VERSION ""

NS_ :

BS_:

BU_: CH DIPF DIPR ETH FC HVI HVS PARTY SDCV VEH VIRT

BO_ 1815 RCM_imuOffsets: 7 CH
 SG_ RCM_rollRateOffset m0 : 40|16@1- (0.0001,0.0) [-0.126|0.126] "rad/s"  gtw
 SG_ RCM_verticalAccelOffset m1 : 40|16@1- (0.00125,0.0) [-2.52|2.52] "m/s^2"  gtw
 SG_ RCM_lateralAccelOffset m1 : 24|16@1- (0.00125,0.0) [-2.52|2.52] "m/s^2"  gtw
 SG_ RCM_pitchRateOffset m0 : 24|16@1- (0.0001,0.0) [-0.126|0.126] "rad/s"  gtw
 SG_ RCM_yawRateOffset m0 : 8|16@1- (0.0001,0.0) [-0.126|0.126] "rad/s"  gtw
 SG_ RCM_longitudinalAccelOffset m1 : 8|16@1- (0.00125,0.0) [-2.52|2.52] "m/s^2"  gtw
 SG_ RCM_imuOffsetsIndex M : 0|1@1+ (1,0) [0|1] ""  X

BO_ 981 ESP_alertMatrix: 8 CH
 SG_ ESP_a120_rmiActive m1 : 63|1@1+ (1,0) [0|1] ""  gtw
 SG_ ESP_a180_IBSTparty2Checksum m2 : 63|1@1+ (1,0) [0|1] ""  gtw
 SG_ ESP_a060_ReLWSSWrongSensorType m0 : 63|1@1+ (1,0) [0|1] ""  gtw
 SG_ ESP_a240_LVPowerStateTimeout m3 : 63|1@1+ (1,0) [0|1] ""  gtw
 SG_ ESP_a179_IBSTparty2Timeout m2 : 62|1@1+ (1,0) [0|1] ""  gtw
 SG_ ESP_a119_hbbActive m1 : 62|1@1+ (1,0) [0|1] ""  gtw
 SG_ ESP_a059_ReLWSSNoPulsesDetected m0 : 62|1@1+ (1,0) [0|1] ""  gtw
 SG_ ESP_a239_UIodoDLC m3 : 62|1@1+ (1,0) [0|1] ""  gtw
 SG_ ESP_a118_hfcActive m1 : 61|1@1+ (1,0) [0|1] ""  gtw
 SG_ ESP_a058_ReLWSSLostSignal m0 : 61|1@1+ (1,0) [0|1] ""  gtw
 SG_ ESP_a238_UIodoTimeout m3 : 61|1@1+ (1,0) [0|1] ""  gtw
 SG_ ESP_a178_IBSTOutputRodActInvalid m2 : 61|1@1+ (1,0) [0|1] ""  gtw
 SG_ ESP_a237_vdcCommandStateInvalid m3 : 60|1@1+ (1,0) [0|1] ""  gtw
 SG_ ESP_a117_hbaActive m1 : 60|1@1+ (1,0) [0|1] ""  gtw
 SG_ ESP_a177_IBSTOutputRodDrvInvalid m2 : 60|1@1+ (1,0) [0|1] ""  gtw
 SG_ ESP_a057_ReLWSSTooManyPulses m0 : 60|1@1+ (1,0) [0|1] ""  gtw
 SG_ ESP_a056_ReLWSSMaxSpeedExceeded m0 : 59|1@1+ (1,0) [0|1] ""  gtw
 SG_ ESP_a176_IBSTEBRNotAvailable m2 : 59|1@1+ (1,0) [0|1] ""  gtw
 SG_ ESP_a236_ebrCommandStateInvalid m3 : 59|1@1+ (1,0) [0|1] ""  gtw
 SG_ ESP_a116_tsmActive m1 : 59|1@1+ (1,0) [0|1] ""  gtw
 SG_ ESP_a175_IBSTparty1Counter m2 : 58|1@1+ (1,0) [0|1] ""  gtw
 SG_ ESP_a115_ebdActive m1 : 58|1@1+ (1,0) [0|1] ""  gtw
 SG_ ESP_a055_ReLWSSLineInterruption m0 : 58|1@1+ (1,0) [0|1] ""  gtw
 SG_ ESP_a235_PMstate2Counter m3 : 58|1@1+ (1,0) [0|1] ""  gtw
 SG_ ESP_a234_PMstate2DLC m3 : 57|1@1+ (1,0) [0|1] ""  gtw
 SG_ ESP_a054_ReLWSSShortTo12V m0 : 57|1@1+ (1,0) [0|1] ""  gtw
 SG_ ESP_a174_IBSTparty1Checksum m2 : 57|1@1+ (1,0) [0|1] ""  gtw
 SG_ ESP_a114_tvdcActive m1 : 57|1@1+ (1,0) [0|1] ""  gtw
 SG_ ESP_a113_btcActive m1 : 56|1@1+ (1,0) [0|1] ""  gtw
 SG_ ESP_a233_PMstate2Checksum m3 : 56|1@1+ (1,0) [0|1] ""  gtw
 SG_ ESP_a053_ReLWSSOpenOrShortToGnd m0 : 56|1@1+ (1,0) [0|1] ""  gtw
 SG_ ESP_a173_IBSTparty1DLC m2 : 56|1@1+ (1,0) [0|1] ""  gtw
 SG_ ESP_a172_IBSTparty1Timeout m2 : 55|1@1+ (1,0) [0|1] ""  gtw
 SG_ ESP_a052_FrRWSSGeneralFault m0 : 55|1@1+ (1,0) [0|1] ""  gtw
 SG_ ESP_a112_espActive m1 : 55|1@1+ (1,0) [0|1] ""  gtw
 SG_ ESP_a232_PMstate2Timeout m3 : 55|1@1+ (1,0) [0|1] ""  gtw
 SG_ ESP_a051_FrRWSSSupplyShortToGnd m0 : 54|1@1+ (1,0) [0|1] ""  gtw
 SG_ ESP_a111_absActive m1 : 54|1@1+ (1,0) [0|1] ""  gtw
 SG_ ESP_a231_storedVINMismatch m3 : 54|1@1+ (1,0) [0|1] ""  gtw
 SG_ ESP_a171_axImplausible m2 : 54|1@1+ (1,0) [0|1] ""  gtw
 SG_ ESP_a110_rollerBenchActive m1 : 53|1@1+ (1,0) [0|1] ""  gtw
 SG_ ESP_a050_FrRWSSLargeAirGap m0 : 53|1@1+ (1,0) [0|1] ""  gtw
 SG_ ESP_a230_vinNotLearned m3 : 53|1@1+ (1,0) [0|1] ""  gtw
 SG_ ESP_a170_axSignalFrozen m2 : 53|1@1+ (1,0) [0|1] ""  gtw
 SG_ ESP_a229_GTWvinDLC m3 : 52|1@1+ (1,0) [0|1] ""  gtw
 SG_ ESP_a169_axOffsetExceeded m2 : 52|1@1+ (1,0) [0|1] ""  gtw
 SG_ ESP_a109_reserved109 m1 : 52|1@1+ (1,0) [0|1] ""  gtw
 SG_ ESP_a049_FrRWSSDirectionFault m0 : 52|1@1+ (1,0) [0|1] ""  gtw
 SG_ ESP_a048_FrRWSSVDiffFault m0 : 51|1@1+ (1,0) [0|1] ""  gtw
 SG_ ESP_a228_GTWvinTimeout m3 : 51|1@1+ (1,0) [0|1] ""  gtw
 SG_ ESP_a108_reserved108 m1 : 51|1@1+ (1,0) [0|1] ""  gtw
 SG_ ESP_a168_axRangeExceeded m2 : 51|1@1+ (1,0) [0|1] ""  gtw
 SG_ ESP_a047_FrRWSSSignalNoise m0 : 50|1@1+ (1,0) [0|1] ""  gtw
 SG_ ESP_a167_axSignalFault m2 : 50|1@1+ (1,0) [0|1] ""  gtw
 SG_ ESP_a107_reserved107 m1 : 50|1@1+ (1,0) [0|1] ""  gtw
 SG_ ESP_a227_bdwRequestActiveInvalid m3 : 50|1@1+ (1,0) [0|1] ""  gtw
 SG_ ESP_a106_vdcActuatorFault m1 : 49|1@1+ (1,0) [0|1] ""  gtw
 SG_ ESP_a226_bdwRequestInvalid m3 : 49|1@1+ (1,0) [0|1] ""  gtw
 SG_ ESP_a166_axSensorNotAvailable m2 : 49|1@1+ (1,0) [0|1] ""  gtw
 SG_ ESP_a046_FrRWSSWrongSensorType m0 : 49|1@1+ (1,0) [0|1] ""  gtw
 SG_ ESP_a165_axInvalidValue m2 : 48|1@1+ (1,0) [0|1] ""  gtw
 SG_ ESP_a045_FrRWSSNoPulsesDetected m0 : 48|1@1+ (1,0) [0|1] ""  gtw
 SG_ ESP_a225_configMismatch m3 : 48|1@1+ (1,0) [0|1] ""  gtw
 SG_ ESP_a105_ebrFault m1 : 48|1@1+ (1,0) [0|1] ""  gtw
 SG_ ESP_a104_hbcEnabled m1 : 47|1@1+ (1,0) [0|1] ""  gtw
 SG_ ESP_a224_DIvdcRightCounter m3 : 47|1@1+ (1,0) [0|1] ""  gtw
 SG_ ESP_a044_FrRWSSLostSignal m0 : 47|1@1+ (1,0) [0|1] ""  gtw
 SG_ ESP_a164_axInitFault m2 : 47|1@1+ (1,0) [0|1] ""  gtw
 SG_ ESP_a103_stabilityControlFault m1 : 46|1@1+ (1,0) [0|1] ""  gtw
 SG_ ESP_a043_FrRWSSTooManyPulses m0 : 46|1@1+ (1,0) [0|1] ""  gtw
 SG_ ESP_a163_axMaxLatency m2 : 46|1@1+ (1,0) [0|1] ""  gtw
 SG_ ESP_a223_DIvdcRightChecksum m3 : 46|1@1+ (1,0) [0|1] ""  gtw
 SG_ ESP_a162_ayImplausible m2 : 45|1@1+ (1,0) [0|1] ""  gtw
 SG_ ESP_a102_absFault m1 : 45|1@1+ (1,0) [0|1] ""  gtw
 SG_ ESP_a042_FrRWSSMaxSpeedExceeded m0 : 45|1@1+ (1,0) [0|1] ""  gtw
 SG_ ESP_a222_DIvdcRightDLC m3 : 45|1@1+ (1,0) [0|1] ""  gtw
 SG_ ESP_a221_DIvdcRightTimeout m3 : 44|1@1+ (1,0) [0|1] ""  gtw
 SG_ ESP_a101_ebdFault m1 : 44|1@1+ (1,0) [0|1] ""  gtw
 SG_ ESP_a041_FrRWSSLineInterruption m0 : 44|1@1+ (1,0) [0|1] ""  gtw
 SG_ ESP_a161_ayOffsetExceeded m2 : 44|1@1+ (1,0) [0|1] ""  gtw
 SG_ ESP_a220_DIvdcLeftCounter m3 : 43|1@1+ (1,0) [0|1] ""  gtw
 SG_ ESP_a040_FrRWSSShortTo12V m0 : 43|1@1+ (1,0) [0|1] ""  gtw
 SG_ ESP_a100_brakeTempModelDisabled m1 : 43|1@1+ (1,0) [0|1] ""  gtw
 SG_ ESP_a160_ayRangeExceeded m2 : 43|1@1+ (1,0) [0|1] ""  gtw
 SG_ ESP_a099_brakeTempModelOverheat m1 : 42|1@1+ (1,0) [0|1] ""  gtw
 SG_ ESP_a219_DIvdcLeftChecksum m3 : 42|1@1+ (1,0) [0|1] ""  gtw
 SG_ ESP_a039_FrRWSSOpenOrShortToGnd m0 : 42|1@1+ (1,0) [0|1] ""  gtw
 SG_ ESP_a159_aySignalFault m2 : 42|1@1+ (1,0) [0|1] ""  gtw
 SG_ ESP_a158_aySensorNotAvailable m2 : 41|1@1+ (1,0) [0|1] ""  gtw
 SG_ ESP_a098_vdcRefSpeedNotInit m1 : 41|1@1+ (1,0) [0|1] ""  gtw
 SG_ ESP_a218_DIvdcLeftDLC m3 : 41|1@1+ (1,0) [0|1] ""  gtw
 SG_ ESP_a038_FrLWSSGeneralFault m0 : 41|1@1+ (1,0) [0|1] ""  gtw
 SG_ ESP_a157_ayInvalidValue m2 : 40|1@1+ (1,0) [0|1] ""  gtw
 SG_ ESP_a217_DIvdcLeftTimeout m3 : 40|1@1+ (1,0) [0|1] ""  gtw
 SG_ ESP_a097_tcsRefSpeedNotInit m1 : 40|1@1+ (1,0) [0|1] ""  gtw
 SG_ ESP_a037_FrLWSSSupplyShortToGnd m0 : 40|1@1+ (1,0) [0|1] ""  gtw
 SG_ ESP_a096_chassisBusPassive m1 : 39|1@1+ (1,0) [0|1] ""  gtw
 SG_ ESP_a216_DISTorqueActualInvalid m3 : 39|1@1+ (1,0) [0|1] ""  gtw
 SG_ ESP_a156_ayInitFault m2 : 39|1@1+ (1,0) [0|1] ""  gtw
 SG_ ESP_a036_FrLWSSLargeAirGap m0 : 39|1@1+ (1,0) [0|1] ""  gtw
 SG_ ESP_a035_FrLWSSDirectionFault m0 : 38|1@1+ (1,0) [0|1] ""  gtw
 SG_ ESP_a095_chassisBusOff m1 : 38|1@1+ (1,0) [0|1] ""  gtw
 SG_ ESP_a215_DISRPMInvalid m3 : 38|1@1+ (1,0) [0|1] ""  gtw
 SG_ ESP_a155_ayMaxLatency m2 : 38|1@1+ (1,0) [0|1] ""  gtw
 SG_ ESP_a034_FrLWSSVDiffFault m0 : 37|1@1+ (1,0) [0|1] ""  gtw
 SG_ ESP_a214_DISTorqueCommandInvalid m3 : 37|1@1+ (1,0) [0|1] ""  gtw
 SG_ ESP_a094_partyBusPassive m1 : 37|1@1+ (1,0) [0|1] ""  gtw
 SG_ ESP_a154_RCMInertial2Counter m2 : 37|1@1+ (1,0) [0|1] ""  gtw
 SG_ ESP_a153_RCMInertial2Checksum m2 : 36|1@1+ (1,0) [0|1] ""  gtw
 SG_ ESP_a093_partyBusOff m1 : 36|1@1+ (1,0) [0|1] ""  gtw
 SG_ ESP_a033_FrLWSSSignalNoise m0 : 36|1@1+ (1,0) [0|1] ""  gtw
 SG_ ESP_a213_DIStorqueCounter m3 : 36|1@1+ (1,0) [0|1] ""  gtw
 SG_ ESP_a032_FrLWSSWrongSensorType m0 : 35|1@1+ (1,0) [0|1] ""  gtw
 SG_ ESP_a092_CANOvervoltage m1 : 35|1@1+ (1,0) [0|1] ""  gtw
 SG_ ESP_a152_RCMInertial2DLC m2 : 35|1@1+ (1,0) [0|1] ""  gtw
 SG_ ESP_a212_DIStorqueChecksum m3 : 35|1@1+ (1,0) [0|1] ""  gtw
 SG_ ESP_a031_FrLWSSNoPulsesDetected m0 : 34|1@1+ (1,0) [0|1] ""  gtw
 SG_ ESP_a091_CANUndervoltage m1 : 34|1@1+ (1,0) [0|1] ""  gtw
 SG_ ESP_a151_RCMInertial2Timeout m2 : 34|1@1+ (1,0) [0|1] ""  gtw
 SG_ ESP_a211_DIStorqueDLC m3 : 34|1@1+ (1,0) [0|1] ""  gtw
 SG_ ESP_a030_FrLWSSLostSignal m0 : 33|1@1+ (1,0) [0|1] ""  gtw
 SG_ ESP_a090_vdcContinuousControl m1 : 33|1@1+ (1,0) [0|1] ""  gtw
 SG_ ESP_a210_DIStorqueTimeout m3 : 33|1@1+ (1,0) [0|1] ""  gtw
 SG_ ESP_a150_yawImplausible m2 : 33|1@1+ (1,0) [0|1] ""  gtw
 SG_ ESP_a149_yawInvalidSign m2 : 32|1@1+ (1,0) [0|1] ""  gtw
 SG_ ESP_a089_absNoPressureIncrease m1 : 32|1@1+ (1,0) [0|1] ""  gtw
 SG_ ESP_a209_DITorqueActualInvalid m3 : 32|1@1+ (1,0) [0|1] ""  gtw
 SG_ ESP_a029_FrLWSSTooManyPulses m0 : 32|1@1+ (1,0) [0|1] ""  gtw
 SG_ ESP_a148_yawSignalFault m2 : 31|1@1+ (1,0) [0|1] ""  gtw
 SG_ ESP_a208_DIRPMInvalid m3 : 31|1@1+ (1,0) [0|1] ""  gtw
 SG_ ESP_a088_absContinuousControl m1 : 31|1@1+ (1,0) [0|1] ""  gtw
 SG_ ESP_a028_FrLWSSMaxSpeedExceeded m0 : 31|1@1+ (1,0) [0|1] ""  gtw
 SG_ ESP_a207_DITorqueCommandInvalid m3 : 30|1@1+ (1,0) [0|1] ""  gtw
 SG_ ESP_a087_BrakeSwitchImplausible3 m1 : 30|1@1+ (1,0) [0|1] ""  gtw
 SG_ ESP_a027_FrLWSSLineInterruption m0 : 30|1@1+ (1,0) [0|1] ""  gtw
 SG_ ESP_a147_yawSensorNotAvailable m2 : 30|1@1+ (1,0) [0|1] ""  gtw
 SG_ ESP_a146_yawInvalidValue m2 : 29|1@1+ (1,0) [0|1] ""  gtw
 SG_ ESP_a026_FrLWSSShortTo12V m0 : 29|1@1+ (1,0) [0|1] ""  gtw
 SG_ ESP_a086_BrakeSwitchImplausible1 m1 : 29|1@1+ (1,0) [0|1] ""  gtw
 SG_ ESP_a206_DItorqueCounter m3 : 29|1@1+ (1,0) [0|1] ""  gtw
 SG_ ESP_a085_BrakeSwitchStuckHigh m1 : 28|1@1+ (1,0) [0|1] ""  gtw
 SG_ ESP_a205_DItorqueChecksum m3 : 28|1@1+ (1,0) [0|1] ""  gtw
 SG_ ESP_a025_FrLWSSOpenOrShortToGnd m0 : 28|1@1+ (1,0) [0|1] ""  gtw
 SG_ ESP_a145_yawInitFault m2 : 28|1@1+ (1,0) [0|1] ""  gtw
 SG_ ESP_a084_BrakeFluidReservoirLow m1 : 27|1@1+ (1,0) [0|1] ""  gtw
 SG_ ESP_a144_yawMaxLatency m2 : 27|1@1+ (1,0) [0|1] ""  gtw
 SG_ ESP_a024_WSSReverseCurrent m0 : 27|1@1+ (1,0) [0|1] ""  gtw
 SG_ ESP_a204_DItorqueDLC m3 : 27|1@1+ (1,0) [0|1] ""  gtw
 SG_ ESP_a083_PMCSensorFault m1 : 26|1@1+ (1,0) [0|1] ""  gtw
 SG_ ESP_a143_RCMInertial1Counter m2 : 26|1@1+ (1,0) [0|1] ""  gtw
 SG_ ESP_a203_DItorqueTimeout m3 : 26|1@1+ (1,0) [0|1] ""  gtw
 SG_ ESP_a263_epblStatusCounter m4 : 26|1@1+ (1,0) [0|1] ""  gtw
 SG_ ESP_a023_WSSSeveralSuspected m0 : 26|1@1+ (1,0) [0|1] ""  gtw
 SG_ ESP_a142_RCMInertial1Checksum m2 : 25|1@1+ (1,0) [0|1] ""  gtw
 SG_ ESP_a262_epblStatusDLC m4 : 25|1@1+ (1,0) [0|1] ""  gtw
 SG_ ESP_a082_PMCSensorOffsetHigh m1 : 25|1@1+ (1,0) [0|1] ""  gtw
 SG_ ESP_a202_accelPedalInvalid m3 : 25|1@1+ (1,0) [0|1] ""  gtw
 SG_ ESP_a022_WSSDirectionFault m0 : 25|1@1+ (1,0) [0|1] ""  gtw
 SG_ ESP_a261_epblStatusChecksum m4 : 24|1@1+ (1,0) [0|1] ""  gtw
 SG_ ESP_a141_RCMInertial1DLC m2 : 24|1@1+ (1,0) [0|1] ""  gtw
 SG_ ESP_a081_PressureSensorShort m1 : 24|1@1+ (1,0) [0|1] ""  gtw
 SG_ ESP_a021_WSSGeneralVDiffFault m0 : 24|1@1+ (1,0) [0|1] ""  gtw
 SG_ ESP_a201_reverseGearStuckLow m3 : 24|1@1+ (1,0) [0|1] ""  gtw
 SG_ ESP_a080_ReRWSSGeneralFault m1 : 23|1@1+ (1,0) [0|1] ""  gtw
 SG_ ESP_a020_WSSGenericTempFault m0 : 23|1@1+ (1,0) [0|1] ""  gtw
 SG_ ESP_a260_epblStatusTimeout m4 : 23|1@1+ (1,0) [0|1] ""  gtw
 SG_ ESP_a200_reverseGearStuckHigh m3 : 23|1@1+ (1,0) [0|1] ""  gtw
 SG_ ESP_a140_RCMInertial1Timeout m2 : 23|1@1+ (1,0) [0|1] ""  gtw
 SG_ ESP_a259_epbmStatusCounter m4 : 22|1@1+ (1,0) [0|1] ""  gtw
 SG_ ESP_a199_DIsystemStatusCounter m3 : 22|1@1+ (1,0) [0|1] ""  gtw
 SG_ ESP_a139_steeringAngleWrongSign m2 : 22|1@1+ (1,0) [0|1] ""  gtw
 SG_ ESP_a019_WSSSignRearAxle m0 : 22|1@1+ (1,0) [0|1] ""  gtw
 SG_ ESP_a079_ReRWSSSupplyShortToGnd m1 : 22|1@1+ (1,0) [0|1] ""  gtw
 SG_ ESP_a138_steeringAngleImplaus m2 : 21|1@1+ (1,0) [0|1] ""  gtw
 SG_ ESP_a078_ReRWSSLargeAirGap m1 : 21|1@1+ (1,0) [0|1] ""  gtw
 SG_ ESP_a198_DIsystemStatusChecksum m3 : 21|1@1+ (1,0) [0|1] ""  gtw
 SG_ ESP_a018_WSSSignFrontAxle m0 : 21|1@1+ (1,0) [0|1] ""  gtw
 SG_ ESP_a258_epbmStatusDLC m4 : 21|1@1+ (1,0) [0|1] ""  gtw
 SG_ ESP_a077_ReRWSSDirectionFault m1 : 20|1@1+ (1,0) [0|1] ""  gtw
 SG_ ESP_a197_DIsystemStatusDLC m3 : 20|1@1+ (1,0) [0|1] ""  gtw
 SG_ ESP_a137_steeringOffsetTooLarge m2 : 20|1@1+ (1,0) [0|1] ""  gtw
 SG_ ESP_a017_netOvervoltage m0 : 20|1@1+ (1,0) [0|1] ""  gtw
 SG_ ESP_a257_epbmStatusChecksum m4 : 20|1@1+ (1,0) [0|1] ""  gtw
 SG_ ESP_a196_DIsystemStatusTimeout m3 : 19|1@1+ (1,0) [0|1] ""  gtw
 SG_ ESP_a136_steeringAngleFrozen m2 : 19|1@1+ (1,0) [0|1] ""  gtw
 SG_ ESP_a016_12VSystemOvervoltage m0 : 19|1@1+ (1,0) [0|1] ""  gtw
 SG_ ESP_a256_epbmStatusTimeout m4 : 19|1@1+ (1,0) [0|1] ""  gtw
 SG_ ESP_a076_ReRWSSVDiffFault m1 : 19|1@1+ (1,0) [0|1] ""  gtw
 SG_ ESP_a015_12VSupplyOvervoltage m0 : 18|1@1+ (1,0) [0|1] ""  gtw
 SG_ ESP_a135_steeringAngleNoCenter m2 : 18|1@1+ (1,0) [0|1] ""  gtw
 SG_ ESP_a195_ptcStateInvalid m3 : 18|1@1+ (1,0) [0|1] ""  gtw
 SG_ ESP_a255_vdcWhlSlipLimReRInvalid m4 : 18|1@1+ (1,0) [0|1] ""  gtw
 SG_ ESP_a075_ReRWSSSignalNoise m1 : 18|1@1+ (1,0) [0|1] ""  gtw
 SG_ ESP_a074_ReRWSSWrongSensorType m1 : 17|1@1+ (1,0) [0|1] ""  gtw
 SG_ ESP_a254_vdcWhlSlipLimReLInvalid m4 : 17|1@1+ (1,0) [0|1] ""  gtw
 SG_ ESP_a134_steeringAngleInvalid m2 : 17|1@1+ (1,0) [0|1] ""  gtw
 SG_ ESP_a014_WSSSupplyUndervoltage m0 : 17|1@1+ (1,0) [0|1] ""  gtw
 SG_ ESP_a194_DIchassiControlCounter m3 : 17|1@1+ (1,0) [0|1] ""  gtw
 SG_ ESP_a253_vdcWhlSlipLimFrRInvalid m4 : 16|1@1+ (1,0) [0|1] ""  gtw
 SG_ ESP_a073_ReRWSSNoPulsesDetected m1 : 16|1@1+ (1,0) [0|1] ""  gtw
 SG_ ESP_a133_EPAS3PsysStatusCounter m2 : 16|1@1+ (1,0) [0|1] ""  gtw
 SG_ ESP_a193_DIchassiControlChecksum m3 : 16|1@1+ (1,0) [0|1] ""  gtw
 SG_ ESP_a013_valveRelayUndervoltage m0 : 16|1@1+ (1,0) [0|1] ""  gtw
 SG_ ESP_a072_ReRWSSLostSignal m1 : 15|1@1+ (1,0) [0|1] ""  gtw
 SG_ ESP_a012_netUndervoltage m0 : 15|1@1+ (1,0) [0|1] ""  gtw
 SG_ ESP_a132_EPAS3PsysStatusChecksum m2 : 15|1@1+ (1,0) [0|1] ""  gtw
 SG_ ESP_a252_vdcWhlSlipLimFrLInvalid m4 : 15|1@1+ (1,0) [0|1] ""  gtw
 SG_ ESP_a192_DIchassiControlDLC m3 : 15|1@1+ (1,0) [0|1] ""  gtw
 SG_ ESP_a131_EPAS3PsysStatusDLC m2 : 14|1@1+ (1,0) [0|1] ""  gtw
 SG_ ESP_a251_vdcBrkeTrqTarReRInvalid m4 : 14|1@1+ (1,0) [0|1] ""  gtw
 SG_ ESP_a191_DIchassiControlTimeout m3 : 14|1@1+ (1,0) [0|1] ""  gtw
 SG_ ESP_a071_ReRWSSTooManyPulses m1 : 14|1@1+ (1,0) [0|1] ""  gtw
 SG_ ESP_a011_12VSystemUndervoltage m0 : 14|1@1+ (1,0) [0|1] ""  gtw
 SG_ ESP_a070_ReRWSSMaxSpeedExceeded m1 : 13|1@1+ (1,0) [0|1] ""  gtw
 SG_ ESP_a010_12VUndervoltage m0 : 13|1@1+ (1,0) [0|1] ""  gtw
 SG_ ESP_a250_vdcBrkeTrqTarReLInvalid m4 : 13|1@1+ (1,0) [0|1] ""  gtw
 SG_ ESP_a190_DIbtcRequestCounter m3 : 13|1@1+ (1,0) [0|1] ""  gtw
 SG_ ESP_a130_EPAS3PsysStatusTimeout m2 : 13|1@1+ (1,0) [0|1] ""  gtw
 SG_ ESP_a189_DIbtcRequestChecksum m3 : 12|1@1+ (1,0) [0|1] ""  gtw
 SG_ ESP_a069_ReRWSSLineInterruption m1 : 12|1@1+ (1,0) [0|1] ""  gtw
 SG_ ESP_a009_12VHardUndervoltage m0 : 12|1@1+ (1,0) [0|1] ""  gtw
 SG_ ESP_a129_reserved129 m2 : 12|1@1+ (1,0) [0|1] ""  gtw
 SG_ ESP_a249_vdcBrkeTrqTarFrRInvalid m4 : 12|1@1+ (1,0) [0|1] ""  gtw
 SG_ ESP_a248_vdcBrkeTrqTarFrLInvalid m4 : 11|1@1+ (1,0) [0|1] ""  gtw
 SG_ ESP_a188_DIbtcRequestDLC m3 : 11|1@1+ (1,0) [0|1] ""  gtw
 SG_ ESP_a008_pumpMotor12VsupplyLow m0 : 11|1@1+ (1,0) [0|1] ""  gtw
 SG_ ESP_a128_reserved128 m2 : 11|1@1+ (1,0) [0|1] ""  gtw
 SG_ ESP_a068_ReRWSSShortTo12V m1 : 11|1@1+ (1,0) [0|1] ""  gtw
 SG_ ESP_a067_ReRWSSOpenOrShortToGnd m1 : 10|1@1+ (1,0) [0|1] ""  gtw
 SG_ ESP_a007_pumpMotorFault m0 : 10|1@1+ (1,0) [0|1] ""  gtw
 SG_ ESP_a187_DIbtcRequestTimeout m3 : 10|1@1+ (1,0) [0|1] ""  gtw
 SG_ ESP_a247_VCFRONTsensorDLC m4 : 10|1@1+ (1,0) [0|1] ""  gtw
 SG_ ESP_a127_reserved127 m2 : 10|1@1+ (1,0) [0|1] ""  gtw
 SG_ ESP_a186_IBSTBrakeAppliedInvalid m3 : 9|1@1+ (1,0) [0|1] ""  gtw
 SG_ ESP_a066_ReLWSSGeneralFault m1 : 9|1@1+ (1,0) [0|1] ""  gtw
 SG_ ESP_a246_VCFRONTsensorTimeout m4 : 9|1@1+ (1,0) [0|1] ""  gtw
 SG_ ESP_a126_reserved126 m2 : 9|1@1+ (1,0) [0|1] ""  gtw
 SG_ ESP_a006_USVValvesFault m0 : 9|1@1+ (1,0) [0|1] ""  gtw
 SG_ ESP_a245_LVGoingDownStateInvalid m4 : 8|1@1+ (1,0) [0|1] ""  gtw
 SG_ ESP_a065_ReLWSSSupplyShortToGnd m1 : 8|1@1+ (1,0) [0|1] ""  gtw
 SG_ ESP_a005_HSVValvesFault m0 : 8|1@1+ (1,0) [0|1] ""  gtw
 SG_ ESP_a125_reserved125 m2 : 8|1@1+ (1,0) [0|1] ""  gtw
 SG_ ESP_a185_IBSTFeedforwardBackup m3 : 8|1@1+ (1,0) [0|1] ""  gtw
 SG_ ESP_a244_LVOffStateInvalid m4 : 7|1@1+ (1,0) [0|1] ""  gtw
 SG_ ESP_a004_inletValvesFault m0 : 7|1@1+ (1,0) [0|1] ""  gtw
 SG_ ESP_a064_ReLWSSLargeAirGap m1 : 7|1@1+ (1,0) [0|1] ""  gtw
 SG_ ESP_a184_IBSTpRunoutInvalid m3 : 7|1@1+ (1,0) [0|1] ""  gtw
 SG_ ESP_a124_ebrSkidActive m2 : 7|1@1+ (1,0) [0|1] ""  gtw
 SG_ ESP_a063_ReLWSSDirectionFault m1 : 6|1@1+ (1,0) [0|1] ""  gtw
 SG_ ESP_a243_LVPowerStateCounter m4 : 6|1@1+ (1,0) [0|1] ""  gtw
 SG_ ESP_a003_outletValvesFault m0 : 6|1@1+ (1,0) [0|1] ""  gtw
 SG_ ESP_a123_ebrActive m2 : 6|1@1+ (1,0) [0|1] ""  gtw
 SG_ ESP_a183_IBSTStatusOff m3 : 6|1@1+ (1,0) [0|1] ""  gtw
 SG_ ESP_a062_ReLWSSVDiffFault m1 : 5|1@1+ (1,0) [0|1] ""  gtw
 SG_ ESP_a182_IBSTparty2Counter m3 : 5|1@1+ (1,0) [0|1] ""  gtw
 SG_ ESP_a002_valvesGenericFault m0 : 5|1@1+ (1,0) [0|1] ""  gtw
 SG_ ESP_a122_bdwActive m2 : 5|1@1+ (1,0) [0|1] ""  gtw
 SG_ ESP_a242_LVPowerStateDLC m4 : 5|1@1+ (1,0) [0|1] ""  gtw
 SG_ ESP_a001_ecuGenericFault m0 : 4|1@1+ (1,0) [0|1] ""  gtw
 SG_ ESP_a121_regenTcActive m2 : 4|1@1+ (1,0) [0|1] ""  gtw
 SG_ ESP_a241_LVPowerStateChecksum m4 : 4|1@1+ (1,0) [0|1] ""  gtw
 SG_ ESP_a061_ReLWSSSignalNoise m1 : 4|1@1+ (1,0) [0|1] ""  gtw
 SG_ ESP_a181_IBSTparty2DLC m3 : 4|1@1+ (1,0) [0|1] ""  gtw
 SG_ ESP_matrixIndex M : 0|4@1+ (1,0) [0|15] ""  gtw

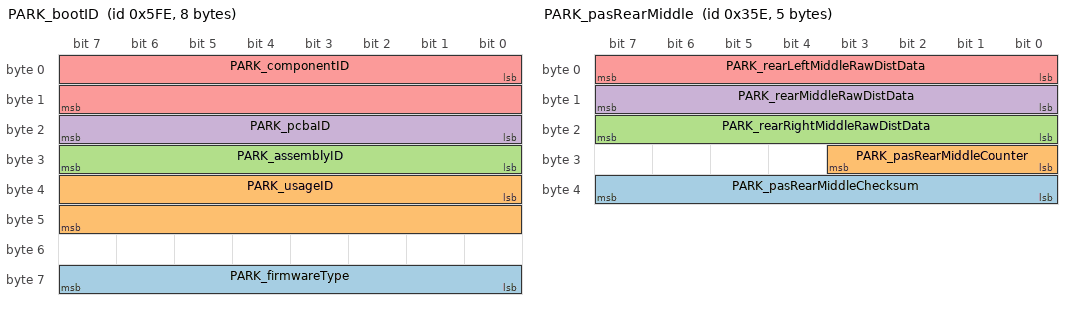
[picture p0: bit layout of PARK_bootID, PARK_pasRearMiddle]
BO_ 1534 PARK_bootID: 8 CH
 SG_ PARK_firmwareType : 56|8@1+ (1,0) [0|255] ""  X
 SG_ PARK_usageID : 32|16@1+ (1,0) [0|65535] ""  X
 SG_ PARK_assemblyID : 24|8@1+ (1,0) [0|255] ""  X
 SG_ PARK_pcbaID : 16|8@1+ (1,0) [0|255] ""  X
 SG_ PARK_componentID : 0|16@1+ (1,0) [0|65535] ""  X

BO_ 659 UI_chassisControl: 8 CH
 SG_ UI_chassisControlChecksum : 56|8@1+ (1,0) [0|255] ""  epas3s
 SG_ UI_chassisControlCounter : 52|4@1+ (1,0) [0|15] ""  epas3s
 SG_ UI_selfParkTune : 48|4@1+ (1,0) [0|15] ""  das
 SG_ UI_redLightStopSignEnable : 46|2@1+ (1,0) [0|3] ""  das
 SG_ UI_pedalSafetyEnable : 44|2@1+ (1,0) [0|3] ""  das
 SG_ UI_ldwEnable : 42|2@1+ (1,0) [0|3] ""  das
 SG_ UI_latControlEnable : 40|2@1+ (1,0) [0|3] ""  das
 SG_ UI_fcwSensitivity : 38|2@1+ (1,0) [0|3] ""  das
 SG_ UI_fcwEnable : 36|2@1+ (1,0) [0|3] ""  das
 SG_ UI_bsdEnable : 34|2@1+ (1,0) [0|3] ""  das
 SG_ UI_autoLaneChangeEnable : 32|2@1+ (1,0) [0|3] ""  das
 SG_ UI_autoParkRequest : 28|4@1+ (1,0) [0|15] ""  das
 SG_ UI_rebootAutopilot : 27|1@1+ (1,0) [0|1] ""  aps
 SG_ UI_ahlbEnable : 24|2@1+ (1,0) [0|3] ""  das
 SG_ UI_aesEnable : 22|2@1+ (1,0) [0|3] ""  das
 SG_ UI_aebEnable : 20|2@1+ (1,0) [0|3] ""  das
 SG_ UI_accOvertakeEnable : 18|2@1+ (1,0) [0|3] ""  das
 SG_ UI_dasDebugEnable : 17|1@1+ (1,0) [0|1] ""  das
 SG_ UI_distanceUnits : 16|1@1+ (1,0) [0|1] ""  X
 SG_ UI_suspensionLevelRequest : 13|3@1+ (1,0) [0|7] ""  tas
 SG_ UI_trailerMode : 12|1@1+ (1,0) [0|1] ""  das
 SG_ UI_zeroSpeedConfirmed : 10|2@1+ (1,0) [0|3] ""  X
 SG_ UI_winchModeRequest : 8|2@1+ (1,0) [0|2] ""  X
 SG_ UI_narrowGarages : 7|1@1+ (1,0) [0|1] ""  das
 SG_ UI_parkBrakeRequest : 5|2@1+ (1,0) [0|3] ""  X
 SG_ UI_tractionControlMode : 2|3@1+ (1,0) [0|5] ""  X
 SG_ UI_steeringTuneRequest : 0|2@1+ (1,0) [0|2] ""  epas3s

BO_ 862 PARK_pasRearMiddle: 5 CH
 SG_ PARK_pasRearMiddleChecksum : 32|8@1+ (1,0) [0|255] ""  X
 SG_ PARK_pasRearMiddleCounter : 24|4@1+ (1,0) [0|15] ""  das
 SG_ PARK_rearRightMiddleRawDistData : 16|8@1+ (1,0) [0|255] "cm"  das
 SG_ PARK_rearMiddleRawDistData : 8|8@1+ (1,0) [0|255] "cm"  das
 SG_ PARK_rearLeftMiddleRawDistData : 0|8@1+ (1,0) [0|255] "cm"  das

BO_ 1631 TPMS_udsResponse: 8 CH
 SG_ TPMS_udsResponseData : 7|64@0+ (1,0) [0|18446744073709551615] ""  gtw

BO_ 1801 DBG_IsotermAP: 8 CH
 SG_ DBG_IsotermAP : 7|64@0+ (1,0) [0|18446744073709551615] ""  das

BO_ 917 OCS1P_alertMatrix: 8 CH
 SG_ OCS1P_w142_tempHumidityInvalid m2 : 25|1@1+ (1,0) [0|1] ""  gtw
 SG_ OCS1P_w141_humidityInvalidCalib m2 : 24|1@1+ (1,0) [0|1] ""  gtw
 SG_ OCS1P_w140_tempInvalidCalib m2 : 23|1@1+ (1,0) [0|1] ""  gtw
 SG_ OCS1P_w139_seatbackSelfDutyHigh m2 : 22|1@1+ (1,0) [0|1] ""  gtw
 SG_ OCS1P_w138_seatbackSelfDutyLow m2 : 21|1@1+ (1,0) [0|1] ""  gtw
 SG_ OCS1P_w137_cushionSelfDutyHigh m2 : 20|1@1+ (1,0) [0|1] ""  gtw
 SG_ OCS1P_w136_cushionSelfDutyLow m2 : 19|1@1+ (1,0) [0|1] ""  gtw
 SG_ OCS1P_w135_tempNoCalib m2 : 18|1@1+ (1,0) [0|1] ""  gtw
 SG_ OCS1P_w134_uninitializedCalib m2 : 17|1@1+ (1,0) [0|1] ""  gtw
 SG_ OCS1P_w133_sandwichBadCalib m2 : 16|1@1+ (1,0) [0|1] ""  gtw
 SG_ OCS1P_w132_seatbackSelfNoCalib m2 : 15|1@1+ (1,0) [0|1] ""  gtw
 SG_ OCS1P_w131_cushionSelfNoCalib m2 : 14|1@1+ (1,0) [0|1] ""  gtw
 SG_ OCS1P_w130_sandwichNoCalib m2 : 13|1@1+ (1,0) [0|1] ""  gtw
 SG_ OCS1P_w129_seatbackSelfShort m2 : 12|1@1+ (1,0) [0|1] ""  gtw
 SG_ OCS1P_w128_seatbackSelfLow m2 : 11|1@1+ (1,0) [0|1] ""  gtw
 SG_ OCS1P_w127_seatbackSelfOpen m2 : 10|1@1+ (1,0) [0|1] ""  gtw
 SG_ OCS1P_w126_cushionSelfShort m2 : 9|1@1+ (1,0) [0|1] ""  gtw
 SG_ OCS1P_w125_cushionSelfLow m2 : 8|1@1+ (1,0) [0|1] ""  gtw
 SG_ OCS1P_w124_cushionSelfOpen m2 : 7|1@1+ (1,0) [0|1] ""  gtw
 SG_ OCS1P_w123_sandwichShort m2 : 6|1@1+ (1,0) [0|1] ""  gtw
 SG_ OCS1P_w122_sandwichLow m2 : 5|1@1+ (1,0) [0|1] ""  gtw
 SG_ OCS1P_w121_sandwichOpen m2 : 4|1@1+ (1,0) [0|1] ""  gtw
 SG_ OCS1P_matrixIndex M : 0|4@1+ (1,0) [0|15] ""  gtw

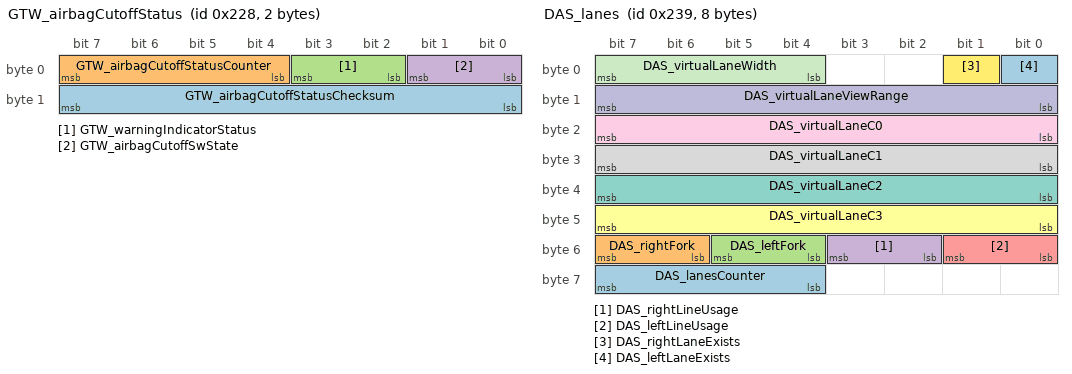
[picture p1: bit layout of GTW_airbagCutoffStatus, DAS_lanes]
BO_ 552 GTW_airbagCutoffStatus: 2 CH
 SG_ GTW_airbagCutoffStatusChecksum : 8|8@1+ (1,0) [0|255] ""  rcm
 SG_ GTW_airbagCutoffStatusCounter : 4|4@1+ (1,0) [0|15] ""  rcm
 SG_ GTW_warningIndicatorStatus : 2|2@1+ (1,0) [0|3] ""  rcm
 SG_ GTW_airbagCutoffSwState : 0|2@1+ (1,0) [0|2] ""  rcm

BO_ 811 APS_warningMatrix0: 8 CH
 SG_ APS_w064_epasMia : 63|1@1+ (1,0) [0|1] ""  gtw
 SG_ APS_w063_parkVersionMismatch : 62|1@1+ (1,0) [0|1] ""  gtw
 SG_ APS_w062_radcAlignment : 61|1@1+ (1,0) [0|1] ""  gtw
 SG_ APS_w061_tasMia : 60|1@1+ (1,0) [0|1] ""  gtw
 SG_ APS_w060_fcw_event : 59|1@1+ (1,0) [0|1] ""  gtw
 SG_ APS_w059_parkMia : 58|1@1+ (1,0) [0|1] ""  gtw
 SG_ APS_w058_epbMia : 57|1@1+ (1,0) [0|1] ""  gtw
 SG_ APS_w057_mcuMia : 56|1@1+ (1,0) [0|1] ""  gtw
 SG_ APS_w056_diMia : 55|1@1+ (1,0) [0|1] ""  gtw
 SG_ APS_w055_radcVersionMismatch : 54|1@1+ (1,0) [0|1] ""  gtw
 SG_ APS_w054_camAutofix : 53|1@1+ (1,0) [0|1] ""  gtw
 SG_ APS_w053_radcCommIssue : 52|1@1+ (1,0) [0|1] ""  gtw
 SG_ APS_w052_radcSensorIssue : 51|1@1+ (1,0) [0|1] ""  gtw
 SG_ APS_w051_radcEcuIssue : 50|1@1+ (1,0) [0|1] ""  gtw
 SG_ APS_w050_aeb_event : 49|1@1+ (1,0) [0|1] ""  gtw
 SG_ APS_w049_eyeqVersionMismatch : 48|1@1+ (1,0) [0|1] ""  gtw
 SG_ APS_w048_DAS_Features_Disabled : 47|1@1+ (1,0) [0|1] ""  gtw
 SG_ APS_w047_edrEvent : 46|1@1+ (1,0) [0|1] ""  gtw
 SG_ APS_w046_eepromRecordAbsent : 45|1@1+ (1,0) [0|1] ""  gtw
 SG_ APS_w045_radMia : 44|1@1+ (1,0) [0|1] ""  gtw
 SG_ APS_w044_appMobileyeFailure : 43|1@1+ (1,0) [0|1] ""  gtw
 SG_ APS_w043_camLongRunTime : 42|1@1+ (1,0) [0|1] ""  gtw
 SG_ APS_w042_autopilotAborting : 41|1@1+ (1,0) [0|1] ""  gtw
 SG_ APS_w041_autopilotRateSaturated : 40|1@1+ (1,0) [0|1] ""  gtw
 SG_ APS_w040_autopilotAngleSaturated : 39|1@1+ (1,0) [0|1] ""  gtw
 SG_ APS_w039_sdm_rcm_Mia : 38|1@1+ (1,0) [0|1] ""  gtw
 SG_ APS_w038_camFailure : 37|1@1+ (1,0) [0|1] ""  gtw
 SG_ APS_w037_camTacIssue : 36|1@1+ (1,0) [0|1] ""  gtw
 SG_ APS_w036_bdyMia : 35|1@1+ (1,0) [0|1] ""  gtw
 SG_ APS_w035_espMia : 34|1@1+ (1,0) [0|1] ""  gtw
 SG_ APS_w034_sccmMia : 33|1@1+ (1,0) [0|1] ""  gtw
 SG_ APS_w033_gtwMia : 32|1@1+ (1,0) [0|1] ""  gtw
 SG_ APS_w032_canTxError : 31|1@1+ (1,0) [0|1] ""  gtw
 SG_ APS_w031_canRxError : 30|1@1+ (1,0) [0|1] ""  gtw
 SG_ APS_w030_Heater_Issue : 29|1@1+ (1,0) [0|1] ""  gtw
 SG_ APS_w029_spi_tx_error : 28|1@1+ (1,0) [0|1] ""  gtw
 SG_ APS_w028_spi_rx_error : 27|1@1+ (1,0) [0|1] ""  gtw
 SG_ APS_w027_ECU_Reset_Fault : 26|1@1+ (1,0) [0|1] ""  gtw
 SG_ APS_w026_ECU_timingIssue : 25|1@1+ (1,0) [0|1] ""  gtw
 SG_ APS_w025_LC_Steering_Override : 24|1@1+ (1,0) [0|1] ""  gtw
 SG_ APS_w024_ECU_Watchdog_Reset : 23|1@1+ (1,0) [0|1] ""  gtw
 SG_ APS_w023_ECU_Cam_Statemismatc : 22|1@1+ (1,0) [0|1] ""  gtw
 SG_ APS_w022_ECU_EEPROM_Failure : 21|1@1+ (1,0) [0|1] ""  gtw
 SG_ APS_w021_ECU_Temperature_Issue : 20|1@1+ (1,0) [0|1] ""  gtw
 SG_ APS_w020_ECU_checkstopError : 19|1@1+ (1,0) [0|1] ""  gtw
 SG_ APS_w019_ECU_Stack_Overflow : 18|1@1+ (1,0) [0|1] ""  gtw
 SG_ APS_w018_ECU_Power_Issue : 17|1@1+ (1,0) [0|1] ""  gtw
 SG_ APS_w017_Cam_Msg_MIA : 16|1@1+ (1,0) [0|1] ""  gtw
 SG_ APS_w016_aeb_e_event : 15|1@1+ (1,0) [0|1] ""  gtw
 SG_ APS_w015_Camera_Failsafes : 14|1@1+ (1,0) [0|1] ""  gtw
 SG_ APS_w014_swAssert : 13|1@1+ (1,0) [0|1] ""  gtw
 SG_ APS_w013_Cam_Watchdog : 12|1@1+ (1,0) [0|1] ""  gtw
 SG_ APS_w012_Cam_BootFailure : 11|1@1+ (1,0) [0|1] ""  gtw
 SG_ APS_w011_scaEvent : 10|1@1+ (1,0) [0|1] ""  gtw
 SG_ APS_w010_radcCalibIssue : 9|1@1+ (1,0) [0|1] ""  gtw
 SG_ APS_w009_aebFault : 8|1@1+ (1,0) [0|1] ""  gtw
 SG_ APS_w008_parkDisabled : 7|1@1+ (1,0) [0|1] ""  gtw
 SG_ APS_w007_ahlbDisabled : 6|1@1+ (1,0) [0|1] ""  gtw
 SG_ APS_w006_aebCancelled : 5|1@1+ (1,0) [0|1] ""  gtw
 SG_ APS_w005_fcwCancelled : 4|1@1+ (1,0) [0|1] ""  gtw
 SG_ APS_w004_accDisabled : 3|1@1+ (1,0) [0|1] ""  gtw
 SG_ APS_w003_isaDisabled : 2|1@1+ (1,0) [0|1] ""  gtw
 SG_ APS_w002_ldwDisabled : 1|1@1+ (1,0) [0|1] ""  gtw
 SG_ APS_w001_DEPRECATED : 0|1@1+ (1,0) [0|1] ""  gtw

BO_ 569 DAS_lanes: 8 CH
 SG_ DAS_lanesCounter : 60|4@1+ (1,0) [0|15] ""  aps
 SG_ DAS_rightFork : 54|2@1+ (1,0) [0|3] ""  aps
 SG_ DAS_leftFork : 52|2@1+ (1,0) [0|3] ""  aps
 SG_ DAS_rightLineUsage : 50|2@1+ (1,0) [0|3] ""  aps
 SG_ DAS_leftLineUsage : 48|2@1+ (1,0) [0|3] ""  aps
 SG_ DAS_virtualLaneC3 : 40|8@1+ (2.4e-07,-3e-05) [-3e-05|3e-05] "m-2"  aps
 SG_ DAS_virtualLaneC2 : 32|8@1+ (2e-05,-0.0025) [-0.0025|0.0025] "m-1"  aps
 SG_ DAS_virtualLaneC1 : 24|8@1+ (0.0016,-0.2) [-0.2|0.2] "rad"  aps
 SG_ DAS_virtualLaneC0 : 16|8@1+ (0.035,-3.5) [-3.5|3.5] "m"  aps
 SG_ DAS_virtualLaneViewRange : 8|8@1+ (1,0) [0|160] "m"  aps
 SG_ DAS_virtualLaneWidth : 4|4@1+ (0.3125,2) [2|7] "m"  aps
 SG_ DAS_rightLaneExists : 1|1@1+ (1,0) [0|1] ""  aps
 SG_ DAS_leftLaneExists : 0|1@1+ (1,0) [0|1] ""  aps

BO_ 586 DAS_visualDebug: 8 CH
 SG_ DAS_rearVehDetectedThisCycle : 60|1@1+ (1,0) [0|1] ""  aps
 SG_ DAS_ulcType : 58|2@1+ (1,0) [0|2] ""  aps
 SG_ DAS_behaviorType : 56|2@1+ (1,0) [0|3] ""  aps
 SG_ DAS_ulcInProgress : 52|1@1+ (1,0) [0|1] ""  aps
 SG_ DAS_accSmartSpeedState : 49|3@1+ (1,0) [0|7] ""  aps
 SG_ DAS_accSmartSpeedActive : 48|1@1+ (1,0) [0|1] ""  aps
 SG_ DAS_navDistance : 40|8@1+ (100,0) [0|25500] "km"  aps
 SG_ DAS_navAvailable : 39|1@1+ (1,0) [0|1] ""  aps
 SG_ DAS_devAppInterfaceEnabled : 38|1@1+ (1,0) [0|1] ""  aps
 SG_ DAS_lastAutosteerAbortReason : 32|6@1+ (1,0) [0|32] ""  aps
 SG_ DAS_plannerState : 28|4@1+ (1,0) [0|7] ""  aps
 SG_ DAS_lastLinePreferenceReason : 24|4@1+ (1,0) [0|15] ""  aps
 SG_ DAS_autosteerHealthState : 21|3@1+ (1,0) [0|5] ""  aps
 SG_ DAS_autosteerHealthAnomalyLevel : 18|3@1+ (1,0) [0|7] ""  aps
 SG_ DAS_roadSurfaceType : 16|2@1+ (1,0) [0|2] ""  aps
 SG_ DAS_offsetSide : 14|2@1+ (1,0) [0|3] ""  aps
 SG_ DAS_autosteerBottsDotsUsage : 12|2@1+ (1,0) [0|3] ""  aps
 SG_ DAS_autosteerModelUsage : 10|2@1+ (1,0) [0|3] ""  aps
 SG_ DAS_autosteerNavigationUsage : 8|2@1+ (1,0) [0|3] ""  aps
 SG_ DAS_autosteerHPPUsage : 6|2@1+ (1,0) [0|3] ""  aps
 SG_ DAS_autosteerVehiclesUsage : 4|2@1+ (1,0) [0|3] ""  aps

BO_ 12 UI_status: 7 CH
 SG_ UI_cameraActive : 49|1@1+ (1,0) [0|1] ""  X
 SG_ UI_developmentCar : 48|1@1+ (1,0) [0|1] ""  X
 SG_ UI_falseTouchCounter : 40|8@1+ (1,0) [0|255] "1"  X
 SG_ UI_cellReceiverPower : 32|8@1+ (1,-128) [-128|127] "dB"  app
 SG_ UI_cellSignalBars : 24|3@1+ (1,0) [0|7] ""  app
 SG_ UI_cellNetworkTechnology : 19|4@1+ (1,0) [0|15] ""  app
 SG_ UI_radioActive : 18|1@1+ (1,0) [0|1] ""  X
 SG_ UI_screenshotActive : 17|1@1+ (1,0) [0|1] ""  app
 SG_ UI_gpsActive : 16|1@1+ (1,0) [0|1] ""  X
 SG_ UI_factoryReset : 14|2@1+ (1,0) [0|3] ""  X
 SG_ UI_autopilotTrial : 12|2@1+ (1,0) [0|3] ""  app
 SG_ UI_vpnActive : 11|1@1+ (1,0) [0|1] ""  app
 SG_ UI_cellConnected : 10|1@1+ (1,0) [0|1] ""  app
 SG_ UI_readyForDrive : 9|1@1+ (1,0) [0|1] ""  X
 SG_ UI_systemActive : 8|1@1+ (1,0) [0|1] ""  X
 SG_ UI_wifiConnected : 7|1@1+ (1,0) [0|1] ""  app
 SG_ UI_wifiActive : 6|1@1+ (1,0) [0|1] ""  X
 SG_ UI_displayOn : 5|1@1+ (1,0) [0|1] ""  X
 SG_ UI_displayReady : 4|1@1+ (1,0) [0|1] ""  X
 SG_ UI_cellActive : 3|1@1+ (1,0) [0|1] ""  X
 SG_ UI_bluetoothActive : 2|1@1+ (1,0) [0|1] ""  X
 SG_ UI_audioActive : 1|1@1+ (1,0) [0|1] ""  X
 SG_ UI_touchActive : 0|1@1+ (1,0) [0|1] ""  X

BO_ 1325 TAS_alertCleared: 2 CH
 SG_ TAS_alertClearedID : 0|16@1+ (1,0) [0|65535] ""  X

BO_ 1451 OCS1P_alertCleared: 1 CH
 SG_ OCS1P_alertClearedID : 0|8@1+ (1,0) [0|142] ""  X

BO_ 809 APP_warningMatrix0: 8 CH
 SG_ APP_w064_epasMia : 63|1@1+ (1,0) [0|1] ""  gtw
 SG_ APP_w063_parkVersionMismatch : 62|1@1+ (1,0) [0|1] ""  gtw
 SG_ APP_w062_radcAlignment : 61|1@1+ (1,0) [0|1] ""  gtw
 SG_ APP_w061_airSuspensionMia : 60|1@1+ (1,0) [0|1] ""  gtw
 SG_ APP_w060_fcw_event : 59|1@1+ (1,0) [0|1] ""  gtw
 SG_ APP_w059_parkMia : 58|1@1+ (1,0) [0|1] ""  gtw
 SG_ APP_w058_epbMia : 57|1@1+ (1,0) [0|1] ""  gtw
 SG_ APP_w057_mcuMia : 56|1@1+ (1,0) [0|1] ""  gtw
 SG_ APP_w056_diMia : 55|1@1+ (1,0) [0|1] ""  gtw
 SG_ APP_w055_radcVersionMismatch : 54|1@1+ (1,0) [0|1] ""  gtw
 SG_ APP_w054_camAutofix : 53|1@1+ (1,0) [0|1] ""  gtw
 SG_ APP_w053_radcCommIssue : 52|1@1+ (1,0) [0|1] ""  gtw
 SG_ APP_w052_radcSensorIssue : 51|1@1+ (1,0) [0|1] ""  gtw
 SG_ APP_w051_radcEcuIssue : 50|1@1+ (1,0) [0|1] ""  gtw
 SG_ APP_w050_aeb_event : 49|1@1+ (1,0) [0|1] ""  gtw
 SG_ APP_w049_eyeqVersionMismatch : 48|1@1+ (1,0) [0|1] ""  gtw
 SG_ APP_w048_APP_Features_Disabled : 47|1@1+ (1,0) [0|1] ""  gtw
 SG_ APP_w047_edrEvent : 46|1@1+ (1,0) [0|1] ""  gtw
 SG_ APP_w046_eepromRecordAbsent : 45|1@1+ (1,0) [0|1] ""  gtw
 SG_ APP_w045_radMia : 44|1@1+ (1,0) [0|1] ""  gtw
 SG_ APP_w044_appMobileyeFailure : 43|1@1+ (1,0) [0|1] ""  gtw
 SG_ APP_w043_camLongRunTime : 42|1@1+ (1,0) [0|1] ""  gtw
 SG_ APP_w042_autopilotAborting : 41|1@1+ (1,0) [0|1] ""  gtw
 SG_ APP_w041_autopilotRateSaturated : 40|1@1+ (1,0) [0|1] ""  gtw
 SG_ APP_w040_autopilotAngleSaturated : 39|1@1+ (1,0) [0|1] ""  gtw
 SG_ APP_w039_sdm_rcm_Mia : 38|1@1+ (1,0) [0|1] ""  gtw
 SG_ APP_w038_camFailure : 37|1@1+ (1,0) [0|1] ""  gtw
 SG_ APP_w037_camTacIssue : 36|1@1+ (1,0) [0|1] ""  gtw
 SG_ APP_w036_bdyMia : 35|1@1+ (1,0) [0|1] ""  gtw
 SG_ APP_w035_espMia : 34|1@1+ (1,0) [0|1] ""  gtw
 SG_ APP_w034_sccmMia : 33|1@1+ (1,0) [0|1] ""  gtw
 SG_ APP_w033_gtwMia : 32|1@1+ (1,0) [0|1] ""  gtw
 SG_ APP_w032_canTxError : 31|1@1+ (1,0) [0|1] ""  gtw
 SG_ APP_w031_canRxError : 30|1@1+ (1,0) [0|1] ""  gtw
 SG_ APP_w030_Heater_Issue : 29|1@1+ (1,0) [0|1] ""  gtw
 SG_ APP_w029_spi_tx_error : 28|1@1+ (1,0) [0|1] ""  gtw
 SG_ APP_w028_spi_rx_error : 27|1@1+ (1,0) [0|1] ""  gtw
 SG_ APP_w027_ECU_Reset_Fault : 26|1@1+ (1,0) [0|1] ""  gtw
 SG_ APP_w026_ECU_timingIssue : 25|1@1+ (1,0) [0|1] ""  gtw
 SG_ APP_w025_LC_Steering_Override : 24|1@1+ (1,0) [0|1] ""  gtw
 SG_ APP_w024_ECU_Watchdog_Reset : 23|1@1+ (1,0) [0|1] ""  gtw
 SG_ APP_w023_ECU_Cam_Statemismatc : 22|1@1+ (1,0) [0|1] ""  gtw
 SG_ APP_w022_ECU_EEPROM_Failure : 21|1@1+ (1,0) [0|1] ""  gtw
 SG_ APP_w021_ECU_Temperature_Issue : 20|1@1+ (1,0) [0|1] ""  gtw
 SG_ APP_w020_ECU_checkstopError : 19|1@1+ (1,0) [0|1] ""  gtw
 SG_ APP_w019_ECU_Stack_Overflow : 18|1@1+ (1,0) [0|1] ""  gtw
 SG_ APP_w018_ECU_Power_Issue : 17|1@1+ (1,0) [0|1] ""  gtw
 SG_ APP_w017_Cam_Msg_MIA : 16|1@1+ (1,0) [0|1] ""  gtw
 SG_ APP_w016_aeb_e_event : 15|1@1+ (1,0) [0|1] ""  gtw
 SG_ APP_w015_Camera_Failsafes : 14|1@1+ (1,0) [0|1] ""  gtw
 SG_ APP_w014_swAssert : 13|1@1+ (1,0) [0|1] ""  gtw
 SG_ APP_w013_Cam_Watchdog : 12|1@1+ (1,0) [0|1] ""  gtw
 SG_ APP_w012_Cam_BootFailure : 11|1@1+ (1,0) [0|1] ""  gtw
 SG_ APP_w011_scaEvent : 10|1@1+ (1,0) [0|1] ""  gtw
 SG_ APP_w010_radcCalibIssue : 9|1@1+ (1,0) [0|1] ""  gtw
 SG_ APP_w009_aebFault : 8|1@1+ (1,0) [0|1] ""  gtw
 SG_ APP_w008_parkDisabled : 7|1@1+ (1,0) [0|1] ""  gtw
 SG_ APP_w007_ahlbDisabled : 6|1@1+ (1,0) [0|1] ""  gtw
 SG_ APP_w006_aebCancelled : 5|1@1+ (1,0) [0|1] ""  gtw
 SG_ APP_w005_fcwCancelled : 4|1@1+ (1,0) [0|1] ""  gtw
 SG_ APP_w004_accDisabled : 3|1@1+ (1,0) [0|1] ""  gtw
 SG_ APP_w003_isaDisabled : 2|1@1+ (1,0) [0|1] ""  gtw
 SG_ APP_w002_ldwDisabled : 1|1@1+ (1,0) [0|1] ""  gtw
 SG_ APP_w001_DEPRECATED : 0|1@1+ (1,0) [0|1] ""  gtw

BO_ 789 OCS1P_info: 8 CH
 SG_ OCS1P_infoSubUsageID m11 : 48|16@1+ (1,0) [0|65535] ""  gtw
 SG_ OCS1P_infoComponentID m10 : 48|16@1+ (1,0) [0|65535] ""  gtw
 SG_ OCS1P_infoUsageID m11 : 32|16@1+ (1,0) [0|65535] ""  gtw
 SG_ OCS1P_infoApplicationCRC m13 : 32|32@1+ (1,0) [0|4294967295] ""  gtw
 SG_ OCS1P_infoHardwareID m10 : 32|16@1+ (1,0) [0|65535] ""  gtw
 SG_ OCS1P_infoBootloaderCRC m20 : 32|32@1+ (1,0) [0|4294967295] ""  gtw
 SG_ OCS1P_infoAssemblyID m11 : 24|8@1+ (1,0) [0|255] ""  gtw
 SG_ OCS1P_infoPcbaID m11 : 16|8@1+ (1,0) [0|255] ""  gtw
 SG_ OCS1P_infoBuildConfigID m10 : 16|16@1+ (1,0) [0|65535] ""  gtw
 SG_ OCS1P_infoBuildType m10 : 8|8@1+ (1,0) [0|4] ""  gtw
 SG_ OCS1P_infoBootSvnRev m14 : 8|24@1+ (1,0) [0|16777215] ""  gtw
 SG_ OCS1P_infoPlatformType m19 : 8|8@1+ (1,0) [0|255] ""  gtw
 SG_ OCS1P_infoBootGitHashBytes m18 : 8|56@1+ (1,0) [0|72057594037927935] ""  gtw
 SG_ OCS1P_infoAppGitHashBytes m17 : 8|56@1+ (1,0) [0|72057594037927935] ""  gtw
 SG_ OCS1P_infoBootUdsProtoVersion m20 : 8|8@1+ (1,0) [0|255] ""  gtw
 SG_ OCS1P_infoIndex M : 0|8@1+ (1,0) [10|20] ""  gtw

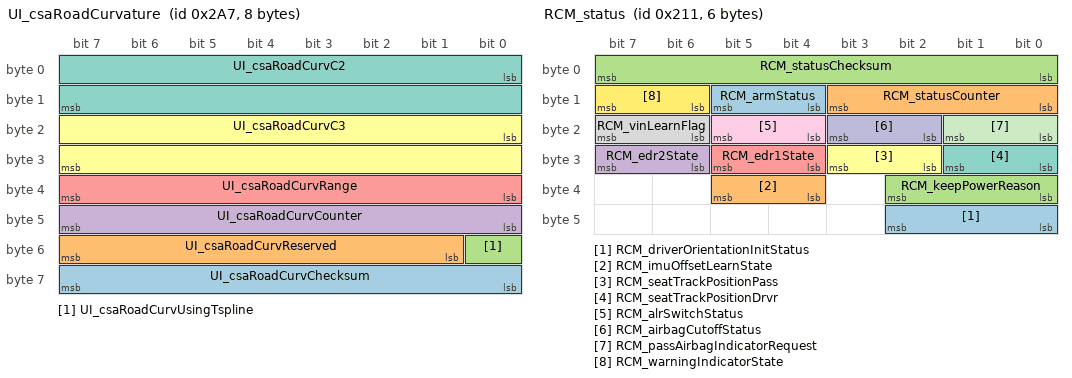
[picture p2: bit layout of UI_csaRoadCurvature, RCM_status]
BO_ 679 UI_csaRoadCurvature: 8 CH
 SG_ UI_csaRoadCurvChecksum : 56|8@1+ (1,0) [0|255] ""  X
 SG_ UI_csaRoadCurvReserved : 49|7@1+ (1,0) [0|127] ""  X
 SG_ UI_csaRoadCurvUsingTspline : 48|1@1+ (1,0) [0|1] ""  das
 SG_ UI_csaRoadCurvCounter : 40|8@1+ (1,0) [0|255] ""  X
 SG_ UI_csaRoadCurvRange : 32|8@1+ (2,0) [0|510] "m"  das
 SG_ UI_csaRoadCurvC3 : 16|16@1- (4e-09,0.0) [-0.000131072|0.000131068] "1/m2"  das
 SG_ UI_csaRoadCurvC2 : 0|16@1- (1e-06,0.0) [-0.032768|0.032767] "1/m"  das

BO_ 1011 UI_odo: 3 CH
 SG_ UI_odometer : 0|24@1+ (0.1,0) [0|1677721.5] "km"  das

BO_ 962 VCLEFT_switchStatus: 8 CH
 SG_ VCLEFT_rearHVACButtonPressed m0 : 61|1@1+ (1,0) [0|1] ""  X
 SG_ VCLEFT_brakePressed m0 : 60|1@1+ (1,0) [0|1] ""  X
 SG_ VCLEFT_rearRightOccupancySwitch m0 : 58|2@1+ (1,0) [0|3] ""  X
 SG_ VCLEFT_rearLeftOccupancySwitch m0 : 56|2@1+ (1,0) [0|3] ""  X
 SG_ VCLEFT_rearCenterOccupancySwitch m0 : 54|2@1+ (1,0) [0|3] ""  X
 SG_ VCLEFT_rearLeftBuckleSwitch m0 : 52|2@1+ (1,0) [0|3] ""  X
 SG_ VCLEFT_frontOccupancySwitch m0 : 50|2@1+ (1,0) [0|3] ""  X
 SG_ VCLEFT_frontBuckleSwitch m0 : 48|2@1+ (1,0) [0|3] ""  ocs1p
 SG_ VCLEFT_btnWindowSwPackAutoDownRR m0 : 47|1@1+ (1,0) [0|1] ""  X
 SG_ VCLEFT_btnWindowSwPackDownRR m0 : 46|1@1+ (1,0) [0|1] ""  X
 SG_ VCLEFT_btnWindowSwPackAutoUpRR m0 : 45|1@1+ (1,0) [0|1] ""  X
 SG_ VCLEFT_btnWindowSwPackUpRR m0 : 44|1@1+ (1,0) [0|1] ""  X
 SG_ VCLEFT_btnWindowSwPackAutoDownRF m0 : 43|1@1+ (1,0) [0|1] ""  X
 SG_ VCLEFT_btnWindowSwPackDownRF m0 : 42|1@1+ (1,0) [0|1] ""  X
 SG_ VCLEFT_btnWindowSwPackAutoUpRF m0 : 41|1@1+ (1,0) [0|1] ""  X
 SG_ VCLEFT_btnWindowSwPackUpRF m0 : 40|1@1+ (1,0) [0|1] ""  X
 SG_ VCLEFT_btnWindowSwPackAutoDownLR m0 : 39|1@1+ (1,0) [0|1] ""  X
 SG_ VCLEFT_btnWindowSwPackDownLR m0 : 38|1@1+ (1,0) [0|1] ""  X
 SG_ VCLEFT_btnWindowSwPackAutoUpLR m0 : 37|1@1+ (1,0) [0|1] ""  X
 SG_ VCLEFT_btnWindowSwPackUpLR m0 : 36|1@1+ (1,0) [0|1] ""  X
 SG_ VCLEFT_btnWindowAutoDownLR m1 : 35|1@1+ (1,0) [0|1] ""  X
 SG_ VCLEFT_btnWindowSwPackAutoDownLF m0 : 35|1@1+ (1,0) [0|1] ""  X
 SG_ VCLEFT_btnWindowDownLR m1 : 34|1@1+ (1,0) [0|1] ""  X
 SG_ VCLEFT_btnWindowSwPackDownLF m0 : 34|1@1+ (1,0) [0|1] ""  X
 SG_ VCLEFT_btnWindowAutoUpLR m1 : 33|1@1+ (1,0) [0|1] ""  X
 SG_ VCLEFT_btnWindowSwPackAutoUpLF m0 : 33|1@1+ (1,0) [0|1] ""  X
 SG_ VCLEFT_btnWindowUpLR m1 : 32|1@1+ (1,0) [0|1] ""  X
 SG_ VCLEFT_btnWindowSwPackUpLF m0 : 32|1@1+ (1,0) [0|1] ""  X
 SG_ VCLEFT_frontSeatLumbarOut m0 : 30|2@1+ (1,0) [0|3] ""  X
 SG_ VCLEFT_frontSeatLumbarIn m0 : 28|2@1+ (1,0) [0|3] ""  X
 SG_ VCLEFT_frontSeatLumbarUp m0 : 26|2@1+ (1,0) [0|3] ""  X
 SG_ VCLEFT_swcRightScrollTicks m1 : 24|6@1- (1,0) [-32|31] ""  X
 SG_ VCLEFT_frontSeatLumbarDown m0 : 24|2@1+ (1,0) [0|3] ""  X
 SG_ VCLEFT_frontSeatBackrestForward m0 : 22|2@1+ (1,0) [0|3] ""  X
 SG_ VCLEFT_frontSeatBackrestBack m0 : 20|2@1+ (1,0) [0|3] ""  X
 SG_ VCLEFT_frontSeatLiftUp m0 : 18|2@1+ (1,0) [0|3] ""  X
 SG_ VCLEFT_frontSeatLiftDown m0 : 16|2@1+ (1,0) [0|3] ""  X
 SG_ VCLEFT_swcLeftScrollTicks m1 : 16|6@1- (1,0) [-32|31] ""  X
 SG_ VCLEFT_frontSeatTiltUp m0 : 14|2@1+ (1,0) [0|3] ""  X
 SG_ VCLEFT_swcLeftTiltLeft m1 : 14|2@1+ (1,0) [0|3] ""  X
 SG_ VCLEFT_swcRightPressed m1 : 12|2@1+ (1,0) [0|3] ""  X
 SG_ VCLEFT_frontSeatTiltDown m0 : 12|2@1+ (1,0) [0|3] ""  X
 SG_ VCLEFT_frontSeatTrackForward m0 : 10|2@1+ (1,0) [0|3] ""  X
 SG_ VCLEFT_swcRightTiltRight m1 : 10|2@1+ (1,0) [0|3] ""  X
 SG_ VCLEFT_swcRightTiltLeft m1 : 8|2@1+ (1,0) [0|3] ""  X
 SG_ VCLEFT_frontSeatTrackBack m0 : 8|2@1+ (1,0) [0|3] ""  X
 SG_ VCLEFT_swcLeftPressed m1 : 5|2@1+ (1,0) [0|3] ""  X
 SG_ VCLEFT_rightMirrorTilt m0 : 5|3@1+ (1,0) [0|4] ""  X
 SG_ VCLEFT_driverPresent m0 : 4|1@1+ (1,0) [0|1] ""  das
 SG_ VCLEFT_hazardButtonPressed m0 : 3|1@1+ (1,0) [0|1] ""  X
 SG_ VCLEFT_swcLeftTiltRight m1 : 3|2@1+ (1,0) [0|3] ""  X
 SG_ VCLEFT_hornSwitchPressed m0 : 2|1@1+ (1,0) [0|1] ""  X
 SG_ VCLEFT_switchStatusIndex M : 0|2@1+ (1,0) [0|2] ""  X

BO_ 1357 TAS_info: 8 CH
 SG_ TAS_infoSubUsageId m11 : 48|16@1+ (1,0) [0|65535] ""  gtw
 SG_ TAS_infoComponentId m10 : 48|16@1+ (1,0) [0|65535] ""  X
 SG_ TAS_infoHardwareRevision m19 : 40|8@1+ (1,0) [0|255] ""  X
 SG_ TAS_infoBootCrc m20 : 32|32@1+ (1,0) [0|4294967295] ""  X
 SG_ TAS_infoUsageId m11 : 32|16@1+ (1,0) [0|65535] ""  gtw
 SG_ TAS_infoHardwareId m10 : 32|1@1+ (1,0) [0|1] ""  X
 SG_ TAS_infoMaturity m19 : 32|8@1+ (1,0) [0|255] ""  X
 SG_ TAS_infoAppCrc m13 : 32|32@1+ (1,0) [0|4294967295] ""  gtw
 SG_ TAS_infoBranchOrigin m19 : 24|8@1+ (1,0) [0|255] ""  X
 SG_ TAS_infoAssemblyId m11 : 24|8@1+ (1,0) [0|255] ""  gtw
 SG_ TAS_infoMajorVersion m19 : 16|8@1+ (1,0) [0|255] ""  X
 SG_ TAS_infoPcbaId m11 : 16|8@1+ (1,0) [0|255] ""  gtw
 SG_ TAS_infoBuildConfigId m10 : 16|16@1+ (1,0) [0|65535] ""  gtw
 SG_ TAS_infoBuildType m10 : 8|3@1+ (1,0) [0|4] ""  gtw
 SG_ TAS_infoBootGitHash m18 : 8|56@1+ (1,0) [0|72057594037927935] ""  X
 SG_ TAS_infoAppGitHash m17 : 8|56@1+ (1,0) [0|72057594037927935] ""  X
 SG_ TAS_infoPlatformType m19 : 8|8@1+ (1,0) [0|255] ""  gtw
 SG_ TAS_infoBootloaderSvnRevision m14 : 8|24@1+ (1,0) [0|16777215] ""  X
 SG_ TAS_infoBootUdsProtoVersion m20 : 8|8@1+ (1,0) [0|255] ""  X
 SG_ TAS_infoIndex M : 0|8@1+ (1,0) [0|255] ""  gtw

BO_ 1337 DAS_info: 8 CH
 SG_ DAS_infoSubUsageID m11 : 48|16@1+ (1,0) [0|65535] ""  gtw
 SG_ DAS_infoComponentID m10 : 48|16@1+ (1,0) [0|65535] ""  gtw
 SG_ DAS_infoHardwareRevision m19 : 40|8@1+ (1,0) [0|252] ""  gtw
 SG_ DAS_infoUsageID m11 : 32|16@1+ (1,0) [0|65535] ""  gtw
 SG_ DAS_infoApplicationCRC m13 : 32|32@1+ (1,0) [0|4294967295] ""  gtw
 SG_ DAS_infoHardwareID m10 : 32|16@1+ (1,0) [0|65535] ""  gtw
 SG_ DAS_infoMaturity m19 : 32|8@1+ (1,0) [0|255] ""  gtw
 SG_ DAS_infoBootloaderCRC m20 : 32|32@1+ (1,0) [0|4294967295] ""  gtw
 SG_ DAS_infoBranchOrigin m19 : 24|8@1+ (1,0) [0|255] ""  gtw
 SG_ DAS_infoAssemblyID m11 : 24|8@1+ (1,0) [0|255] ""  gtw
 SG_ DAS_infoEyeQFfsCRC m24 : 16|32@1+ (1,0) [0|4294967295] ""  X
 SG_ DAS_infoMajorVersion m19 : 16|8@1+ (1,0) [0|255] ""  gtw
 SG_ DAS_infoPcbaID m11 : 16|8@1+ (1,0) [0|255] ""  gtw
 SG_ DAS_infoEyeQAppCRC m23 : 16|32@1+ (1,0) [0|4294967295] ""  X
 SG_ DAS_infoBuildConfigID m10 : 16|16@1+ (1,0) [0|65535] ""  gtw
 SG_ DAS_infoEyeQBootCRC m16 : 16|32@1+ (1,0) [0|4294967295] ""  X
 SG_ DAS_infoBuildType m10 : 8|8@1+ (1,0) [0|4] ""  gtw
 SG_ DAS_infoPlatformType m19 : 8|8@1+ (1,0) [0|255] ""  gtw
 SG_ DAS_infoBootGitHashBytes m18 : 8|56@1+ (1,0) [0|72057594037927935] ""  gtw
 SG_ DAS_infoAppGitHashBytes m17 : 8|56@1+ (1,0) [0|72057594037927935] ""  gtw
 SG_ DAS_infoBootloaderSvnRevision m14 : 8|24@1+ (1,0) [0|16777215] ""  gtw
 SG_ DAS_infoBootUdsProtoVersion m20 : 8|8@1+ (1,0) [0|255] ""  gtw
 SG_ DAS_infoIndex M : 0|8@1+ (1,0) [0|255] ""  gtw

BO_ 1012 APP_camCalibrationStatus: 6 CH
 SG_ APP_mainCalibrated m1 : 40|1@1+ (1,0) [0|1] ""  gtw
 SG_ APP_lPillarCalibrated m4 : 40|1@1+ (1,0) [0|1] ""  gtw
 SG_ APP_backupCalibrated m8 : 40|1@1+ (1,0) [0|1] ""  gtw
 SG_ APP_narrowCalibrated m2 : 40|1@1+ (1,0) [0|1] ""  gtw
 SG_ APP_lRepeatCalibrated m6 : 40|1@1+ (1,0) [0|1] ""  gtw
 SG_ APP_rRepeatCalibrated m7 : 40|1@1+ (1,0) [0|1] ""  gtw
 SG_ APP_fisheyeCalibrated m3 : 40|1@1+ (1,0) [0|1] ""  gtw
 SG_ APP_rPillarCalibrated m5 : 40|1@1+ (1,0) [0|1] ""  gtw
 SG_ APP_narrowCalibProgress m2 : 33|7@1+ (1,0) [0|100] "percent"  gtw
 SG_ APP_lRepeatCalibProgress m6 : 33|7@1+ (1,0) [0|100] "percent"  gtw
 SG_ APP_rPillarCalibProgress m5 : 33|7@1+ (1,0) [0|100] "percent"  gtw
 SG_ APP_fisheyeCalibProgress m3 : 33|7@1+ (1,0) [0|100] "percent"  gtw
 SG_ APP_rRepeatCalibProgress m7 : 33|7@1+ (1,0) [0|100] "percent"  gtw
 SG_ APP_backupCalibProgress m8 : 33|7@1+ (1,0) [0|100] "percent"  gtw
 SG_ APP_lPillarCalibProgress m4 : 33|7@1+ (1,0) [0|100] "percent"  gtw
 SG_ APP_mainCalibProgress m1 : 33|7@1+ (1,0) [0|100] "percent"  gtw
 SG_ APP_narrowCalibTime m2 : 26|7@1+ (1,0) [0|512] "min"  gtw
 SG_ APP_lRepeatCalibTime m6 : 26|7@1+ (1,0) [0|512] "min"  gtw
 SG_ APP_rPillarCalibTime m5 : 26|7@1+ (1,0) [0|512] "min"  gtw
 SG_ APP_fisheyeCalibTime m3 : 26|7@1+ (1,0) [0|512] "min"  gtw
 SG_ APP_rRepeatCalibTime m7 : 26|7@1+ (1,0) [0|512] "min"  gtw
 SG_ APP_backupCalibTime m8 : 26|7@1+ (1,0) [0|512] "min"  gtw
 SG_ APP_lPillarCalibTime m4 : 26|7@1+ (1,0) [0|512] "min"  gtw
 SG_ APP_mainCalibTime m1 : 26|7@1+ (1,0) [0|512] "min"  gtw
 SG_ APP_rPillarCamExtYawCal m5 : 17|9@1+ (0.05,-12.5) [-12.5|12.5] "deg"  gtw
 SG_ APP_narrowCamExtYawCal m2 : 17|9@1+ (0.05,-12.5) [-12.5|12.5] "deg"  gtw
 SG_ APP_mainCamExtYawCal m1 : 17|9@1+ (0.05,-12.5) [-12.5|12.5] "deg"  gtw
 SG_ APP_rRepeatCamExtYawCal m7 : 17|9@1+ (0.05,-12.5) [-12.5|12.5] "deg"  gtw
 SG_ APP_fisheyeCamExtYawCal m3 : 17|9@1+ (0.05,-12.5) [-12.5|12.5] "deg"  gtw
 SG_ APP_lRepeatCamExtYawCal m6 : 17|9@1+ (0.05,-12.5) [-12.5|12.5] "deg"  gtw
 SG_ APP_lPillarCamExtYawCal m4 : 17|9@1+ (0.05,-12.5) [-12.5|12.5] "deg"  gtw
 SG_ APP_backupCamExtYawCal m8 : 17|9@1+ (0.05,-12.5) [-12.5|12.5] "deg"  gtw
 SG_ APP_lRepeatCamExtPitchCal m6 : 8|9@1+ (0.05,-12.5) [-12.5|12.5] "deg"  gtw
 SG_ APP_narrowCamExtPitchCal m2 : 8|9@1+ (0.05,-12.5) [-12.5|12.5] "deg"  gtw
 SG_ APP_backupCamExtPitchCal m8 : 8|9@1+ (0.05,-12.5) [-12.5|12.5] "deg"  gtw
 SG_ APP_lPillarCamExtPitchCal m4 : 8|9@1+ (0.05,-12.5) [-12.5|12.5] "deg"  gtw
 SG_ APP_mainCamExtPitchCal m1 : 8|9@1+ (0.05,-12.5) [-12.5|12.5] "deg"  gtw
 SG_ APP_rPillarCamExtPitchCal m5 : 8|9@1+ (0.05,-12.5) [-12.5|12.5] "deg"  gtw
 SG_ APP_fisheyeCamExtPitchCal m3 : 8|9@1+ (0.05,-12.5) [-12.5|12.5] "deg"  gtw
 SG_ APP_rRepeatCamExtPitchCal m7 : 8|9@1+ (0.05,-12.5) [-12.5|12.5] "deg"  gtw
 SG_ APP_cameraPosition M : 0|4@1+ (1,0) [0|8] ""  X

BO_ 529 RCM_status: 6 CH
 SG_ RCM_driverOrientationInitStatus : 40|3@1+ (1,0) [0|7] ""  gtw
 SG_ RCM_imuOffsetLearnState : 36|2@1+ (1,0) [0|3] ""  gtw
 SG_ RCM_keepPowerReason : 32|3@1+ (1,0) [0|7] ""  gtw
 SG_ RCM_edr2State : 30|2@1+ (1,0) [0|3] ""  gtw
 SG_ RCM_edr1State : 28|2@1+ (1,0) [0|3] ""  gtw
 SG_ RCM_seatTrackPositionPass : 26|2@1+ (1,0) [0|3] ""  gtw
 SG_ RCM_seatTrackPositionDrvr : 24|2@1+ (1,0) [0|3] ""  gtw
 SG_ RCM_vinLearnFlag : 22|2@1+ (1,0) [0|3] ""  gtw
 SG_ RCM_alrSwitchStatus : 20|2@1+ (1,0) [0|3] ""  gtw
 SG_ RCM_airbagCutoffStatus : 18|2@1+ (1,0) [0|3] ""  gtw
 SG_ RCM_passAirbagIndicatorRequest : 16|2@1+ (1,0) [0|3] ""  gtw
 SG_ RCM_warningIndicatorState : 14|2@1+ (1,0) [0|3] ""  gtw
 SG_ RCM_armStatus : 12|2@1+ (1,0) [0|3] ""  gtw
 SG_ RCM_statusCounter : 8|4@1+ (1,0) [0|15] ""  X
 SG_ RCM_statusChecksum : 0|8@1+ (1,0) [0|255] ""  gtw

BO_ 565 OCS1P_debugTHS: 4 CH
 SG_ OCS1P_humidity : 16|16@1+ (0.1,0) [0|100] "%"  gtw
 SG_ OCS1P_temperature : 0|16@1- (0.1,0) [-40|150] "degC"  gtw

BO_ 895 TPMS_debugC: 8 CH
 SG_ TPMS_debugResponse : 0|64@1+ (1,0) [0|18446744073709551615] ""  X

BO_ 905 DAS_status2: 8 CH
 SG_ DAS_status2Checksum : 56|8@1+ (1,0) [0|255] ""  aps
 SG_ DAS_status2Counter : 52|4@1+ (1,0) [0|15] ""  aps
 SG_ DAS_longCollisionWarning : 48|4@1+ (1,0) [0|15] ""  aps
 SG_ DAS_ppOffsetDesiredRamp : 40|8@1+ (0.01,-1.28) [-1.28|1.27] "m"  aps
 SG_ DAS_driverInteractionLevel : 38|2@1+ (1,0) [0|2] ""  aps
 SG_ DAS_robState : 36|2@1+ (1,0) [0|3] ""  aps
 SG_ DAS_radarTelemetry : 34|2@1+ (1,0) [0|2] ""  aps
 SG_ DAS_lssState : 31|3@1+ (1,0) [0|7] ""  aps
 SG_ DAS_ACC_report : 26|5@1+ (1,0) [0|24] ""  aps
 SG_ DAS_pmmCameraFaultReason : 24|2@1+ (1,0) [0|2] ""  aps
 SG_ DAS_pmmSysFaultReason : 21|3@1+ (1,0) [0|7] ""  aps
 SG_ DAS_pmmRadarFaultReason : 19|2@1+ (1,0) [0|2] ""  aps
 SG_ DAS_pmmUltrasonicsFaultReason : 16|3@1+ (1,0) [0|4] ""  aps
 SG_ DAS_activationFailureStatus : 14|2@1+ (1,0) [0|2] ""  aps
 SG_ DAS_pmmLoggingRequest : 13|1@1+ (1,0) [0|1] ""  aps
 SG_ DAS_pmmObstacleSeverity : 10|3@1+ (1,0) [0|7] ""  aps
 SG_ DAS_accSpeedLimit : 0|10@1+ (0.2,0) [0|204.6] "mph"  aps

BO_ 805 ESP_info: 8 CH
 SG_ ESP_infoComponentID m10 : 48|16@1+ (1,0) [0|65535] ""  gtw
 SG_ ESP_infoUsageID m11 : 32|16@1+ (1,0) [0|65535] ""  gtw
 SG_ ESP_infoApplicationCRC m13 : 39|32@0+ (1,0) [0|4294967295] ""  gtw
 SG_ ESP_infoBootloaderCRC m20 : 32|32@1+ (1,0) [0|4294967295] ""  gtw
 SG_ ESP_infoVariantCRC m22 : 39|32@0+ (1,0) [0|4294967295] ""  gtw
 SG_ ESP_infoAssemblyID m11 : 24|8@1+ (1,0) [0|255] ""  gtw
 SG_ ESP_infoVehicleVariant m16 : 16|8@1+ (1,0) [1|9] ""  gtw
 SG_ ESP_infoPcbaID m11 : 16|8@1+ (1,0) [0|255] ""  gtw
 SG_ ESP_infoBuildType m10 : 8|8@1+ (1,0) [0|4] ""  gtw
 SG_ ESP_infoBootUdsProtoVersion m20 : 8|8@1+ (1,0) [0|255] ""  gtw
 SG_ ESP_infoIndex M : 0|8@1+ (1,0) [0|255] ""  gtw

BO_ 1611 UDS_tasRequest: 8 CH
 SG_ UDS_tasRequestData : 7|64@0+ (1,0) [0|18446744073709551615] ""  tas

BO_ 879 TPMS_StatusC: 8 CH
 SG_ TPMS_rcpRear : 56|8@1+ (0.025,0) [0|6.375] "bar"  gtw
 SG_ TPMS_rcpFront : 48|8@1+ (0.025,0) [0|6.375] "bar"  gtw
 SG_ TPMS_eolNotCompleted : 47|1@1+ (1,0) [0|1] ""  gtw
 SG_ TPMS_externalTemperatureFail : 46|1@1+ (1,0) [0|1] ""  gtw
 SG_ TPMS_vehicleSpeedFail : 45|1@1+ (1,0) [0|1] ""  gtw
 SG_ TPMS_wheelPulseMissing : 44|1@1+ (1,0) [0|1] ""  gtw
 SG_ TPMS_rfReceiverFail : 43|1@1+ (1,0) [0|1] ""  gtw
 SG_ TPMS_ecuRamRomNvMFail : 42|1@1+ (1,0) [0|1] ""  gtw
 SG_ TPMS_ecuOverVoltage : 41|1@1+ (1,0) [0|1] ""  gtw
 SG_ TPMS_ecuUnderVoltage : 40|1@1+ (1,0) [0|1] ""  gtw
 SG_ TPMS_sensorDefectiveRR : 39|1@1+ (1,0) [0|1] ""  gtw
 SG_ TPMS_sensorDefectiveRL : 38|1@1+ (1,0) [0|1] ""  gtw
 SG_ TPMS_sensorDefectiveFR : 37|1@1+ (1,0) [0|1] ""  gtw
 SG_ TPMS_sensorDefectiveFL : 36|1@1+ (1,0) [0|1] ""  gtw
 SG_ TPMS_sensorBatteryLowRR : 35|1@1+ (1,0) [0|1] ""  gtw
 SG_ TPMS_sensorBatteryLowRL : 34|1@1+ (1,0) [0|1] ""  gtw
 SG_ TPMS_sensorBatteryLowFR : 33|1@1+ (1,0) [0|1] ""  gtw
 SG_ TPMS_sensorBatteryLowFL : 32|1@1+ (1,0) [0|1] ""  gtw
 SG_ TPMS_sensorThermShutdownRR : 31|1@1+ (1,0) [0|1] ""  gtw
 SG_ TPMS_sensorThermShutdownRL : 30|1@1+ (1,0) [0|1] ""  gtw
 SG_ TPMS_sensorThermShutdownFR : 29|1@1+ (1,0) [0|1] ""  gtw
 SG_ TPMS_sensorThermShutdownFL : 28|1@1+ (1,0) [0|1] ""  gtw
 SG_ TPMS_sensorNoResponseRR : 27|1@1+ (1,0) [0|1] ""  gtw
 SG_ TPMS_sensorNoResponseRL : 26|1@1+ (1,0) [0|1] ""  gtw
 SG_ TPMS_sensorNoResponseFR : 25|1@1+ (1,0) [0|1] ""  gtw
 SG_ TPMS_sensorNoResponseFL : 24|1@1+ (1,0) [0|1] ""  gtw
 SG_ TPMS_deltaPressWarningRR : 23|1@1+ (1,0) [0|1] ""  gtw
 SG_ TPMS_deltaPressWarningRL : 22|1@1+ (1,0) [0|1] ""  gtw
 SG_ TPMS_deltaPressWarningFR : 21|1@1+ (1,0) [0|1] ""  gtw
 SG_ TPMS_deltaPressWarningFL : 20|1@1+ (1,0) [0|1] ""  gtw
 SG_ TPMS_localisationStatus : 18|2@1+ (1,0) [0|3] ""  gtw
 SG_ TPMS_learningStatus : 16|2@1+ (1,0) [0|3] ""  gtw
 SG_ TPMS_hardWarningFL : 15|1@1+ (1,0) [0|1] ""  gtw
 SG_ TPMS_softWarningFL : 14|1@1+ (1,0) [0|1] ""  gtw
 SG_ TPMS_hardWarningFR : 13|1@1+ (1,0) [0|1] ""  gtw
 SG_ TPMS_softWarningFR : 12|1@1+ (1,0) [0|1] ""  gtw
 SG_ TPMS_hardWarningRL : 11|1@1+ (1,0) [0|1] ""  gtw
 SG_ TPMS_softWarningRL : 10|1@1+ (1,0) [0|1] ""  gtw
 SG_ TPMS_hardWarningRR : 9|1@1+ (1,0) [0|1] ""  gtw
 SG_ TPMS_softWarningRR : 8|1@1+ (1,0) [0|1] ""  gtw
 SG_ TPMS_newSensorLearnt : 5|3@1+ (1,0) [0|7] ""  gtw
 SG_ TPMS_globalDeltaPressure : 4|1@1+ (1,0) [0|1] ""  gtw
 SG_ TPMS_WA_version : 3|1@1+ (1,0) [0|1] ""  gtw
 SG_ TPMS_systemMalfunction : 2|1@1+ (1,0) [0|1] ""  gtw
 SG_ TPMS_c_globalSoftWarning : 1|1@1+ (1,0) [0|1] ""  gtw
 SG_ TPMS_c_globalHardWarning : 0|1@1+ (1,0) [0|1] ""  gtw

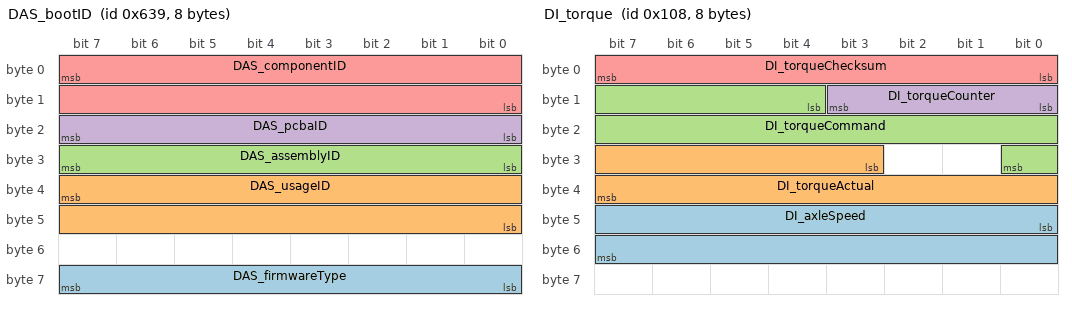
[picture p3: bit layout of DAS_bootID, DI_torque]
BO_ 1593 DAS_bootID: 8 CH
 SG_ DAS_firmwareType : 63|8@0+ (1,0) [0|255] ""  X
 SG_ DAS_usageID : 39|16@0+ (1,0) [0|65535] ""  X
 SG_ DAS_assemblyID : 31|8@0+ (1,0) [0|255] ""  X
 SG_ DAS_pcbaID : 23|8@0+ (1,0) [0|255] ""  X
 SG_ DAS_componentID : 7|16@0+ (1,0) [0|65535] ""  X

BO_ 264 DI_torque: 8 CH
 SG_ DI_axleSpeed : 40|16@1- (0.1,0.0) [-2750|2750] "RPM"  epas3s
 SG_ DI_torqueActual : 27|13@1- (2,0) [-7500|7500] "Nm"  X
 SG_ DI_torqueCommand : 12|13@1- (2,0) [-7500|7500] "Nm"  X
 SG_ DI_torqueCounter : 8|4@1+ (1,0) [0|15] ""  epas3s
 SG_ DI_torqueChecksum : 0|8@1+ (1,0) [0|255] ""  epas3s

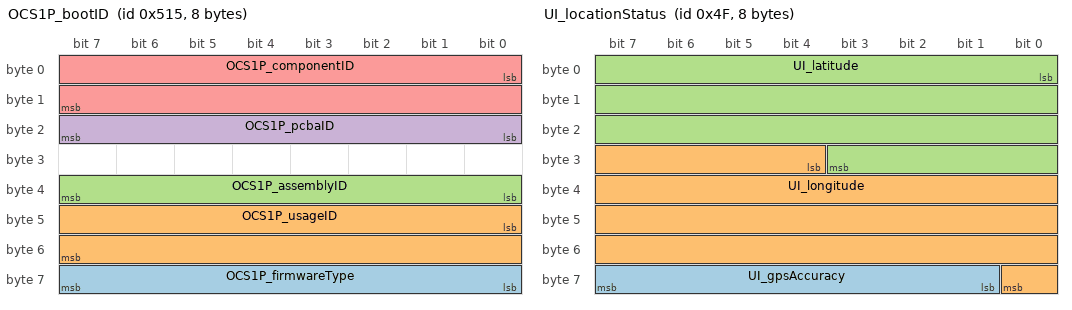
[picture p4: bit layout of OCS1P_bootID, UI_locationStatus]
BO_ 1301 OCS1P_bootID: 8 CH
 SG_ OCS1P_firmwareType : 56|8@1+ (1,0) [0|255] ""  gtwu
 SG_ OCS1P_usageID : 40|16@1+ (1,0) [0|65535] ""  gtwu
 SG_ OCS1P_assemblyID : 32|8@1+ (1,0) [0|255] ""  gtwu
 SG_ OCS1P_pcbaID : 16|8@1+ (1,0) [0|255] ""  gtwu
 SG_ OCS1P_componentID : 0|16@1+ (1,0) [0|65535] ""  gtwu

BO_ 1029 GTW_vin: 8 CH
 SG_ GTW_vinHigh m16 : 47|24@0+ (1,0) [0|16777215] ""  das
 SG_ GTW_vinLow m18 : 15|56@0+ (1,0) [0|72057594037927935] ""  das
 SG_ GTW_vinMid m17 : 15|56@0+ (1,0) [0|72057594037927935] ""  das
 SG_ GTW_vinIndex M : 7|8@0+ (1,0) [16|18] ""  das

BO_ 79 UI_locationStatus: 8 CH
 SG_ UI_gpsAccuracy : 57|7@1+ (0.2,0) [0|25.2] "m"  das
 SG_ UI_longitude : 28|29@1- (1e-06,0) [-268.43546|268.43546] "deg"  das
 SG_ UI_latitude : 0|28@1- (1e-06,0) [-134.21773|134.21773] "deg"  das

BO_ 1617 RCM_udsResponse: 8 CH
 SG_ RCM_udsResponseData : 7|64@0+ (1,0) [0|18446744073709551615] ""  gtw

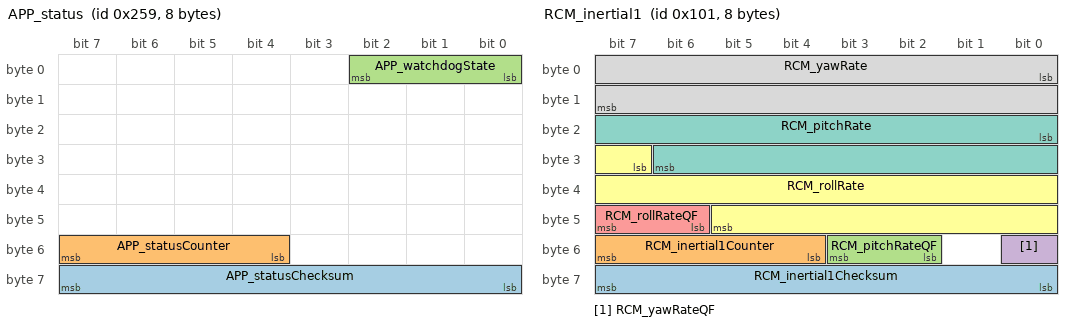
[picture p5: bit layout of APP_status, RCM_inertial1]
BO_ 601 APP_status: 8 CH
 SG_ APP_statusChecksum : 56|8@1+ (1,0) [0|255] ""  aps
 SG_ APP_statusCounter : 52|4@1+ (1,0) [0|15] ""  aps
 SG_ APP_watchdogState : 0|3@1+ (1,0) [0|7] ""  aps

BO_ 1606 ESP_bootID: 8 CH
 SG_ ESP_bootIdData : 0|64@1+ (1,0) [0|18446744073709551615] ""  gtwu

BO_ 1665 RADC_udsResponse: 8 CH
 SG_ RADC_udsResponseData : 7|64@0+ (1,0) [0|18446744073709551615] ""  gtw

BO_ 1603 UDS_ocs1pRequest: 8 CH
 SG_ UDS_ocs1pRequestData : 7|64@0+ (1,0) [0|18446744073709551615] ""  ocs1p

BO_ 1548 DAS_telemetryRadar: 8 CH
 SG_ DAS_TR_Obj20_Exist m20 : 56|5@1+ (3.125,0) [0|96.875] "%"  gtw
 SG_ DAS_TR_Obj02_Exist m2 : 56|5@1+ (3.125,0) [0|96.875] "%"  gtw
 SG_ DAS_TR_Obj14_Exist m14 : 56|5@1+ (3.125,0) [0|96.875] "%"  gtw
 SG_ DAS_TR_Obj08_Exist m8 : 56|5@1+ (3.125,0) [0|96.875] "%"  gtw
 SG_ DAS_TR_Obj11_Exist m11 : 56|5@1+ (3.125,0) [0|96.875] "%"  gtw
 SG_ DAS_TR_Obj21_Exist m21 : 56|5@1+ (3.125,0) [0|96.875] "%"  gtw
 SG_ DAS_TR_Obj03_Exist m3 : 56|5@1+ (3.125,0) [0|96.875] "%"  gtw
 SG_ DAS_TR_Obj17_Exist m17 : 56|5@1+ (3.125,0) [0|96.875] "%"  gtw
 SG_ DAS_TR_Obj10_Exist m10 : 56|5@1+ (3.125,0) [0|96.875] "%"  gtw
 SG_ DAS_TR_Obj09_Exist m9 : 56|5@1+ (3.125,0) [0|96.875] "%"  gtw
 SG_ DAS_TR_Obj26_Exist m26 : 56|5@1+ (3.125,0) [0|96.875] "%"  gtw
 SG_ DAS_TR_Obj04_Exist m4 : 56|5@1+ (3.125,0) [0|96.875] "%"  gtw
 SG_ DAS_TR_Obj16_Exist m16 : 56|5@1+ (3.125,0) [0|96.875] "%"  gtw
 SG_ DAS_TR_Obj31_Exist m31 : 56|5@1+ (3.125,0) [0|96.875] "%"  gtw
 SG_ DAS_TR_Obj28_Exist m28 : 56|5@1+ (3.125,0) [0|96.875] "%"  gtw
 SG_ DAS_TR_Obj13_Exist m13 : 56|5@1+ (3.125,0) [0|96.875] "%"  gtw
 SG_ DAS_TR_Obj27_Exist m27 : 56|5@1+ (3.125,0) [0|96.875] "%"  gtw
 SG_ DAS_TR_Obj05_Exist m5 : 56|5@1+ (3.125,0) [0|96.875] "%"  gtw
 SG_ DAS_TR_Obj19_Exist m19 : 56|5@1+ (3.125,0) [0|96.875] "%"  gtw
 SG_ DAS_TR_Obj00_Exist m0 : 56|5@1+ (3.125,0) [0|96.875] "%"  gtw
 SG_ DAS_TR_Obj22_Exist m22 : 56|5@1+ (3.125,0) [0|96.875] "%"  gtw
 SG_ DAS_TR_Obj12_Exist m12 : 56|5@1+ (3.125,0) [0|96.875] "%"  gtw
 SG_ DAS_TR_Obj30_Exist m30 : 56|5@1+ (3.125,0) [0|96.875] "%"  gtw
 SG_ DAS_TR_Obj29_Exist m29 : 56|5@1+ (3.125,0) [0|96.875] "%"  gtw
 SG_ DAS_TR_Obj06_Exist m6 : 56|5@1+ (3.125,0) [0|96.875] "%"  gtw
 SG_ DAS_TR_Obj24_Exist m24 : 56|5@1+ (3.125,0) [0|96.875] "%"  gtw
 SG_ DAS_TR_Obj23_Exist m23 : 56|5@1+ (3.125,0) [0|96.875] "%"  gtw
 SG_ DAS_TR_Obj18_Exist m18 : 56|5@1+ (3.125,0) [0|96.875] "%"  gtw
 SG_ DAS_TR_Obj01_Exist m1 : 56|5@1+ (3.125,0) [0|96.875] "%"  gtw
 SG_ DAS_TR_Obj15_Exist m15 : 56|5@1+ (3.125,0) [0|96.875] "%"  gtw
 SG_ DAS_TR_Obj07_Exist m7 : 56|5@1+ (3.125,0) [0|96.875] "%"  gtw
 SG_ DAS_TR_Obj25_Exist m25 : 56|5@1+ (3.125,0) [0|96.875] "%"  gtw
 SG_ DAS_TR_Counter : 54|2@1+ (1,0) [0|3] ""  gtw
 SG_ DAS_TR_Obj16_Dz m16 : 48|6@1+ (0.25,-5) [-5|10.75] "m"  gtw
 SG_ DAS_TR_Obj11_Dz m11 : 48|6@1+ (0.25,-5) [-5|10.75] "m"  gtw
 SG_ DAS_TR_Obj08_Dz m8 : 48|6@1+ (0.25,-5) [-5|10.75] "m"  gtw
 SG_ DAS_TR_Obj27_Dz m27 : 48|6@1+ (0.25,-5) [-5|10.75] "m"  gtw
 SG_ DAS_TR_Obj05_Dz m5 : 48|6@1+ (0.25,-5) [-5|10.75] "m"  gtw
 SG_ DAS_TR_Obj24_Dz m24 : 48|6@1+ (0.25,-5) [-5|10.75] "m"  gtw
 SG_ DAS_TR_Obj06_Dz m6 : 48|6@1+ (0.25,-5) [-5|10.75] "m"  gtw
 SG_ DAS_TR_Obj03_Dz m3 : 48|6@1+ (0.25,-5) [-5|10.75] "m"  gtw
 SG_ DAS_TR_Obj21_Dz m21 : 48|6@1+ (0.25,-5) [-5|10.75] "m"  gtw
 SG_ DAS_TR_Obj15_Dz m15 : 48|6@1+ (0.25,-5) [-5|10.75] "m"  gtw
 SG_ DAS_TR_Obj10_Dz m10 : 48|6@1+ (0.25,-5) [-5|10.75] "m"  gtw
 SG_ DAS_TR_Obj09_Dz m9 : 48|6@1+ (0.25,-5) [-5|10.75] "m"  gtw
 SG_ DAS_TR_Obj31_Dz m31 : 48|6@1+ (0.25,-5) [-5|10.75] "m"  gtw
 SG_ DAS_TR_Obj13_Dz m13 : 48|6@1+ (0.25,-5) [-5|10.75] "m"  gtw
 SG_ DAS_TR_Obj28_Dz m28 : 48|6@1+ (0.25,-5) [-5|10.75] "m"  gtw
 SG_ DAS_TR_Obj25_Dz m25 : 48|6@1+ (0.25,-5) [-5|10.75] "m"  gtw
 SG_ DAS_TR_Obj07_Dz m7 : 48|6@1+ (0.25,-5) [-5|10.75] "m"  gtw
 SG_ DAS_TR_Obj19_Dz m19 : 48|6@1+ (0.25,-5) [-5|10.75] "m"  gtw
 SG_ DAS_TR_Obj22_Dz m22 : 48|6@1+ (0.25,-5) [-5|10.75] "m"  gtw
 SG_ DAS_TR_Obj00_Dz m0 : 48|6@1+ (0.25,-5) [-5|10.75] "m"  gtw
 SG_ DAS_TR_Obj14_Dz m14 : 48|6@1+ (0.25,-5) [-5|10.75] "m"  gtw
 SG_ DAS_TR_Obj17_Dz m17 : 48|6@1+ (0.25,-5) [-5|10.75] "m"  gtw
 SG_ DAS_TR_Obj12_Dz m12 : 48|6@1+ (0.25,-5) [-5|10.75] "m"  gtw
 SG_ DAS_TR_Obj29_Dz m29 : 48|6@1+ (0.25,-5) [-5|10.75] "m"  gtw
 SG_ DAS_TR_Obj30_Dz m30 : 48|6@1+ (0.25,-5) [-5|10.75] "m"  gtw
 SG_ DAS_TR_Obj04_Dz m4 : 48|6@1+ (0.25,-5) [-5|10.75] "m"  gtw
 SG_ DAS_TR_Obj26_Dz m26 : 48|6@1+ (0.25,-5) [-5|10.75] "m"  gtw
 SG_ DAS_TR_Obj01_Dz m1 : 48|6@1+ (0.25,-5) [-5|10.75] "m"  gtw
 SG_ DAS_TR_Obj18_Dz m18 : 48|6@1+ (0.25,-5) [-5|10.75] "m"  gtw
 SG_ DAS_TR_Obj23_Dz m23 : 48|6@1+ (0.25,-5) [-5|10.75] "m"  gtw
 SG_ DAS_TR_Obj20_Dz m20 : 48|6@1+ (0.25,-5) [-5|10.75] "m"  gtw
 SG_ DAS_TR_Obj02_Dz m2 : 48|6@1+ (0.25,-5) [-5|10.75] "m"  gtw
 SG_ DAS_TR_Obj20_MovingState m20 : 46|2@1+ (1,0) [0|3] ""  gtw
 SG_ DAS_TR_Obj02_MovingState m2 : 46|2@1+ (1,0) [0|3] ""  gtw
 SG_ DAS_TR_Obj14_MovingState m14 : 46|2@1+ (1,0) [0|3] ""  gtw
 SG_ DAS_TR_Obj08_MovingState m8 : 46|2@1+ (1,0) [0|3] ""  gtw
 SG_ DAS_TR_Obj11_MovingState m11 : 46|2@1+ (1,0) [0|3] ""  gtw
 SG_ DAS_TR_Obj21_MovingState m21 : 46|2@1+ (1,0) [0|3] ""  gtw
 SG_ DAS_TR_Obj03_MovingState m3 : 46|2@1+ (1,0) [0|3] ""  gtw
 SG_ DAS_TR_Obj17_MovingState m17 : 46|2@1+ (1,0) [0|3] ""  gtw
 SG_ DAS_TR_Obj09_MovingState m9 : 46|2@1+ (1,0) [0|3] ""  gtw
 SG_ DAS_TR_Obj10_MovingState m10 : 46|2@1+ (1,0) [0|3] ""  gtw
 SG_ DAS_TR_Obj26_MovingState m26 : 46|2@1+ (1,0) [0|3] ""  gtw
 SG_ DAS_TR_Obj04_MovingState m4 : 46|2@1+ (1,0) [0|3] ""  gtw
 SG_ DAS_TR_Obj16_MovingState m16 : 46|2@1+ (1,0) [0|3] ""  gtw
 SG_ DAS_TR_Obj13_MovingState m13 : 46|2@1+ (1,0) [0|3] ""  gtw
 SG_ DAS_TR_Obj31_MovingState m31 : 46|2@1+ (1,0) [0|3] ""  gtw
 SG_ DAS_TR_Obj28_MovingState m28 : 46|2@1+ (1,0) [0|3] ""  gtw
 SG_ DAS_TR_Obj05_MovingState m5 : 46|2@1+ (1,0) [0|3] ""  gtw
 SG_ DAS_TR_Obj27_MovingState m27 : 46|2@1+ (1,0) [0|3] ""  gtw
 SG_ DAS_TR_Obj00_MovingState m0 : 46|2@1+ (1,0) [0|3] ""  gtw
 SG_ DAS_TR_Obj19_MovingState m19 : 46|2@1+ (1,0) [0|3] ""  gtw
 SG_ DAS_TR_Obj22_MovingState m22 : 46|2@1+ (1,0) [0|3] ""  gtw
 SG_ DAS_TR_Obj29_MovingState m29 : 46|2@1+ (1,0) [0|3] ""  gtw
 SG_ DAS_TR_Obj30_MovingState m30 : 46|2@1+ (1,0) [0|3] ""  gtw
 SG_ DAS_TR_Obj12_MovingState m12 : 46|2@1+ (1,0) [0|3] ""  gtw
 SG_ DAS_TR_Obj06_MovingState m6 : 46|2@1+ (1,0) [0|3] ""  gtw
 SG_ DAS_TR_Obj24_MovingState m24 : 46|2@1+ (1,0) [0|3] ""  gtw
 SG_ DAS_TR_Obj01_MovingState m1 : 46|2@1+ (1,0) [0|3] ""  gtw
 SG_ DAS_TR_Obj18_MovingState m18 : 46|2@1+ (1,0) [0|3] ""  gtw
 SG_ DAS_TR_Obj23_MovingState m23 : 46|2@1+ (1,0) [0|3] ""  gtw
 SG_ DAS_TR_Obj15_MovingState m15 : 46|2@1+ (1,0) [0|3] ""  gtw
 SG_ DAS_TR_Obj25_MovingState m25 : 46|2@1+ (1,0) [0|3] ""  gtw
 SG_ DAS_TR_Obj07_MovingState m7 : 46|2@1+ (1,0) [0|3] ""  gtw
 SG_ DAS_TR_Obj14_Length m14 : 40|6@1+ (0.125,0) [0|7.875] "m"  gtw
 SG_ DAS_TR_Obj13_Length m13 : 40|6@1+ (0.125,0) [0|7.875] "m"  gtw
 SG_ DAS_TR_Obj28_Length m28 : 40|6@1+ (0.125,0) [0|7.875] "m"  gtw
 SG_ DAS_TR_Obj31_Length m31 : 40|6@1+ (0.125,0) [0|7.875] "m"  gtw
 SG_ DAS_TR_Obj25_Length m25 : 40|6@1+ (0.125,0) [0|7.875] "m"  gtw
 SG_ DAS_TR_Obj07_Length m7 : 40|6@1+ (0.125,0) [0|7.875] "m"  gtw
 SG_ DAS_TR_Obj26_Length m26 : 40|6@1+ (0.125,0) [0|7.875] "m"  gtw
 SG_ DAS_TR_Obj04_Length m4 : 40|6@1+ (0.125,0) [0|7.875] "m"  gtw
 SG_ DAS_TR_Obj01_Length m1 : 40|6@1+ (0.125,0) [0|7.875] "m"  gtw
 SG_ DAS_TR_Obj18_Length m18 : 40|6@1+ (0.125,0) [0|7.875] "m"  gtw
 SG_ DAS_TR_Obj23_Length m23 : 40|6@1+ (0.125,0) [0|7.875] "m"  gtw
 SG_ DAS_TR_Obj17_Length m17 : 40|6@1+ (0.125,0) [0|7.875] "m"  gtw
 SG_ DAS_TR_Obj30_Length m30 : 40|6@1+ (0.125,0) [0|7.875] "m"  gtw
 SG_ DAS_TR_Obj12_Length m12 : 40|6@1+ (0.125,0) [0|7.875] "m"  gtw
 SG_ DAS_TR_Obj29_Length m29 : 40|6@1+ (0.125,0) [0|7.875] "m"  gtw
 SG_ DAS_TR_Obj11_Length m11 : 40|6@1+ (0.125,0) [0|7.875] "m"  gtw
 SG_ DAS_TR_Obj08_Length m8 : 40|6@1+ (0.125,0) [0|7.875] "m"  gtw
 SG_ DAS_TR_Obj05_Length m5 : 40|6@1+ (0.125,0) [0|7.875] "m"  gtw
 SG_ DAS_TR_Obj27_Length m27 : 40|6@1+ (0.125,0) [0|7.875] "m"  gtw
 SG_ DAS_TR_Obj02_Length m2 : 40|6@1+ (0.125,0) [0|7.875] "m"  gtw
 SG_ DAS_TR_Obj20_Length m20 : 40|6@1+ (0.125,0) [0|7.875] "m"  gtw
 SG_ DAS_TR_Obj16_Length m16 : 40|6@1+ (0.125,0) [0|7.875] "m"  gtw
 SG_ DAS_TR_Obj15_Length m15 : 40|6@1+ (0.125,0) [0|7.875] "m"  gtw
 SG_ DAS_TR_Obj10_Length m10 : 40|6@1+ (0.125,0) [0|7.875] "m"  gtw
 SG_ DAS_TR_Obj09_Length m9 : 40|6@1+ (0.125,0) [0|7.875] "m"  gtw
 SG_ DAS_TR_Obj06_Length m6 : 40|6@1+ (0.125,0) [0|7.875] "m"  gtw
 SG_ DAS_TR_Obj24_Length m24 : 40|6@1+ (0.125,0) [0|7.875] "m"  gtw
 SG_ DAS_TR_Obj21_Length m21 : 40|6@1+ (0.125,0) [0|7.875] "m"  gtw
 SG_ DAS_TR_Obj03_Length m3 : 40|6@1+ (0.125,0) [0|7.875] "m"  gtw
 SG_ DAS_TR_Obj00_Length m0 : 40|6@1+ (0.125,0) [0|7.875] "m"  gtw
 SG_ DAS_TR_Obj19_Length m19 : 40|6@1+ (0.125,0) [0|7.875] "m"  gtw
 SG_ DAS_TR_Obj22_Length m22 : 40|6@1+ (0.125,0) [0|7.875] "m"  gtw
 SG_ DAS_TR_Obj21_RCS m21 : 32|8@1+ (0.25,-14) [-14|49.75] "dB"  gtw
 SG_ DAS_TR_Obj03_RCS m3 : 32|8@1+ (0.25,-14) [-14|49.75] "dB"  gtw
 SG_ DAS_TR_Obj15_RCS m15 : 32|8@1+ (0.25,-14) [-14|49.75] "dB"  gtw
 SG_ DAS_TR_Obj09_RCS m9 : 32|8@1+ (0.25,-14) [-14|49.75] "dB"  gtw
 SG_ DAS_TR_Obj10_RCS m10 : 32|8@1+ (0.25,-14) [-14|49.75] "dB"  gtw
 SG_ DAS_TR_Obj02_RCS m2 : 32|8@1+ (0.25,-14) [-14|49.75] "dB"  gtw
 SG_ DAS_TR_Obj20_RCS m20 : 32|8@1+ (0.25,-14) [-14|49.75] "dB"  gtw
 SG_ DAS_TR_Obj16_RCS m16 : 32|8@1+ (0.25,-14) [-14|49.75] "dB"  gtw
 SG_ DAS_TR_Obj08_RCS m8 : 32|8@1+ (0.25,-14) [-14|49.75] "dB"  gtw
 SG_ DAS_TR_Obj11_RCS m11 : 32|8@1+ (0.25,-14) [-14|49.75] "dB"  gtw
 SG_ DAS_TR_Obj27_RCS m27 : 32|8@1+ (0.25,-14) [-14|49.75] "dB"  gtw
 SG_ DAS_TR_Obj05_RCS m5 : 32|8@1+ (0.25,-14) [-14|49.75] "dB"  gtw
 SG_ DAS_TR_Obj17_RCS m17 : 32|8@1+ (0.25,-14) [-14|49.75] "dB"  gtw
 SG_ DAS_TR_Obj29_RCS m29 : 32|8@1+ (0.25,-14) [-14|49.75] "dB"  gtw
 SG_ DAS_TR_Obj30_RCS m30 : 32|8@1+ (0.25,-14) [-14|49.75] "dB"  gtw
 SG_ DAS_TR_Obj12_RCS m12 : 32|8@1+ (0.25,-14) [-14|49.75] "dB"  gtw
 SG_ DAS_TR_Obj26_RCS m26 : 32|8@1+ (0.25,-14) [-14|49.75] "dB"  gtw
 SG_ DAS_TR_Obj04_RCS m4 : 32|8@1+ (0.25,-14) [-14|49.75] "dB"  gtw
 SG_ DAS_TR_Obj01_RCS m1 : 32|8@1+ (0.25,-14) [-14|49.75] "dB"  gtw
 SG_ DAS_TR_Obj18_RCS m18 : 32|8@1+ (0.25,-14) [-14|49.75] "dB"  gtw
 SG_ DAS_TR_Obj23_RCS m23 : 32|8@1+ (0.25,-14) [-14|49.75] "dB"  gtw
 SG_ DAS_TR_Obj31_RCS m31 : 32|8@1+ (0.25,-14) [-14|49.75] "dB"  gtw
 SG_ DAS_TR_Obj28_RCS m28 : 32|8@1+ (0.25,-14) [-14|49.75] "dB"  gtw
 SG_ DAS_TR_Obj13_RCS m13 : 32|8@1+ (0.25,-14) [-14|49.75] "dB"  gtw
 SG_ DAS_TR_Obj25_RCS m25 : 32|8@1+ (0.25,-14) [-14|49.75] "dB"  gtw
 SG_ DAS_TR_Obj07_RCS m7 : 32|8@1+ (0.25,-14) [-14|49.75] "dB"  gtw
 SG_ DAS_TR_Obj00_RCS m0 : 32|8@1+ (0.25,-14) [-14|49.75] "dB"  gtw
 SG_ DAS_TR_Obj19_RCS m19 : 32|8@1+ (0.25,-14) [-14|49.75] "dB"  gtw
 SG_ DAS_TR_Obj22_RCS m22 : 32|8@1+ (0.25,-14) [-14|49.75] "dB"  gtw
 SG_ DAS_TR_Obj14_RCS m14 : 32|8@1+ (0.25,-14) [-14|49.75] "dB"  gtw
 SG_ DAS_TR_Obj24_RCS m24 : 32|8@1+ (0.25,-14) [-14|49.75] "dB"  gtw
 SG_ DAS_TR_Obj06_RCS m6 : 32|8@1+ (0.25,-14) [-14|49.75] "dB"  gtw
 SG_ DAS_TR_Obj16_Vx m16 : 24|8@1+ (0.5,-63.5) [-63.5|64] "m/s"  gtw
 SG_ DAS_TR_Obj08_Vx m8 : 24|8@1+ (0.5,-63.5) [-63.5|64] "m/s"  gtw
 SG_ DAS_TR_Obj11_Vx m11 : 24|8@1+ (0.5,-63.5) [-63.5|64] "m/s"  gtw
 SG_ DAS_TR_Obj27_Vx m27 : 24|8@1+ (0.5,-63.5) [-63.5|64] "m/s"  gtw
 SG_ DAS_TR_Obj05_Vx m5 : 24|8@1+ (0.5,-63.5) [-63.5|64] "m/s"  gtw
 SG_ DAS_TR_Obj24_Vx m24 : 24|8@1+ (0.5,-63.5) [-63.5|64] "m/s"  gtw
 SG_ DAS_TR_Obj06_Vx m6 : 24|8@1+ (0.5,-63.5) [-63.5|64] "m/s"  gtw
 SG_ DAS_TR_Obj03_Vx m3 : 24|8@1+ (0.5,-63.5) [-63.5|64] "m/s"  gtw
 SG_ DAS_TR_Obj21_Vx m21 : 24|8@1+ (0.5,-63.5) [-63.5|64] "m/s"  gtw
 SG_ DAS_TR_Obj15_Vx m15 : 24|8@1+ (0.5,-63.5) [-63.5|64] "m/s"  gtw
 SG_ DAS_TR_Obj09_Vx m9 : 24|8@1+ (0.5,-63.5) [-63.5|64] "m/s"  gtw
 SG_ DAS_TR_Obj10_Vx m10 : 24|8@1+ (0.5,-63.5) [-63.5|64] "m/s"  gtw
 SG_ DAS_TR_Obj28_Vx m28 : 24|8@1+ (0.5,-63.5) [-63.5|64] "m/s"  gtw
 SG_ DAS_TR_Obj13_Vx m13 : 24|8@1+ (0.5,-63.5) [-63.5|64] "m/s"  gtw
 SG_ DAS_TR_Obj31_Vx m31 : 24|8@1+ (0.5,-63.5) [-63.5|64] "m/s"  gtw
 SG_ DAS_TR_Obj07_Vx m7 : 24|8@1+ (0.5,-63.5) [-63.5|64] "m/s"  gtw
 SG_ DAS_TR_Obj25_Vx m25 : 24|8@1+ (0.5,-63.5) [-63.5|64] "m/s"  gtw
 SG_ DAS_TR_Obj22_Vx m22 : 24|8@1+ (0.5,-63.5) [-63.5|64] "m/s"  gtw
 SG_ DAS_TR_Obj19_Vx m19 : 24|8@1+ (0.5,-63.5) [-63.5|64] "m/s"  gtw
 SG_ DAS_TR_Obj00_Vx m0 : 24|8@1+ (0.5,-63.5) [-63.5|64] "m/s"  gtw
 SG_ DAS_TR_Obj14_Vx m14 : 24|8@1+ (0.5,-63.5) [-63.5|64] "m/s"  gtw
 SG_ DAS_TR_Obj17_Vx m17 : 24|8@1+ (0.5,-63.5) [-63.5|64] "m/s"  gtw
 SG_ DAS_TR_Obj29_Vx m29 : 24|8@1+ (0.5,-63.5) [-63.5|64] "m/s"  gtw
 SG_ DAS_TR_Obj30_Vx m30 : 24|8@1+ (0.5,-63.5) [-63.5|64] "m/s"  gtw
 SG_ DAS_TR_Obj12_Vx m12 : 24|8@1+ (0.5,-63.5) [-63.5|64] "m/s"  gtw
 SG_ DAS_TR_Obj26_Vx m26 : 24|8@1+ (0.5,-63.5) [-63.5|64] "m/s"  gtw
 SG_ DAS_TR_Obj04_Vx m4 : 24|8@1+ (0.5,-63.5) [-63.5|64] "m/s"  gtw
 SG_ DAS_TR_Obj23_Vx m23 : 24|8@1+ (0.5,-63.5) [-63.5|64] "m/s"  gtw
 SG_ DAS_TR_Obj01_Vx m1 : 24|8@1+ (0.5,-63.5) [-63.5|64] "m/s"  gtw
 SG_ DAS_TR_Obj18_Vx m18 : 24|8@1+ (0.5,-63.5) [-63.5|64] "m/s"  gtw
 SG_ DAS_TR_Obj02_Vx m2 : 24|8@1+ (0.5,-63.5) [-63.5|64] "m/s"  gtw
 SG_ DAS_TR_Obj20_Vx m20 : 24|8@1+ (0.5,-63.5) [-63.5|64] "m/s"  gtw
 SG_ DAS_TR_Obj04_Dy m4 : 18|6@1+ (0.5,-15.5) [-15.5|16] "m"  gtw
 SG_ DAS_TR_Obj26_Dy m26 : 18|6@1+ (0.5,-15.5) [-15.5|16] "m"  gtw
 SG_ DAS_TR_Obj21_Dy m21 : 18|6@1+ (0.5,-15.5) [-15.5|16] "m"  gtw
 SG_ DAS_TR_Obj03_Dy m3 : 18|6@1+ (0.5,-15.5) [-15.5|16] "m"  gtw
 SG_ DAS_TR_Obj17_Dy m17 : 18|6@1+ (0.5,-15.5) [-15.5|16] "m"  gtw
 SG_ DAS_TR_Obj14_Dy m14 : 18|6@1+ (0.5,-15.5) [-15.5|16] "m"  gtw
 SG_ DAS_TR_Obj11_Dy m11 : 18|6@1+ (0.5,-15.5) [-15.5|16] "m"  gtw
 SG_ DAS_TR_Obj08_Dy m8 : 18|6@1+ (0.5,-15.5) [-15.5|16] "m"  gtw
 SG_ DAS_TR_Obj25_Dy m25 : 18|6@1+ (0.5,-15.5) [-15.5|16] "m"  gtw
 SG_ DAS_TR_Obj07_Dy m7 : 18|6@1+ (0.5,-15.5) [-15.5|16] "m"  gtw
 SG_ DAS_TR_Obj20_Dy m20 : 18|6@1+ (0.5,-15.5) [-15.5|16] "m"  gtw
 SG_ DAS_TR_Obj02_Dy m2 : 18|6@1+ (0.5,-15.5) [-15.5|16] "m"  gtw
 SG_ DAS_TR_Obj23_Dy m23 : 18|6@1+ (0.5,-15.5) [-15.5|16] "m"  gtw
 SG_ DAS_TR_Obj01_Dy m1 : 18|6@1+ (0.5,-15.5) [-15.5|16] "m"  gtw
 SG_ DAS_TR_Obj18_Dy m18 : 18|6@1+ (0.5,-15.5) [-15.5|16] "m"  gtw
 SG_ DAS_TR_Obj15_Dy m15 : 18|6@1+ (0.5,-15.5) [-15.5|16] "m"  gtw
 SG_ DAS_TR_Obj30_Dy m30 : 18|6@1+ (0.5,-15.5) [-15.5|16] "m"  gtw
 SG_ DAS_TR_Obj12_Dy m12 : 18|6@1+ (0.5,-15.5) [-15.5|16] "m"  gtw
 SG_ DAS_TR_Obj29_Dy m29 : 18|6@1+ (0.5,-15.5) [-15.5|16] "m"  gtw
 SG_ DAS_TR_Obj24_Dy m24 : 18|6@1+ (0.5,-15.5) [-15.5|16] "m"  gtw
 SG_ DAS_TR_Obj06_Dy m6 : 18|6@1+ (0.5,-15.5) [-15.5|16] "m"  gtw
 SG_ DAS_TR_Obj05_Dy m5 : 18|6@1+ (0.5,-15.5) [-15.5|16] "m"  gtw
 SG_ DAS_TR_Obj27_Dy m27 : 18|6@1+ (0.5,-15.5) [-15.5|16] "m"  gtw
 SG_ DAS_TR_Obj00_Dy m0 : 18|6@1+ (0.5,-15.5) [-15.5|16] "m"  gtw
 SG_ DAS_TR_Obj19_Dy m19 : 18|6@1+ (0.5,-15.5) [-15.5|16] "m"  gtw
 SG_ DAS_TR_Obj22_Dy m22 : 18|6@1+ (0.5,-15.5) [-15.5|16] "m"  gtw
 SG_ DAS_TR_Obj16_Dy m16 : 18|6@1+ (0.5,-15.5) [-15.5|16] "m"  gtw
 SG_ DAS_TR_Obj28_Dy m28 : 18|6@1+ (0.5,-15.5) [-15.5|16] "m"  gtw
 SG_ DAS_TR_Obj31_Dy m31 : 18|6@1+ (0.5,-15.5) [-15.5|16] "m"  gtw
 SG_ DAS_TR_Obj13_Dy m13 : 18|6@1+ (0.5,-15.5) [-15.5|16] "m"  gtw
 SG_ DAS_TR_Obj10_Dy m10 : 18|6@1+ (0.5,-15.5) [-15.5|16] "m"  gtw
 SG_ DAS_TR_Obj09_Dy m9 : 18|6@1+ (0.5,-15.5) [-15.5|16] "m"  gtw
 SG_ DAS_TR_Obj14_Dx m14 : 8|10@1+ (0.15625,0) [0|159.84375] "m"  gtw
 SG_ DAS_TR_Obj31_Dx m31 : 8|10@1+ (0.15625,0) [0|159.84375] "m"  gtw
 SG_ DAS_TR_Obj13_Dx m13 : 8|10@1+ (0.15625,0) [0|159.84375] "m"  gtw
 SG_ DAS_TR_Obj28_Dx m28 : 8|10@1+ (0.15625,0) [0|159.84375] "m"  gtw
 SG_ DAS_TR_Obj25_Dx m25 : 8|10@1+ (0.15625,0) [0|159.84375] "m"  gtw
 SG_ DAS_TR_Obj07_Dx m7 : 8|10@1+ (0.15625,0) [0|159.84375] "m"  gtw
 SG_ DAS_TR_Obj26_Dx m26 : 8|10@1+ (0.15625,0) [0|159.84375] "m"  gtw
 SG_ DAS_TR_Obj04_Dx m4 : 8|10@1+ (0.15625,0) [0|159.84375] "m"  gtw
 SG_ DAS_TR_Obj01_Dx m1 : 8|10@1+ (0.15625,0) [0|159.84375] "m"  gtw
 SG_ DAS_TR_Obj18_Dx m18 : 8|10@1+ (0.15625,0) [0|159.84375] "m"  gtw
 SG_ DAS_TR_Obj23_Dx m23 : 8|10@1+ (0.15625,0) [0|159.84375] "m"  gtw
 SG_ DAS_TR_Obj17_Dx m17 : 8|10@1+ (0.15625,0) [0|159.84375] "m"  gtw
 SG_ DAS_TR_Obj12_Dx m12 : 8|10@1+ (0.15625,0) [0|159.84375] "m"  gtw
 SG_ DAS_TR_Obj29_Dx m29 : 8|10@1+ (0.15625,0) [0|159.84375] "m"  gtw
 SG_ DAS_TR_Obj30_Dx m30 : 8|10@1+ (0.15625,0) [0|159.84375] "m"  gtw
 SG_ DAS_TR_Obj11_Dx m11 : 8|10@1+ (0.15625,0) [0|159.84375] "m"  gtw
 SG_ DAS_TR_Obj08_Dx m8 : 8|10@1+ (0.15625,0) [0|159.84375] "m"  gtw
 SG_ DAS_TR_Obj27_Dx m27 : 8|10@1+ (0.15625,0) [0|159.84375] "m"  gtw
 SG_ DAS_TR_Obj05_Dx m5 : 8|10@1+ (0.15625,0) [0|159.84375] "m"  gtw
 SG_ DAS_TR_Obj02_Dx m2 : 8|10@1+ (0.15625,0) [0|159.84375] "m"  gtw
 SG_ DAS_TR_Obj20_Dx m20 : 8|10@1+ (0.15625,0) [0|159.84375] "m"  gtw
 SG_ DAS_TR_Obj16_Dx m16 : 8|10@1+ (0.15625,0) [0|159.84375] "m"  gtw
 SG_ DAS_TR_Obj15_Dx m15 : 8|10@1+ (0.15625,0) [0|159.84375] "m"  gtw
 SG_ DAS_TR_Obj09_Dx m9 : 8|10@1+ (0.15625,0) [0|159.84375] "m"  gtw
 SG_ DAS_TR_Obj10_Dx m10 : 8|10@1+ (0.15625,0) [0|159.84375] "m"  gtw
 SG_ DAS_TR_Obj06_Dx m6 : 8|10@1+ (0.15625,0) [0|159.84375] "m"  gtw
 SG_ DAS_TR_Obj24_Dx m24 : 8|10@1+ (0.15625,0) [0|159.84375] "m"  gtw
 SG_ DAS_TR_Obj03_Dx m3 : 8|10@1+ (0.15625,0) [0|159.84375] "m"  gtw
 SG_ DAS_TR_Obj21_Dx m21 : 8|10@1+ (0.15625,0) [0|159.84375] "m"  gtw
 SG_ DAS_TR_Obj19_Dx m19 : 8|10@1+ (0.15625,0) [0|159.84375] "m"  gtw
 SG_ DAS_TR_Obj22_Dx m22 : 8|10@1+ (0.15625,0) [0|159.84375] "m"  gtw
 SG_ DAS_TR_Obj00_Dx m0 : 8|10@1+ (0.15625,0) [0|159.84375] "m"  gtw
 SG_ DAS_TR_Obj16_Class m16 : 5|3@1+ (1,0) [0|7] ""  gtw
 SG_ DAS_TR_Obj19_Class m19 : 5|3@1+ (1,0) [0|7] ""  gtw
 SG_ DAS_TR_Obj22_Class m22 : 5|3@1+ (1,0) [0|7] ""  gtw
 SG_ DAS_TR_Obj00_Class m0 : 5|3@1+ (1,0) [0|4] ""  gtw
 SG_ DAS_TR_Obj27_Class m27 : 5|3@1+ (1,0) [0|7] ""  gtw
 SG_ DAS_TR_Obj05_Class m5 : 5|3@1+ (1,0) [0|7] ""  gtw
 SG_ DAS_TR_Obj17_Class m17 : 5|3@1+ (1,0) [0|7] ""  gtw
 SG_ DAS_TR_Obj21_Class m21 : 5|3@1+ (1,0) [0|7] ""  gtw
 SG_ DAS_TR_Obj03_Class m3 : 5|3@1+ (1,0) [0|7] ""  gtw
 SG_ DAS_TR_Obj04_Class m4 : 5|3@1+ (1,0) [0|7] ""  gtw
 SG_ DAS_TR_Obj26_Class m26 : 5|3@1+ (1,0) [0|7] ""  gtw
 SG_ DAS_TR_Obj09_Class m9 : 5|3@1+ (1,0) [0|7] ""  gtw
 SG_ DAS_TR_Obj10_Class m10 : 5|3@1+ (1,0) [0|7] ""  gtw
 SG_ DAS_TR_Obj20_Class m20 : 5|3@1+ (1,0) [0|7] ""  gtw
 SG_ DAS_TR_Obj02_Class m2 : 5|3@1+ (1,0) [0|7] ""  gtw
 SG_ DAS_TR_Obj25_Class m25 : 5|3@1+ (1,0) [0|7] ""  gtw
 SG_ DAS_TR_Obj07_Class m7 : 5|3@1+ (1,0) [0|7] ""  gtw
 SG_ DAS_TR_Obj08_Class m8 : 5|3@1+ (1,0) [0|7] ""  gtw
 SG_ DAS_TR_Obj11_Class m11 : 5|3@1+ (1,0) [0|7] ""  gtw
 SG_ DAS_TR_Obj14_Class m14 : 5|3@1+ (1,0) [0|7] ""  gtw
 SG_ DAS_TR_Obj06_Class m6 : 5|3@1+ (1,0) [0|7] ""  gtw
 SG_ DAS_TR_Obj24_Class m24 : 5|3@1+ (1,0) [0|7] ""  gtw
 SG_ DAS_TR_Obj12_Class m12 : 5|3@1+ (1,0) [0|7] ""  gtw
 SG_ DAS_TR_Obj30_Class m30 : 5|3@1+ (1,0) [0|7] ""  gtw
 SG_ DAS_TR_Obj29_Class m29 : 5|3@1+ (1,0) [0|7] ""  gtw
 SG_ DAS_TR_Obj15_Class m15 : 5|3@1+ (1,0) [0|7] ""  gtw
 SG_ DAS_TR_Obj18_Class m18 : 5|3@1+ (1,0) [0|7] ""  gtw
 SG_ DAS_TR_Obj01_Class m1 : 5|3@1+ (1,0) [0|7] ""  gtw
 SG_ DAS_TR_Obj23_Class m23 : 5|3@1+ (1,0) [0|7] ""  gtw
 SG_ DAS_TR_Obj31_Class m31 : 5|3@1+ (1,0) [0|7] ""  gtw
 SG_ DAS_TR_Obj13_Class m13 : 5|3@1+ (1,0) [0|7] ""  gtw
 SG_ DAS_TR_Obj28_Class m28 : 5|3@1+ (1,0) [0|7] ""  gtw
 SG_ DAS_TR_ObjIndex M : 0|5@1+ (1,0) [0|31] ""  gtw

BO_ 257 RCM_inertial1: 8 CH
 SG_ RCM_inertial1Checksum : 56|8@1+ (1,0) [0|255] ""  epas3s
 SG_ RCM_inertial1Counter : 52|4@1+ (1,0) [0|15] ""  epas3s
 SG_ RCM_pitchRateQF : 50|2@1+ (1,0) [0|3] ""  gtw
 SG_ RCM_yawRateQF : 48|1@1+ (1,0) [0|1] ""  das
 SG_ RCM_rollRateQF : 46|2@1+ (1,0) [0|3] ""  gtw
 SG_ RCM_rollRate : 31|15@1- (0.00025,0.0) [-4.096|4.09575] "rad/s"  gtw
 SG_ RCM_pitchRate : 16|15@1- (0.00025,0.0) [-4.096|4.09575] "rad/s"  gtw
 SG_ RCM_yawRate : 0|16@1- (0.0001,0.0) [-3.2766|3.2766] "rad/s"  das

BO_ 1425 EPAS3S_alertLog: 8 CH
 SG_ EPAS3S_a084_eacCancelCode m84 : 60|4@1+ (1,0) [0|15] ""  gtw
 SG_ EPAS3S_a084_eacCancelAngle m84 : 48|12@1+ (1,0) [0|4095] ""  gtw
 SG_ EPAS3S_a084_eacCancelAngleGrad m84 : 36|12@1+ (1,0) [0|4095] ""  gtw
 SG_ EPAS3S_a084_eacCancelTtrq m84 : 26|10@1+ (1,0) [0|1023] ""  gtw
 SG_ EPAS3S_a084_eacCancelMtrq m84 : 16|10@1+ (1,0) [0|1023] ""  gtw
 SG_ EPAS3S_alertState : 15|1@1+ (1,0) [0|1] ""  gtw
 SG_ EPAS3S_alertID M : 0|8@1+ (1,0) [0|131] ""  gtw

BO_ 1605 UDS_espRequest: 8 CH
 SG_ UDS_espRequestData : 7|64@0+ (1,0) [0|18446744073709551615] ""  esp

BO_ 1609 UDS_dasRequest: 8 CH
 SG_ UDS_dasRequestData : 7|64@0+ (1,0) [0|18446744073709551615] ""  das

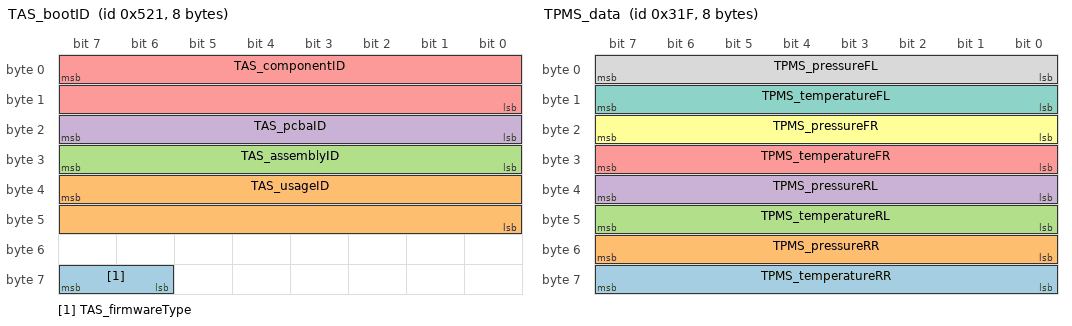
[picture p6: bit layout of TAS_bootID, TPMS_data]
BO_ 1313 TAS_bootID: 8 CH
 SG_ TAS_firmwareType : 63|2@0+ (1,0) [0|2] ""  gtwu
 SG_ TAS_usageID : 39|16@0+ (1,0) [0|65535] ""  gtwu
 SG_ TAS_assemblyID : 31|8@0+ (1,0) [0|255] ""  gtwu
 SG_ TAS_pcbaID : 23|8@0+ (1,0) [0|255] ""  gtwu
 SG_ TAS_componentID : 7|16@0+ (1,0) [0|65535] ""  gtwu

BO_ 849 RCM_info: 8 CH
 SG_ RCM_infoComponentID m10 : 48|16@1+ (1,0) [0|65535] ""  gtw
 SG_ RCM_infoApplicationCRC m13 : 32|32@1+ (1,0) [0|4294967295] ""  gtw
 SG_ RCM_infoUsageID m11 : 32|16@1+ (1,0) [0|65535] ""  gtw
 SG_ RCM_infoBootloaderCRC m20 : 32|32@1+ (1,0) [0|4294967295] ""  gtw
 SG_ RCM_infoVariantCRC m22 : 32|32@1+ (1,0) [0|4294967295] ""  gtw
 SG_ RCM_infoAssemblyID m11 : 24|8@1+ (1,0) [0|255] ""  gtw
 SG_ RCM_infoPcbaID m11 : 16|8@1+ (1,0) [0|255] ""  gtw
 SG_ RCM_infoBuildType m10 : 8|8@1+ (1,0) [0|4] ""  gtw
 SG_ RCM_infoBootUdsProtoVersion m20 : 8|8@1+ (1,0) [0|255] ""  gtw
 SG_ RCM_infoIndex M : 0|8@1+ (1,0) [0|255] ""  gtw

BO_ 799 TPMS_data: 8 CH
 SG_ TPMS_temperatureRR : 56|8@1+ (1,-40) [-40|215] "degC"  gtw
 SG_ TPMS_pressureRR : 48|8@1+ (0.025,0) [0|6.375] "bar"  gtw
 SG_ TPMS_temperatureRL : 40|8@1+ (1,-40) [-40|215] "degC"  gtw
 SG_ TPMS_pressureRL : 32|8@1+ (0.025,0) [0|6.375] "bar"  gtw
 SG_ TPMS_temperatureFR : 24|8@1+ (1,-40) [-40|215] "degC"  gtw
 SG_ TPMS_pressureFR : 16|8@1+ (0.025,0) [0|6.375] "bar"  gtw
 SG_ TPMS_temperatureFL : 8|8@1+ (1,-40) [-40|215] "degC"  gtw
 SG_ TPMS_pressureFL : 0|8@1+ (0.025,0) [0|6.375] "bar"  gtw

BO_ 525 TAS_states: 8 CH
 SG_ TAS_statesChecksum : 56|8@1+ (1,0) [0|255] ""  gtw
 SG_ TAS_statesCounter : 52|4@1+ (1,0) [0|15] ""  gtw
 SG_ TAS_limpHomeMode : 48|3@1+ (1,0) [0|4] ""  gtw
 SG_ TAS_targetLevel : 45|3@1+ (1,0) [0|4] ""  gtw
 SG_ TAS_currentLevel : 42|3@1+ (1,0) [0|4] ""  das
 SG_ TAS_spinnerUI : 41|1@1+ (1,0) [0|1] ""  gtw
 SG_ TAS_redWarningLamp : 40|1@1+ (1,0) [0|1] ""  gtw
 SG_ TAS_yellowWarningLamp : 39|1@1+ (1,0) [0|1] ""  gtw
 SG_ TAS_jackMode : 38|1@1+ (1,0) [0|1] ""  gtw
 SG_ TAS_veryHighAllowed : 37|1@1+ (1,0) [0|1] ""  gtw
 SG_ TAS_highAllowed : 36|1@1+ (1,0) [0|1] ""  gtw
 SG_ TAS_standardAllowed : 35|1@1+ (1,0) [0|1] ""  gtw
 SG_ TAS_lowAllowed : 34|1@1+ (1,0) [0|1] ""  gtw
 SG_ TAS_veryLowAllowed : 33|1@1+ (1,0) [0|1] ""  gtw
 SG_ TAS_leanDetected : 32|1@1+ (1,0) [0|1] ""  gtw
 SG_ TAS_twistDetected : 31|1@1+ (1,0) [0|1] ""  gtw
 SG_ TAS_compressorRun : 30|1@1+ (1,0) [0|1] ""  gtw
 SG_ TAS_filterMode : 27|3@1+ (1,0) [0|7] ""  gtw
 SG_ TAS_runMode : 24|3@1+ (1,0) [0|6] ""  gtw
 SG_ TAS_pressureReservoir : 16|8@1+ (0.1,0) [0|25.5] "bar"  gtw
 SG_ TAS_pressureGallery : 8|8@1+ (0.1,0) [0|25.5] "bar"  gtw
 SG_ TAS_levelingType : 4|4@1+ (1,0) [0|15] ""  gtw
 SG_ TAS_levelingState : 0|4@1+ (1,0) [0|12] ""  gtw

BO_ 921 DAS_status: 8 CH
 SG_ DAS_statusChecksum : 56|8@1+ (1,0) [0|255] ""  aps
 SG_ DAS_statusCounter : 52|4@1+ (1,0) [0|15] ""  aps
 SG_ DAS_summonAvailable : 51|1@1+ (1,0) [0|1] ""  aps
 SG_ DAS_autoLaneChangeState : 46|5@1+ (1,0) [0|31] ""  aps
 SG_ DAS_autopilotHandsOnState : 42|4@1+ (1,0) [0|15] ""  aps
 SG_ DAS_fleetSpeedState : 40|2@1+ (1,0) [0|3] ""  aps
 SG_ DAS_laneDepartureWarning : 37|3@1+ (1,0) [0|5] ""  aps
 SG_ DAS_csaState : 35|2@1+ (1,0) [0|3] ""  aps
 SG_ DAS_sideCollisionInhibit : 34|1@1+ (1,0) [0|1] ""  aps
 SG_ DAS_sideCollisionWarning : 32|2@1+ (1,0) [0|3] ""  aps
 SG_ DAS_sideCollisionAvoid : 30|2@1+ (1,0) [0|3] ""  aps
 SG_ DAS_summonRvsLeashReached : 29|1@1+ (1,0) [0|1] ""  aps
 SG_ DAS_summonFwdLeashReached : 28|1@1+ (1,0) [0|1] ""  aps
 SG_ DAS_autoparkWaitingForBrake : 26|1@1+ (1,0) [0|1] ""  gtw
 SG_ DAS_autoParked : 25|1@1+ (1,0) [0|1] ""  aps
 SG_ DAS_autoparkReady : 24|1@1+ (1,0) [0|1] ""  aps
 SG_ DAS_forwardCollisionWarning : 22|2@1+ (1,0) [0|3] ""  aps
 SG_ DAS_heaterState : 21|1@1+ (1,0) [0|1] ""  gtw
 SG_ DAS_visionOnlySpeedLimit : 16|5@1+ (5,0) [0|150] "kph/mph"  aps
 SG_ DAS_summonClearedGate : 15|1@1+ (1,0) [0|1] ""  aps
 SG_ DAS_summonObstacle : 14|1@1+ (1,0) [0|1] ""  aps
 SG_ DAS_suppressSpeedWarning : 13|1@1+ (1,0) [0|1] ""  aps
 SG_ DAS_fusedSpeedLimit : 8|5@1+ (5,0) [0|150] "kph/mph"  aps
 SG_ DAS_blindSpotRearRight : 6|2@1+ (1,0) [0|3] ""  aps
 SG_ DAS_blindSpotRearLeft : 4|2@1+ (1,0) [0|3] ""  aps
 SG_ DAS_autopilotState : 0|4@1+ (1,0) [0|15] ""  aps

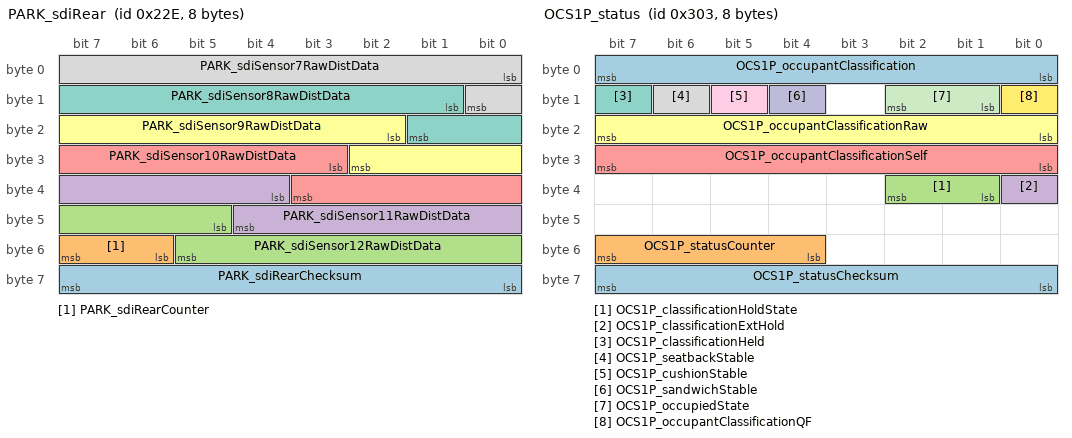
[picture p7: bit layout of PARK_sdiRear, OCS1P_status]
BO_ 558 PARK_sdiRear: 8 CH
 SG_ PARK_sdiRearChecksum : 56|8@1+ (1,0) [0|255] ""  X
 SG_ PARK_sdiRearCounter : 54|2@1+ (1,0) [0|3] ""  das
 SG_ PARK_sdiSensor12RawDistData : 45|9@1+ (1,0) [0|511] "cm"  das
 SG_ PARK_sdiSensor11RawDistData : 36|9@1+ (1,0) [0|511] "cm"  das
 SG_ PARK_sdiSensor10RawDistData : 27|9@1+ (1,0) [0|511] "cm"  app
 SG_ PARK_sdiSensor9RawDistData : 18|9@1+ (1,0) [0|511] "cm"  app
 SG_ PARK_sdiSensor8RawDistData : 9|9@1+ (1,0) [0|511] "cm"  das
 SG_ PARK_sdiSensor7RawDistData : 0|9@1+ (1,0) [0|511] "cm"  das

BO_ 913 EPAS3S_alertMatrix: 8 CH
 SG_ EPAS3S_a060_battBridgeDiff m0 : 63|1@1+ (1,0) [0|1] ""  gtw
 SG_ EPAS3S_a120_pvtEcuStatCntError m1 : 63|1@1+ (1,0) [0|1] ""  gtw
 SG_ EPAS3S_a119_pvtEcuStatMia m1 : 62|1@1+ (1,0) [0|1] ""  gtw
 SG_ EPAS3S_a059_battOvReduced m0 : 62|1@1+ (1,0) [0|1] ""  gtw
 SG_ EPAS3S_a058_battOv m0 : 61|1@1+ (1,0) [0|1] ""  gtw
 SG_ EPAS3S_a118_privateBusOff m1 : 61|1@1+ (1,0) [0|1] ""  gtw
 SG_ EPAS3S_a057_battUvReduced m0 : 60|1@1+ (1,0) [0|1] ""  gtw
 SG_ EPAS3S_a117_ecuStatCrcError m1 : 60|1@1+ (1,0) [0|1] ""  gtw
 SG_ EPAS3S_a116_ecuStatCntError m1 : 59|1@1+ (1,0) [0|1] ""  gtw
 SG_ EPAS3S_a056_battUv m0 : 59|1@1+ (1,0) [0|1] ""  gtw
 SG_ EPAS3S_a055_floatPointError m0 : 58|1@1+ (1,0) [0|1] ""  gtw
 SG_ EPAS3S_a115_ecuStatMia m1 : 58|1@1+ (1,0) [0|1] ""  gtw
 SG_ EPAS3S_a114_gtwConfigMia m1 : 57|1@1+ (1,0) [0|1] ""  gtw
 SG_ EPAS3S_a054_memoryProtectError m0 : 57|1@1+ (1,0) [0|1] ""  gtw
 SG_ EPAS3S_a113_sasStatusError m1 : 56|1@1+ (1,0) [0|1] ""  gtw
 SG_ EPAS3S_a053_extWatchdogError m0 : 56|1@1+ (1,0) [0|1] ""  gtw
 SG_ EPAS3S_a112_sasCsError m1 : 55|1@1+ (1,0) [0|1] ""  gtw
 SG_ EPAS3S_a052_intWatchdogError m0 : 55|1@1+ (1,0) [0|1] ""  gtw
 SG_ EPAS3S_a111_sasCntError m1 : 54|1@1+ (1,0) [0|1] ""  gtw
 SG_ EPAS3S_a051_mcuSupError m0 : 54|1@1+ (1,0) [0|1] ""  gtw
 SG_ EPAS3S_a050_mcuSmuError m0 : 53|1@1+ (1,0) [0|1] ""  gtw
 SG_ EPAS3S_a110_sasMia m1 : 53|1@1+ (1,0) [0|1] ""  gtw
 SG_ EPAS3S_a109_uiTuneReqCsError m1 : 52|1@1+ (1,0) [0|1] ""  gtw
 SG_ EPAS3S_a049_piCtrlError m0 : 52|1@1+ (1,0) [0|1] ""  gtw
 SG_ EPAS3S_a048_motPosCalError m0 : 51|1@1+ (1,0) [0|1] ""  gtw
 SG_ EPAS3S_a108_uiTuneReqCntError m1 : 51|1@1+ (1,0) [0|1] ""  gtw
 SG_ EPAS3S_a047_motPosCorrError m0 : 50|1@1+ (1,0) [0|1] ""  gtw
 SG_ EPAS3S_a107_uiTuneReqMia m1 : 50|1@1+ (1,0) [0|1] ""  gtw
 SG_ EPAS3S_a046_motPos2tempError m0 : 49|1@1+ (1,0) [0|1] ""  gtw
 SG_ EPAS3S_a106_vcFrontTempMia m1 : 49|1@1+ (1,0) [0|1] ""  gtw
 SG_ EPAS3S_a105_vcFrontCsError m1 : 48|1@1+ (1,0) [0|1] ""  gtw
 SG_ EPAS3S_a045_motPos2LogicError m0 : 48|1@1+ (1,0) [0|1] ""  gtw
 SG_ EPAS3S_a044_motPos2MagnetMia m0 : 47|1@1+ (1,0) [0|1] ""  gtw
 SG_ EPAS3S_a104_vcFrontCntError m1 : 47|1@1+ (1,0) [0|1] ""  gtw
 SG_ EPAS3S_a103_vcFrontMia m1 : 46|1@1+ (1,0) [0|1] ""  gtw
 SG_ EPAS3S_a043_motPos2Uv m0 : 46|1@1+ (1,0) [0|1] ""  gtw
 SG_ EPAS3S_a102_diCsError m1 : 45|1@1+ (1,0) [0|1] ""  gtw
 SG_ EPAS3S_a042_motPos2ParityError m0 : 45|1@1+ (1,0) [0|1] ""  gtw
 SG_ EPAS3S_a101_diCntError m1 : 44|1@1+ (1,0) [0|1] ""  gtw
 SG_ EPAS3S_a041_motPos1tempError m0 : 44|1@1+ (1,0) [0|1] ""  gtw
 SG_ EPAS3S_a100_diMia m1 : 43|1@1+ (1,0) [0|1] ""  gtw
 SG_ EPAS3S_a040_motPos1LogicError m0 : 43|1@1+ (1,0) [0|1] ""  gtw
 SG_ EPAS3S_a039_motPos1MagnetMia m0 : 42|1@1+ (1,0) [0|1] ""  gtw
 SG_ EPAS3S_a099_yawRateStatus m1 : 42|1@1+ (1,0) [0|1] ""  gtw
 SG_ EPAS3S_a038_motPos1Uv m0 : 41|1@1+ (1,0) [0|1] ""  gtw
 SG_ EPAS3S_a098_rcmCsError m1 : 41|1@1+ (1,0) [0|1] ""  gtw
 SG_ EPAS3S_a037_motPos1ParityError m0 : 40|1@1+ (1,0) [0|1] ""  gtw
 SG_ EPAS3S_a097_rcmCntError m1 : 40|1@1+ (1,0) [0|1] ""  gtw
 SG_ EPAS3S_a096_rcmMia m1 : 39|1@1+ (1,0) [0|1] ""  gtw
 SG_ EPAS3S_a036_vbbSupplyOv m0 : 39|1@1+ (1,0) [0|1] ""  gtw
 SG_ EPAS3S_a035_vbbSupplyUv m0 : 38|1@1+ (1,0) [0|1] ""  gtw
 SG_ EPAS3S_a095_espWsStatus m1 : 38|1@1+ (1,0) [0|1] ""  gtw
 SG_ EPAS3S_a094_espWrCsError m1 : 37|1@1+ (1,0) [0|1] ""  gtw
 SG_ EPAS3S_a034_vRegError m0 : 37|1@1+ (1,0) [0|1] ""  gtw
 SG_ EPAS3S_a093_espWrCntError m1 : 36|1@1+ (1,0) [0|1] ""  gtw
 SG_ EPAS3S_a033_vRegOutputOv m0 : 36|1@1+ (1,0) [0|1] ""  gtw
 SG_ EPAS3S_a092_espWrMia m1 : 35|1@1+ (1,0) [0|1] ""  gtw
 SG_ EPAS3S_a032_vRegOutputUv m0 : 35|1@1+ (1,0) [0|1] ""  gtw
 SG_ EPAS3S_a091_espWsCsError m1 : 34|1@1+ (1,0) [0|1] ""  gtw
 SG_ EPAS3S_a031_abnormalShutdown m0 : 34|1@1+ (1,0) [0|1] ""  gtw
 SG_ EPAS3S_a030_phaseWbootUv m0 : 33|1@1+ (1,0) [0|1] ""  gtw
 SG_ EPAS3S_a090_espWsCntError m1 : 33|1@1+ (1,0) [0|1] ""  gtw
 SG_ EPAS3S_a029_phaseVbootUv m0 : 32|1@1+ (1,0) [0|1] ""  gtw
 SG_ EPAS3S_a089_espWsMia m1 : 32|1@1+ (1,0) [0|1] ""  gtw
 SG_ EPAS3S_a028_phaseUbootUv m0 : 31|1@1+ (1,0) [0|1] ""  gtw
 SG_ EPAS3S_a088_dasCsError m1 : 31|1@1+ (1,0) [0|1] ""  gtw
 SG_ EPAS3S_a087_dasCntError m1 : 30|1@1+ (1,0) [0|1] ""  gtw
 SG_ EPAS3S_a027_phaseWlowOv m0 : 30|1@1+ (1,0) [0|1] ""  gtw
 SG_ EPAS3S_a086_dasMia m1 : 29|1@1+ (1,0) [0|1] ""  gtw
 SG_ EPAS3S_a026_phaseWhighOv m0 : 29|1@1+ (1,0) [0|1] ""  gtw
 SG_ EPAS3S_a025_phaseVlowOv m0 : 28|1@1+ (1,0) [0|1] ""  gtw
 SG_ EPAS3S_a085_canBusOff m1 : 28|1@1+ (1,0) [0|1] ""  gtw
 SG_ EPAS3S_a024_phaseVhighOv m0 : 27|1@1+ (1,0) [0|1] ""  gtw
 SG_ EPAS3S_a084_eacCancelled m1 : 27|1@1+ (1,0) [0|1] ""  gtw
 SG_ EPAS3S_a083_crcMismatch m1 : 26|1@1+ (1,0) [0|1] ""  gtw
 SG_ EPAS3S_a023_phaseUlowOv m0 : 26|1@1+ (1,0) [0|1] ""  gtw
 SG_ EPAS3S_a082_polarityCalError m1 : 25|1@1+ (1,0) [0|1] ""  gtw
 SG_ EPAS3S_a022_phaseUhighOv m0 : 25|1@1+ (1,0) [0|1] ""  gtw
 SG_ EPAS3S_a021_phaseWlowUv m0 : 24|1@1+ (1,0) [0|1] ""  gtw
 SG_ EPAS3S_a081_coggCompError m1 : 24|1@1+ (1,0) [0|1] ""  gtw
 SG_ EPAS3S_a080_ecuInitArbError m1 : 23|1@1+ (1,0) [0|1] ""  gtw
 SG_ EPAS3S_a020_phaseWhighUv m0 : 23|1@1+ (1,0) [0|1] ""  gtw
 SG_ EPAS3S_a079_backupCurrentPlaus m1 : 22|1@1+ (1,0) [0|1] ""  gtw
 SG_ EPAS3S_a019_phaseVlowUv m0 : 22|1@1+ (1,0) [0|1] ""  gtw
 SG_ EPAS3S_a078_phaseDisconnectError m1 : 21|1@1+ (1,0) [0|1] ""  gtw
 SG_ EPAS3S_a018_phaseVhighUv m0 : 21|1@1+ (1,0) [0|1] ""  gtw
 SG_ EPAS3S_a017_phaseUlowUv m0 : 20|1@1+ (1,0) [0|1] ""  gtw
 SG_ EPAS3S_a077_highSideFetError m1 : 20|1@1+ (1,0) [0|1] ""  gtw
 SG_ EPAS3S_a016_phaseUhighUv m0 : 19|1@1+ (1,0) [0|1] ""  gtw
 SG_ EPAS3S_a076_tempSensOutofRange m1 : 19|1@1+ (1,0) [0|1] ""  gtw
 SG_ EPAS3S_a015_gateDriveEeprom m0 : 18|1@1+ (1,0) [0|1] ""  gtw
 SG_ EPAS3S_a075_fspPwrCut m1 : 18|1@1+ (1,0) [0|1] ""  gtw
 SG_ EPAS3S_a074_overHeatProtect m1 : 17|1@1+ (1,0) [0|1] ""  gtw
 SG_ EPAS3S_a014_gateDriveTxError m0 : 17|1@1+ (1,0) [0|1] ""  gtw
 SG_ EPAS3S_a073_motParEstError m1 : 16|1@1+ (1,0) [0|1] ""  gtw
 SG_ EPAS3S_a013_gateDriveError m0 : 16|1@1+ (1,0) [0|1] ""  gtw
 SG_ EPAS3S_a012_currentSensCalError m0 : 15|1@1+ (1,0) [0|1] ""  gtw
 SG_ EPAS3S_a072_motFeedFwdError m1 : 15|1@1+ (1,0) [0|1] ""  gtw
 SG_ EPAS3S_a131_phaseFeedbackError m2 : 14|1@1+ (1,0) [0|1] ""  gtw
 SG_ EPAS3S_a071_vehSpdCorrError m1 : 14|1@1+ (1,0) [0|1] ""  gtw
 SG_ EPAS3S_a011_currentSensError m0 : 14|1@1+ (1,0) [0|1] ""  gtw
 SG_ EPAS3S_a070_hodCorrError m1 : 13|1@1+ (1,0) [0|1] ""  gtw
 SG_ EPAS3S_a130_sasOffsetNotCal m2 : 13|1@1+ (1,0) [0|1] ""  gtw
 SG_ EPAS3S_a010_trqSensCalError m0 : 13|1@1+ (1,0) [0|1] ""  gtw
 SG_ EPAS3S_a129_combEcu1StatFail m2 : 12|1@1+ (1,0) [0|1] ""  gtw
 SG_ EPAS3S_a069_eacCorrError m1 : 12|1@1+ (1,0) [0|1] ""  gtw
 SG_ EPAS3S_a009_sentDiff m0 : 12|1@1+ (1,0) [0|1] ""  gtw
 SG_ EPAS3S_a008_trqSens2Eeprom m0 : 11|1@1+ (1,0) [0|1] ""  gtw
 SG_ EPAS3S_a068_hystCorrError m1 : 11|1@1+ (1,0) [0|1] ""  gtw
 SG_ EPAS3S_a128_apsCsError m2 : 11|1@1+ (1,0) [0|1] ""  gtw
 SG_ EPAS3S_a067_yawDampCorrError m1 : 10|1@1+ (1,0) [0|1] ""  gtw
 SG_ EPAS3S_a007_trqSens2Supply m0 : 10|1@1+ (1,0) [0|1] ""  gtw
 SG_ EPAS3S_a127_apsCntError m2 : 10|1@1+ (1,0) [0|1] ""  gtw
 SG_ EPAS3S_a006_sent2Error m0 : 9|1@1+ (1,0) [0|1] ""  gtw
 SG_ EPAS3S_a066_returnCorrError m1 : 9|1@1+ (1,0) [0|1] ""  gtw
 SG_ EPAS3S_a126_apsMia m2 : 9|1@1+ (1,0) [0|1] ""  gtw
 SG_ EPAS3S_a065_trqTarCorrError m1 : 8|1@1+ (1,0) [0|1] ""  gtw
 SG_ EPAS3S_a005_sent2Mia m0 : 8|1@1+ (1,0) [0|1] ""  gtw
 SG_ EPAS3S_a125_trqSensTrimOutRange m2 : 8|1@1+ (1,0) [0|1] ""  gtw
 SG_ EPAS3S_a064_phaseCompCorrError m1 : 7|1@1+ (1,0) [0|1] ""  gtw
 SG_ EPAS3S_a124_tempSensStuckInRange m2 : 7|1@1+ (1,0) [0|1] ""  gtw
 SG_ EPAS3S_a004_trqSens1Eeprom m0 : 7|1@1+ (1,0) [0|1] ""  gtw
 SG_ EPAS3S_a003_trqSens1Supply m0 : 6|1@1+ (1,0) [0|1] ""  gtw
 SG_ EPAS3S_a063_dampCorrError m1 : 6|1@1+ (1,0) [0|1] ""  gtw
 SG_ EPAS3S_a123_combEcu2StatFail m2 : 6|1@1+ (1,0) [0|1] ""  gtw
 SG_ EPAS3S_a002_sent1Error m0 : 5|1@1+ (1,0) [0|1] ""  gtw
 SG_ EPAS3S_a062_assistCorrError m1 : 5|1@1+ (1,0) [0|1] ""  gtw
 SG_ EPAS3S_a122_olpActive m2 : 5|1@1+ (1,0) [0|1] ""  gtw
 SG_ EPAS3S_a001_sent1Mia m0 : 4|1@1+ (1,0) [0|1] ""  gtw
 SG_ EPAS3S_a061_bridgeUv m1 : 4|1@1+ (1,0) [0|1] ""  gtw
 SG_ EPAS3S_a121_pvtEcuStatCrcError m2 : 4|1@1+ (1,0) [0|1] ""  gtw
 SG_ EPAS3S_matrixIndex M : 0|4@1+ (1,0) [0|15] ""  gtw

BO_ 1856 TPMS_sensorIDs: 8 CH
 SG_ TPMS_sensorIDFL m0 : 32|32@1+ (1,0) [0|4294967295] ""  gtw
 SG_ TPMS_sensorIDRR m1 : 32|32@1+ (1,0) [0|4294967295] ""  gtw
 SG_ TPMS_sensorIDRL m3 : 32|32@1+ (1,0) [0|4294967295] ""  gtw
 SG_ TPMS_sensorIDFR m2 : 32|32@1+ (1,0) [0|4294967295] ""  gtw
 SG_ TPMS_sensorIDIndex M : 0|8@1+ (1,0) [0|3] ""  X

BO_ 771 OCS1P_status: 8 CH
 SG_ OCS1P_statusChecksum : 56|8@1+ (1,0) [0|255] ""  rcm
 SG_ OCS1P_statusCounter : 52|4@1+ (1,0) [0|15] ""  rcm
 SG_ OCS1P_classificationHoldState : 33|2@1+ (1,0) [0|3] ""  gtw
 SG_ OCS1P_classificationExtHold : 32|1@1+ (1,0) [0|1] ""  gtw
 SG_ OCS1P_occupantClassificationSelf : 24|8@1+ (1,0) [0|255] ""  gtw
 SG_ OCS1P_occupantClassificationRaw : 16|8@1+ (1,0) [0|255] ""  gtw
 SG_ OCS1P_classificationHeld : 15|1@1+ (1,0) [0|1] ""  gtw
 SG_ OCS1P_seatbackStable : 14|1@1+ (1,0) [0|1] ""  gtw
 SG_ OCS1P_cushionStable : 13|1@1+ (1,0) [0|1] ""  gtw
 SG_ OCS1P_sandwichStable : 12|1@1+ (1,0) [0|1] ""  gtw
 SG_ OCS1P_occupiedState : 9|2@1+ (1,0) [0|3] ""  gtw
 SG_ OCS1P_occupantClassificationQF : 8|1@1+ (1,0) [0|1] ""  app
 SG_ OCS1P_occupantClassification : 0|8@1+ (1,0) [0|255] ""  gtw

BO_ 876 APS_warningMatrix1: 8 CH
 SG_ APS_w106_torsionBarOffset : 41|1@1+ (1,0) [0|1] ""  gtw
 SG_ APS_w105_DEPRECATED : 40|1@1+ (1,0) [0|1] ""  gtw
 SG_ APS_w104_DEPRECATED : 39|1@1+ (1,0) [0|1] ""  gtw
 SG_ APS_w103_robExperimentalAEB : 38|1@1+ (1,0) [0|1] ""  gtw
 SG_ APS_w102_DEPRECATED : 37|1@1+ (1,0) [0|1] ""  gtw
 SG_ APS_w101_DEPRECATED : 36|1@1+ (1,0) [0|1] ""  gtw
 SG_ APS_w100_DEPRECATED : 35|1@1+ (1,0) [0|1] ""  gtw
 SG_ APS_w099_DEPRECATED : 34|1@1+ (1,0) [0|1] ""  gtw
 SG_ APS_w098_DEPRECATED : 33|1@1+ (1,0) [0|1] ""  gtw
 SG_ APS_w097_DEPRECATED : 32|1@1+ (1,0) [0|1] ""  gtw
 SG_ APS_w096_DEPRECATED : 31|1@1+ (1,0) [0|1] ""  gtw
 SG_ APS_w095_DEPRECATED : 30|1@1+ (1,0) [0|1] ""  gtw
 SG_ APS_w094_DEPRECATED : 29|1@1+ (1,0) [0|1] ""  gtw
 SG_ APS_w093_DEPRECATED : 28|1@1+ (1,0) [0|1] ""  gtw
 SG_ APS_w092_DEPRECATED : 27|1@1+ (1,0) [0|1] ""  gtw
 SG_ APS_w091_DEPRECATED : 26|1@1+ (1,0) [0|1] ""  gtw
 SG_ APS_w090_DEPRECATED : 25|1@1+ (1,0) [0|1] ""  gtw
 SG_ APS_w089_DEPRECATED : 24|1@1+ (1,0) [0|1] ""  gtw
 SG_ APS_w088_DEPRECATED : 23|1@1+ (1,0) [0|1] ""  gtw
 SG_ APS_w087_DEPRECATED : 22|1@1+ (1,0) [0|1] ""  gtw
 SG_ APS_w086_robCollision : 21|1@1+ (1,0) [0|1] ""  gtw
 SG_ APS_w085_pmmSteering : 20|1@1+ (1,0) [0|1] ""  gtw
 SG_ APS_w084_pmmIPSO : 19|1@1+ (1,0) [0|1] ""  gtw
 SG_ APS_w083_inPathRADObject : 18|1@1+ (1,0) [0|1] ""  gtw
 SG_ APS_w082_inPathFSviolation : 17|1@1+ (1,0) [0|1] ""  gtw
 SG_ APS_w081_pmmActiveBraking : 16|1@1+ (1,0) [0|1] ""  gtw
 SG_ APS_w080_accFailedActivation : 15|1@1+ (1,0) [0|1] ""  gtw
 SG_ APS_w079_edrAvailable : 14|1@1+ (1,0) [0|1] ""  gtw
 SG_ APS_w078_pmmActive2 : 13|1@1+ (1,0) [0|1] ""  gtw
 SG_ APS_w077_pmmActive : 12|1@1+ (1,0) [0|1] ""  gtw
 SG_ APS_w076_mobilEyeSetC : 11|1@1+ (1,0) [0|1] ""  gtw
 SG_ APS_w075_scMia : 10|1@1+ (1,0) [0|1] ""  gtw
 SG_ APS_w074_inPathStationaryObst : 9|1@1+ (1,0) [0|1] ""  gtw
 SG_ APS_w073_issueEscalatedLDW : 8|1@1+ (1,0) [0|1] ""  gtw
 SG_ APS_w072_selfparkComplete : 7|1@1+ (1,0) [0|1] ""  gtw
 SG_ APS_w071_selfparkStarted : 6|1@1+ (1,0) [0|1] ""  gtw
 SG_ APS_w070_apcIncompleteCal : 5|1@1+ (1,0) [0|1] ""  gtw
 SG_ APS_w069_apcSpaceMasked : 4|1@1+ (1,0) [0|1] ""  gtw
 SG_ APS_w068_vlInconsistency : 3|1@1+ (1,0) [0|1] ""  gtw
 SG_ APS_w067_steeringAlignment : 2|1@1+ (1,0) [0|1] ""  gtw
 SG_ APS_w066_deserializerLockLost : 1|1@1+ (1,0) [0|1] ""  gtw
 SG_ APS_w065_deserializerOvercurrent : 0|1@1+ (1,0) [0|1] ""  gtw

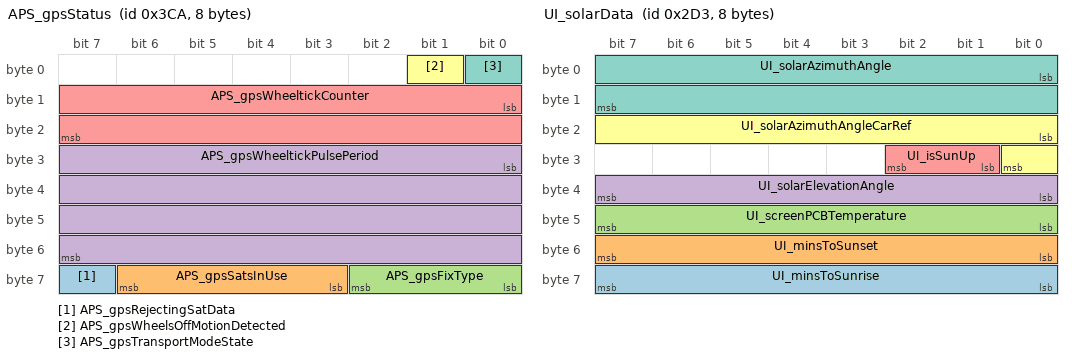
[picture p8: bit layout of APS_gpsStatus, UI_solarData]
BO_ 970 APS_gpsStatus: 8 CH
 SG_ APS_gpsRejectingSatData : 63|1@1+ (1,0) [0|1] ""  gtw
 SG_ APS_gpsSatsInUse : 59|4@1+ (1,0) [0|15] ""  gtw
 SG_ APS_gpsFixType : 56|3@1+ (1,0) [0|7] ""  gtw
 SG_ APS_gpsWheeltickPulsePeriod : 24|32@1+ (1,0) [0|4294967295] ""  X
 SG_ APS_gpsWheeltickCounter : 8|16@1+ (1,0) [0|65535] ""  X
 SG_ APS_gpsWheelsOffMotionDetected : 1|1@1+ (1,0) [0|1] ""  gtw
 SG_ APS_gpsTransportModeState : 0|1@1+ (1,0) [0|1] ""  gtw

BO_ 325 ESP_status: 8 CH
 SG_ ESP_brakeTorqueTarget : 51|13@1+ (2,0) [0|16382] "Nm"  X
 SG_ ESP_ebrStatus : 49|2@1+ (1,0) [0|3] ""  gtw
 SG_ ESP_ebrStandstillSkid : 48|1@1+ (1,0) [0|1] ""  gtw
 SG_ ESP_btcTargetState : 38|2@1+ (1,0) [0|3] ""  gtw
 SG_ ESP_ptcTargetState : 36|2@1+ (1,0) [0|3] ""  gtw
 SG_ ESP_cdpStatus : 34|2@1+ (1,0) [0|3] ""  gtw
 SG_ ESP_brakeApply : 31|1@1+ (1,0) [0|1] ""  X
 SG_ ESP_driverBrakeApply : 29|2@1+ (1,0) [0|3] ""  das
 SG_ ESP_brakeDiscWipingActive : 28|1@1+ (1,0) [0|1] ""  gtw
 SG_ ESP_steeringAngleQF : 27|1@1+ (1,0) [0|1] ""  X
 SG_ ESP_yawRateQF : 26|1@1+ (1,0) [0|1] ""  das
 SG_ ESP_lateralAccelQF : 25|1@1+ (1,0) [0|1] ""  aps
 SG_ ESP_longitudinalAccelQF : 24|1@1+ (1,0) [0|1] ""  aps
 SG_ ESP_absBrakeEvent2 : 22|2@1+ (1,0) [0|3] ""  aps
 SG_ ESP_brakeLamp : 21|1@1+ (1,0) [0|1] ""  X
 SG_ ESP_espLampFlash : 20|1@1+ (1,0) [0|1] ""  gtw
 SG_ ESP_hydraulicBoostEnabled : 19|1@1+ (1,0) [0|1] ""  gtw
 SG_ ESP_espFaultLamp : 18|1@1+ (1,0) [0|1] ""  gtw
 SG_ ESP_absFaultLamp : 17|1@1+ (1,0) [0|1] ""  gtw
 SG_ ESP_ebdFaultLamp : 16|1@1+ (1,0) [0|1] ""  gtw
 SG_ ESP_stabilityControlSts2 : 14|2@1+ (1,0) [0|3] ""  das
 SG_ ESP_espModeActive : 12|2@1+ (1,0) [0|3] ""  X
 SG_ ESP_statusCounter : 8|4@1+ (1,0) [0|15] ""  X
 SG_ ESP_statusChecksum : 0|8@1+ (1,0) [0|255] ""  X

BO_ 1329 RADC_info: 8 CH
 SG_ RADC_infoSubUsageID m11 : 48|16@1+ (1,0) [0|65535] ""  gtw
 SG_ RADC_infoComponentID m10 : 48|16@1+ (1,0) [0|65535] ""  gtw
 SG_ RADC_infoHardwareRevision m19 : 40|8@1+ (1,0) [0|255] ""  gtw
 SG_ RADC_infoApplicationCRC m13 : 32|32@1+ (1,0) [0|4294967295] ""  gtw
 SG_ RADC_infoUsageID m11 : 32|16@1+ (1,0) [0|65535] ""  gtw
 SG_ RADC_infoMaturity m19 : 32|8@1+ (1,0) [0|255] ""  gtw
 SG_ RADC_infoHardwareID m10 : 32|16@1+ (1,0) [0|65535] ""  gtw
 SG_ RADC_infoBootloaderCRC m20 : 32|32@1+ (1,0) [0|4294967295] ""  gtw
 SG_ RADC_infoBranchOrigin m19 : 24|8@1+ (1,0) [0|255] ""  gtw
 SG_ RADC_infoAssemblyID m11 : 24|8@1+ (1,0) [0|255] ""  gtw
 SG_ RADC_infoPcbaID m11 : 16|8@1+ (1,0) [0|255] ""  gtw
 SG_ RADC_infoBuildConfigID m10 : 16|16@1+ (1,0) [0|65535] ""  gtw
 SG_ RADC_infoMajorVersion m19 : 16|8@1+ (1,0) [0|255] ""  gtw
 SG_ RADC_infoBuildType m10 : 8|8@1+ (1,0) [0|4] ""  gtw
 SG_ RADC_infoPlatformType m19 : 8|8@1+ (1,0) [0|255] ""  gtw
 SG_ RADC_infoBootUdsProtoVersion m20 : 8|8@1+ (1,0) [0|255] ""  gtw
 SG_ RADC_infoIndex M : 0|8@1+ (1,0) [10|20] ""  X

BO_ 810 DAS_warningMatrix0: 8 CH
 SG_ DAS_w064_epasMia : 63|1@1+ (1,0) [0|1] ""  gtw
 SG_ DAS_w063_parkVersionMismatch : 62|1@1+ (1,0) [0|1] ""  gtw
 SG_ DAS_w062_radcAlignment : 61|1@1+ (1,0) [0|1] ""  gtw
 SG_ DAS_w061_airSuspensionMia : 60|1@1+ (1,0) [0|1] ""  gtw
 SG_ DAS_w060_fcw_event : 59|1@1+ (1,0) [0|1] ""  gtw
 SG_ DAS_w059_parkMia : 58|1@1+ (1,0) [0|1] ""  gtw
 SG_ DAS_w058_epbMia : 57|1@1+ (1,0) [0|1] ""  gtw
 SG_ DAS_w057_mcuMia : 56|1@1+ (1,0) [0|1] ""  gtw
 SG_ DAS_w056_diMia : 55|1@1+ (1,0) [0|1] ""  gtw
 SG_ DAS_w055_radcVersionMismatch : 54|1@1+ (1,0) [0|1] ""  gtw
 SG_ DAS_w054_camAutofix : 53|1@1+ (1,0) [0|1] ""  gtw
 SG_ DAS_w053_radcCommIssue : 52|1@1+ (1,0) [0|1] ""  gtw
 SG_ DAS_w052_radcSensorIssue : 51|1@1+ (1,0) [0|1] ""  gtw
 SG_ DAS_w051_radcEcuIssue : 50|1@1+ (1,0) [0|1] ""  gtw
 SG_ DAS_w050_aeb_event : 49|1@1+ (1,0) [0|1] ""  gtw
 SG_ DAS_w049_eyeqVersionMismatch : 48|1@1+ (1,0) [0|1] ""  gtw
 SG_ DAS_w048_DAS_Features_Disabled : 47|1@1+ (1,0) [0|1] ""  gtw
 SG_ DAS_w047_edrEvent : 46|1@1+ (1,0) [0|1] ""  gtw
 SG_ DAS_w046_eepromRecordAbsent : 45|1@1+ (1,0) [0|1] ""  gtw
 SG_ DAS_w045_radMia : 44|1@1+ (1,0) [0|1] ""  gtw
 SG_ DAS_w044_appMobileyeFailure : 43|1@1+ (1,0) [0|1] ""  gtw
 SG_ DAS_w043_camLongRunTime : 42|1@1+ (1,0) [0|1] ""  gtw
 SG_ DAS_w042_autopilotAborting : 41|1@1+ (1,0) [0|1] ""  gtw
 SG_ DAS_w041_autopilotRateSaturated : 40|1@1+ (1,0) [0|1] ""  gtw
 SG_ DAS_w040_autopilotAngleSaturated : 39|1@1+ (1,0) [0|1] ""  gtw
 SG_ DAS_w039_sdm_rcm_Mia : 38|1@1+ (1,0) [0|1] ""  gtw
 SG_ DAS_w038_camFailure : 37|1@1+ (1,0) [0|1] ""  gtw
 SG_ DAS_w037_camTacIssue : 36|1@1+ (1,0) [0|1] ""  gtw
 SG_ DAS_w036_bdyMia : 35|1@1+ (1,0) [0|1] ""  gtw
 SG_ DAS_w035_espMia : 34|1@1+ (1,0) [0|1] ""  gtw
 SG_ DAS_w034_sccmMia : 33|1@1+ (1,0) [0|1] ""  gtw
 SG_ DAS_w033_gtwMia : 32|1@1+ (1,0) [0|1] ""  gtw
 SG_ DAS_w032_canTxError : 31|1@1+ (1,0) [0|1] ""  gtw
 SG_ DAS_w031_canRxError : 30|1@1+ (1,0) [0|1] ""  gtw
 SG_ DAS_w030_Heater_Issue : 29|1@1+ (1,0) [0|1] ""  gtw
 SG_ DAS_w029_spi_tx_error : 28|1@1+ (1,0) [0|1] ""  gtw
 SG_ DAS_w028_spi_rx_error : 27|1@1+ (1,0) [0|1] ""  gtw
 SG_ DAS_w027_ECU_Reset_Fault : 26|1@1+ (1,0) [0|1] ""  gtw
 SG_ DAS_w026_ECU_timingIssue : 25|1@1+ (1,0) [0|1] ""  gtw
 SG_ DAS_w025_LC_Steering_Override : 24|1@1+ (1,0) [0|1] ""  gtw
 SG_ DAS_w024_ECU_Watchdog_Reset : 23|1@1+ (1,0) [0|1] ""  gtw
 SG_ DAS_w023_ECU_Cam_Statemismatc : 22|1@1+ (1,0) [0|1] ""  gtw
 SG_ DAS_w022_ECU_EEPROM_Failure : 21|1@1+ (1,0) [0|1] ""  gtw
 SG_ DAS_w021_ECU_Temperature_Issue : 20|1@1+ (1,0) [0|1] ""  gtw
 SG_ DAS_w020_ECU_checkstopError : 19|1@1+ (1,0) [0|1] ""  gtw
 SG_ DAS_w019_ECU_Stack_Overflow : 18|1@1+ (1,0) [0|1] ""  gtw
 SG_ DAS_w018_ECU_Power_Issue : 17|1@1+ (1,0) [0|1] ""  gtw
 SG_ DAS_w017_Cam_Msg_MIA : 16|1@1+ (1,0) [0|1] ""  gtw
 SG_ DAS_w016_aeb_e_event : 15|1@1+ (1,0) [0|1] ""  gtw
 SG_ DAS_w015_Camera_Failsafes : 14|1@1+ (1,0) [0|1] ""  gtw
 SG_ DAS_w014_swAssert : 13|1@1+ (1,0) [0|1] ""  gtw
 SG_ DAS_w013_Cam_Watchdog : 12|1@1+ (1,0) [0|1] ""  gtw
 SG_ DAS_w012_Cam_BootFailure : 11|1@1+ (1,0) [0|1] ""  gtw
 SG_ DAS_w011_scaEvent : 10|1@1+ (1,0) [0|1] ""  gtw
 SG_ DAS_w010_radcCalibIssue : 9|1@1+ (1,0) [0|1] ""  gtw
 SG_ DAS_w009_aebFault : 8|1@1+ (1,0) [0|1] ""  gtw
 SG_ DAS_w008_parkDisabled : 7|1@1+ (1,0) [0|1] ""  gtw
 SG_ DAS_w007_ahlbDisabled : 6|1@1+ (1,0) [0|1] ""  gtw
 SG_ DAS_w006_aebCancelled : 5|1@1+ (1,0) [0|1] ""  gtw
 SG_ DAS_w005_fcwCancelled : 4|1@1+ (1,0) [0|1] ""  gtw
 SG_ DAS_w004_accDisabled : 3|1@1+ (1,0) [0|1] ""  gtw
 SG_ DAS_w003_isaDisabled : 2|1@1+ (1,0) [0|1] ""  gtw
 SG_ DAS_w002_ldwDisabled : 1|1@1+ (1,0) [0|1] ""  gtw

BO_ 1621 ESP_udsResponse: 8 CH
 SG_ ESP_udsResponseData : 7|64@0+ (1,0) [0|18446744073709551615] ""  gtw

BO_ 723 UI_solarData: 8 CH
 SG_ UI_minsToSunrise : 56|8@1+ (10,0) [0|2550] "min"  X
 SG_ UI_minsToSunset : 48|8@1+ (10,0) [0|2550] "min"  X
 SG_ UI_screenPCBTemperature : 40|8@1- (0.5,40.0) [-20|100] "degC"  X
 SG_ UI_solarElevationAngle : 32|8@1- (1,0) [-128|126] "degrees"  das
 SG_ UI_isSunUp : 25|2@1+ (1,0) [0|3] ""  X
 SG_ UI_solarAzimuthAngleCarRef : 16|9@1- (1,0) [-256|254] "degrees"  das
 SG_ UI_solarAzimuthAngle : 0|16@1- (1,0) [-32767|32767] "degrees"  das

BO_ 1584 UDS_epas3pRequest: 8 CH
 SG_ UDS_epas3pRequestData : 7|64@0+ (1,0) [0|18446744073709551615] ""  das

BO_ 1353 APP_info: 8 CH
 SG_ APP_infoAppApGitHashBytes m2 : 8|56@1+ (1,0) [0|72057594037927935] ""  aps
 SG_ APP_infoAppFwGitHashBytes m1 : 8|56@1+ (1,0) [0|72057594037927935] ""  aps
 SG_ APP_buildType m0 : 8|8@1+ (1,0) [0|3] ""  aps
 SG_ APP_infoIndex M : 0|8@1+ (1,0) [0|2] ""  aps

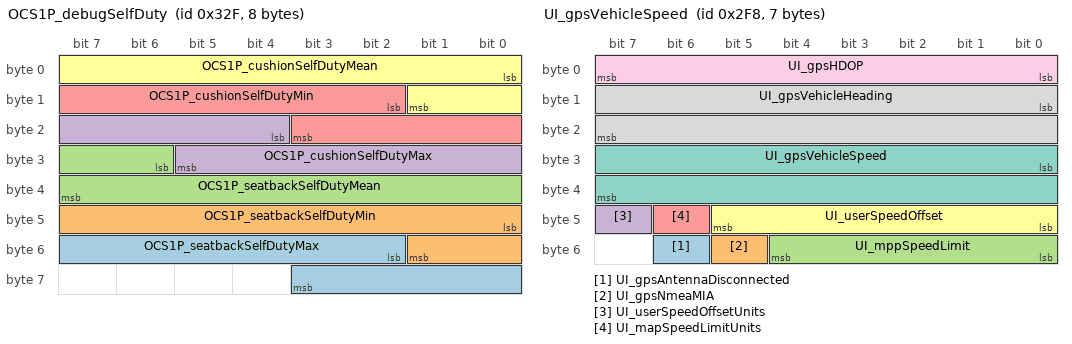
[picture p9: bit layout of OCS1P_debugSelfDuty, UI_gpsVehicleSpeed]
BO_ 815 OCS1P_debugSelfDuty: 8 CH
 SG_ OCS1P_seatbackSelfDutyMax : 50|10@1+ (0.09775171065493646,0) [0|100] "%"  gtw
 SG_ OCS1P_seatbackSelfDutyMin : 40|10@1+ (0.09775171065493646,0) [0|100] "%"  gtw
 SG_ OCS1P_seatbackSelfDutyMean : 30|10@1+ (0.09775171065493646,0) [0|100] "%"  gtw
 SG_ OCS1P_cushionSelfDutyMax : 20|10@1+ (0.09775171065493646,0) [0|100] "%"  gtw
 SG_ OCS1P_cushionSelfDutyMin : 10|10@1+ (0.09775171065493646,0) [0|100] "%"  gtw
 SG_ OCS1P_cushionSelfDutyMean : 0|10@1+ (0.09775171065493646,0) [0|100] "%"  gtw

BO_ 760 UI_gpsVehicleSpeed: 7 CH
 SG_ UI_gpsAntennaDisconnected : 54|1@1+ (1,0) [0|1] ""  das
 SG_ UI_gpsNmeaMIA : 53|1@1+ (1,0) [0|1] ""  X
 SG_ UI_mppSpeedLimit : 48|5@1+ (5,0) [0|155] "kph/mph"  das
 SG_ UI_userSpeedOffsetUnits : 47|1@1+ (1,0) [0|1] ""  das
 SG_ UI_mapSpeedLimitUnits : 46|1@1+ (1,0) [0|1] ""  das
 SG_ UI_userSpeedOffset : 40|6@1+ (1,-30) [-30|33] "kph/mph"  das
 SG_ UI_gpsVehicleSpeed : 24|16@1+ (0.00390625,0) [0|250.996] "km/hr"  X
 SG_ UI_gpsVehicleHeading : 8|16@1+ (0.0078125,0) [0|511.9921875] "deg"  das
 SG_ UI_gpsHDOP : 0|8@1+ (0.1,0) [0|25.5] "1"  das

BO_ 1625 DAS_udsResponse: 8 CH
 SG_ DAS_udsResponseData : 7|64@0+ (1,0) [0|18446744073709551615] ""  gtw

BO_ 1619 OCS1P_udsResponse: 8 CH
 SG_ OCS1P_udsResponseData : 0|64@1+ (1,0) [0|18446744073709551615] ""  gtw

BO_ 259 VCRIGHT_doorStatus: 8 CH
 SG_ VCRIGHT_mirrorDipped : 63|1@1+ (1,0) [0|1] ""  X
 SG_ VCRIGHT_mirrorRecallState : 60|3@1+ (1,0) [0|5] ""  X
 SG_ VCRIGHT_trunkLatchStatus : 56|4@1+ (1,0) [0|8] ""  X
 SG_ VCRIGHT_mirrorFoldState : 52|3@1+ (1,0) [0|4] ""  X
 SG_ VCRIGHT_mirrorState : 49|3@1+ (1,0) [0|4] ""  X
 SG_ VCRIGHT_mirrorTiltYPosition : 41|8@1+ (0.02,0) [0|5] "V"  X
 SG_ VCRIGHT_mirrorTiltXPosition : 33|8@1+ (0.02,0) [0|5] "V"  X
 SG_ VCRIGHT_rearIntSwitchPressed : 32|1@1+ (1,0) [0|1] ""  X
 SG_ VCRIGHT_frontIntSwitchPressed : 31|1@1+ (1,0) [0|1] ""  X
 SG_ VCRIGHT_frontHandlePulledPersist : 30|1@1+ (1,0) [0|1] ""  X
 SG_ VCRIGHT_reservedForBackCompat : 28|2@1+ (1,0) [0|3] ""  X
 SG_ VCRIGHT_rearHandlePWM : 21|7@1+ (1,0) [0|100] "%"  X
 SG_ VCRIGHT_frontHandlePWM : 14|7@1+ (1,0) [0|100] "%"  X
 SG_ VCRIGHT_rearRelActuatorSwitch : 13|1@1+ (1,0) [0|1] ""  X
 SG_ VCRIGHT_frontRelActuatorSwitch : 12|1@1+ (1,0) [0|1] ""  X
 SG_ VCRIGHT_rearHandlePulled : 11|1@1+ (1,0) [0|1] ""  das
 SG_ VCRIGHT_frontHandlePulled : 10|1@1+ (1,0) [0|1] ""  das
 SG_ VCRIGHT_rearLatchSwitch : 9|1@1+ (1,0) [0|1] ""  X
 SG_ VCRIGHT_frontLatchSwitch : 8|1@1+ (1,0) [0|1] ""  X
 SG_ VCRIGHT_rearLatchStatus : 4|4@1+ (1,0) [0|8] ""  X
 SG_ VCRIGHT_frontLatchStatus : 0|4@1+ (1,0) [0|8] ""  ocs1p

BO_ 1613 UDS_ibstRequest: 8 CH
 SG_ UDS_ibstRequestData : 7|64@0+ (1,0) [0|18446744073709551615] ""  ibst

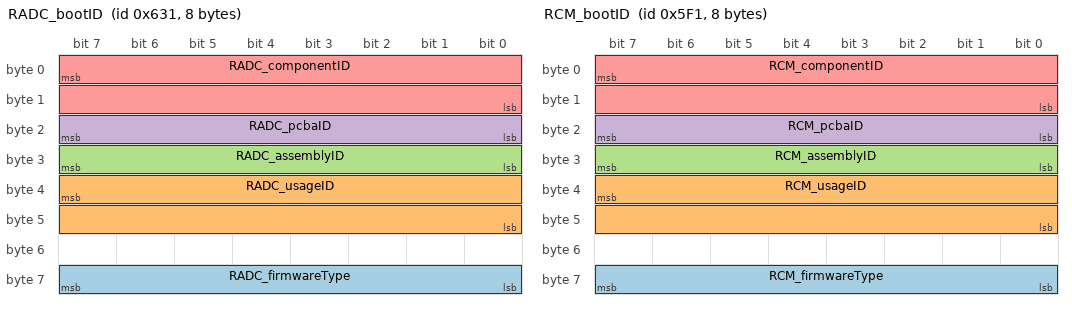
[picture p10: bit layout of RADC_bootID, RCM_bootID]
BO_ 1585 RADC_bootID: 8 CH
 SG_ RADC_firmwareType : 63|8@0+ (1,0) [0|255] ""  gtwu
 SG_ RADC_usageID : 39|16@0+ (1,0) [0|65535] ""  gtwu
 SG_ RADC_assemblyID : 31|8@0+ (1,0) [0|255] ""  gtwu
 SG_ RADC_pcbaID : 23|8@0+ (1,0) [0|255] ""  gtwu
 SG_ RADC_componentID : 7|16@0+ (1,0) [0|65535] ""  gtwu

BO_ 1627 TAS_udsResponse: 8 CH
 SG_ TAS_udsResponseData : 7|64@0+ (1,0) [0|18446744073709551615] ""  gtw

BO_ 551 OCS1P_debugCushionMutCNT: 8 CH
 SG_ OCS1P_cushionMutCNTDuty : 32|32@1+ (1,0) [0|4294967295] ""  X
 SG_ OCS1P_cushionMutCNTFreq : 0|32@1+ (1,0) [0|4294967295] ""  dbg

BO_ 2044 dynamicMessage1_0: 7 CH
 SG_ APP_infoAppGitHashBytes : 0|56@1+ (1,0) [0|72057594037927935] ""  ui

BO_ 1601 UDS_rcmRequest: 8 CH
 SG_ UDS_rcmRequestData : 7|64@0+ (1,0) [0|18446744073709551615] ""  rcm

BO_ 296 GTW_driveState: 1 CH
 SG_ REV_GEAR : 0|2@1+ (1,0) [0|3] ""  X

BO_ 1521 RCM_bootID: 8 CH
 SG_ RCM_firmwareType : 63|8@0+ (1,0) [0|255] ""  gtwu
 SG_ RCM_usageID : 39|16@0+ (1,0) [0|65535] ""  gtwu
 SG_ RCM_assemblyID : 31|8@0+ (1,0) [0|255] ""  gtwu
 SG_ RCM_pcbaID : 23|8@0+ (1,0) [0|255] ""  gtwu
 SG_ RCM_componentID : 7|16@0+ (1,0) [0|65535] ""  gtwu

BO_ 1368 GTW_gitHash: 8 CH
 SG_ GTW_appGitHash : 7|64@0+ (1,0) [0|18446744073709551615] "1"  X

BO_ 1519 TPMS_info: 8 CH
 SG_ TPMS_infoComponentID m10 : 48|16@1+ (1,0) [0|65535] ""  gtw
 SG_ TPMS_infoBootloaderCRC m20 : 32|32@1+ (1,0) [0|4294967295] ""  gtw
 SG_ TPMS_infoApplicationCRC m13 : 32|32@1+ (1,0) [0|4294967295] ""  gtw
 SG_ TPMS_infoUsageID m11 : 32|16@1+ (1,0) [0|65535] ""  gtw
 SG_ TPMS_infoAssemblyID m11 : 24|8@1+ (1,0) [0|255] ""  gtw
 SG_ TPMS_infoPcbaID m11 : 16|8@1+ (1,0) [0|255] ""  gtw
 SG_ TPMS_infoBootUdsProtoVersion m20 : 8|8@1+ (1,0) [0|255] ""  gtw
 SG_ TPMS_infoIndex M : 0|8@1+ (1,0) [0|255] ""  gtw

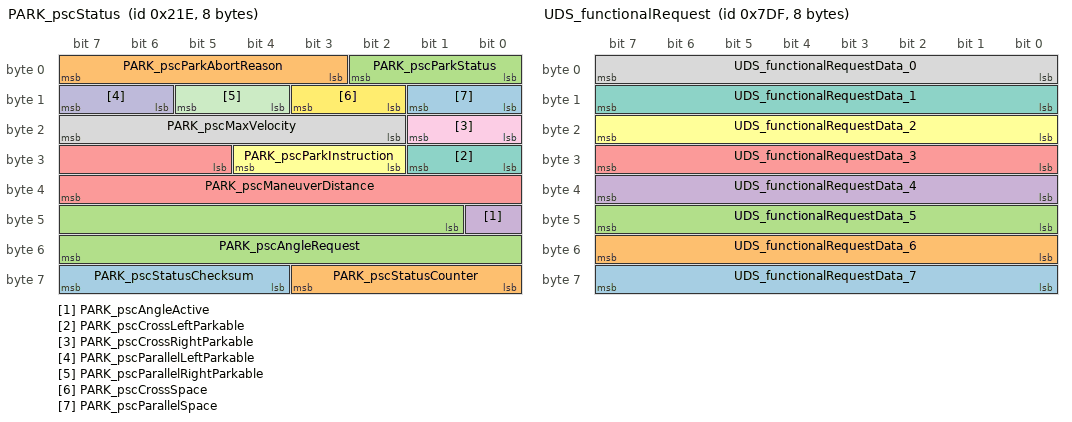
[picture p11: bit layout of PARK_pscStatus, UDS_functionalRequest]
BO_ 542 PARK_pscStatus: 8 CH
 SG_ PARK_pscStatusChecksum : 60|4@1+ (1,0) [0|15] ""  X
 SG_ PARK_pscStatusCounter : 56|4@1+ (1,0) [0|15] ""  X
 SG_ PARK_pscAngleRequest : 41|15@1+ (0.1,-1638.4) [-1638.4|1638.4] "deg"  das
 SG_ PARK_pscAngleActive : 40|1@1+ (1,0) [0|1] ""  das
 SG_ PARK_pscManeuverDistance : 29|11@1+ (1,0) [0|2047] "cm"  das
 SG_ PARK_pscParkInstruction : 26|3@1+ (1,0) [0|7] ""  das
 SG_ PARK_pscCrossLeftParkable : 24|2@1+ (1,0) [0|3] ""  das
 SG_ PARK_pscMaxVelocity : 18|6@1+ (0.1,0) [0|6.4] "kph"  das
 SG_ PARK_pscCrossRightParkable : 16|2@1+ (1,0) [0|3] ""  das
 SG_ PARK_pscParallelLeftParkable : 14|2@1+ (1,0) [0|3] ""  das
 SG_ PARK_pscParallelRightParkable : 12|2@1+ (1,0) [0|3] ""  das
 SG_ PARK_pscCrossSpace : 10|2@1+ (1,0) [0|3] ""  das
 SG_ PARK_pscParallelSpace : 8|2@1+ (1,0) [0|3] ""  das
 SG_ PARK_pscParkAbortReason : 3|5@1+ (1,0) [0|31] ""  das
 SG_ PARK_pscParkStatus : 0|3@1+ (1,0) [0|7] ""  das

BO_ 2031 DBG_testMessage: 2 CH
 SG_ DBG_testID : 0|16@1+ (1,0) [0|65535] ""  X

BO_ 1840 UDS_epas3sRequest: 8 CH
 SG_ UDS_epas3sRequestData : 7|64@0+ (1,0) [0|18446744073709551615] ""  epas3s

BO_ 2015 UDS_functionalRequest: 8 CH
 SG_ UDS_functionalRequestData_7 : 63|8@0+ (1,0) [0|255] ""  das
 SG_ UDS_functionalRequestData_6 : 55|8@0+ (1,0) [0|255] ""  das
 SG_ UDS_functionalRequestData_5 : 47|8@0+ (1,0) [0|255] ""  das
 SG_ UDS_functionalRequestData_4 : 39|8@0+ (1,0) [0|255] ""  das
 SG_ UDS_functionalRequestData_3 : 31|8@0+ (1,0) [0|255] ""  das
 SG_ UDS_functionalRequestData_2 : 23|8@0+ (1,0) [0|255] ""  das
 SG_ UDS_functionalRequestData_1 : 15|8@0+ (1,0) [0|255] ""  das
 SG_ UDS_functionalRequestData_0 : 7|8@0+ (1,0) [0|255] ""  das

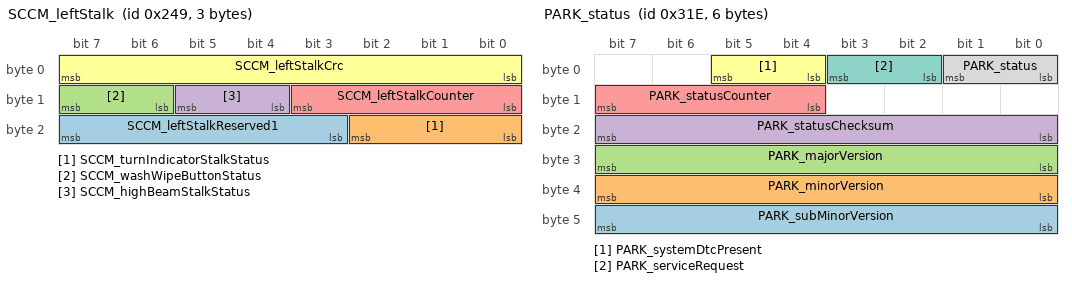
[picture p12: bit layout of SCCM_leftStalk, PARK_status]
BO_ 585 SCCM_leftStalk: 3 CH
 SG_ SCCM_leftStalkReserved1 : 19|5@1+ (1,0) [0|31] ""  X
 SG_ SCCM_turnIndicatorStalkStatus : 16|3@1+ (1,0) [0|5] ""  park
 SG_ SCCM_washWipeButtonStatus : 14|2@1+ (1,0) [0|3] ""  X
 SG_ SCCM_highBeamStalkStatus : 12|2@1+ (1,0) [0|3] ""  X
 SG_ SCCM_leftStalkCounter : 8|4@1+ (1,0) [0|15] ""  X
 SG_ SCCM_leftStalkCrc : 0|8@1+ (1,0) [0|255] ""  X

BO_ 798 PARK_status: 6 CH
 SG_ PARK_subMinorVersion : 40|8@1+ (1,0) [0|255] ""  das
 SG_ PARK_minorVersion : 32|8@1+ (1,0) [0|255] ""  das
 SG_ PARK_majorVersion : 24|8@1+ (1,0) [0|255] ""  das
 SG_ PARK_statusChecksum : 16|8@1+ (1,0) [0|255] ""  gtw
 SG_ PARK_statusCounter : 12|4@1+ (1,0) [0|15] ""  X
 SG_ PARK_systemDtcPresent : 4|2@1+ (1,0) [0|3] ""  das
 SG_ PARK_serviceRequest : 2|2@1+ (1,0) [0|3] ""  das
 SG_ PARK_status : 0|2@1+ (1,0) [0|3] ""  das

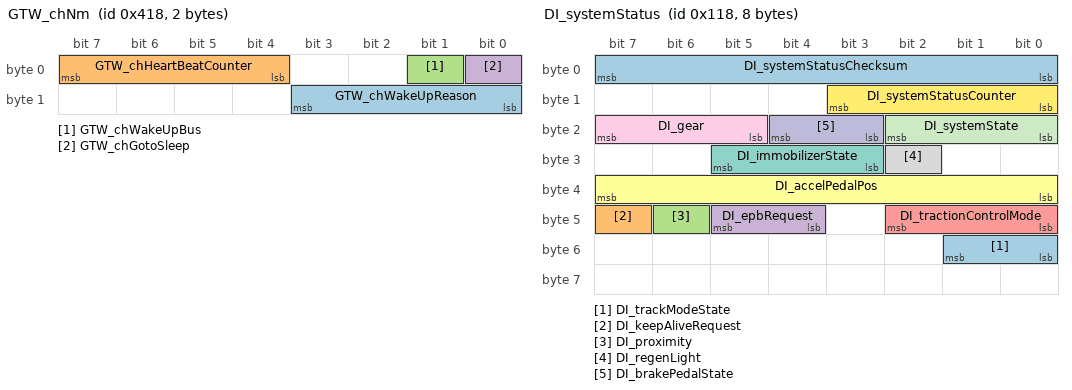
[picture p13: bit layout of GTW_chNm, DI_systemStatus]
BO_ 1048 GTW_chNm: 2 CH
 SG_ GTW_chWakeUpReason : 8|4@1+ (1,0) [0|8] ""  X
 SG_ GTW_chHeartBeatCounter : 4|4@1+ (1,0) [0|15] ""  park
 SG_ GTW_chWakeUpBus : 1|1@1+ (1,0) [0|1] ""  X
 SG_ GTW_chGotoSleep : 0|1@1+ (1,0) [0|1] ""  das

BO_ 280 DI_systemStatus: 8 CH
 SG_ DI_trackModeState : 48|2@1+ (1,0) [0|2] ""  X
 SG_ DI_keepAliveRequest : 47|1@1+ (1,0) [0|1] ""  X
 SG_ DI_proximity : 46|1@1+ (1,0) [0|1] ""  X
 SG_ DI_epbRequest : 44|2@1+ (1,0) [0|2] ""  X
 SG_ DI_tractionControlMode : 40|3@1+ (1,0) [0|5] ""  X
 SG_ DI_accelPedalPos : 32|8@1+ (0.4,0) [0|100] "%"  X
 SG_ DI_immobilizerState : 27|3@1+ (1,0) [0|6] ""  X
 SG_ DI_regenLight : 26|1@1+ (1,0) [0|1] ""  X
 SG_ DI_gear : 21|3@1+ (1,0) [0|7] ""  park
 SG_ DI_brakePedalState : 19|2@1+ (1,0) [0|2] ""  X
 SG_ DI_systemState : 16|3@1+ (1,0) [0|5] ""  X
 SG_ DI_systemStatusCounter : 8|4@1+ (1,0) [0|15] ""  X
 SG_ DI_systemStatusChecksum : 0|8@1+ (1,0) [0|255] ""  X

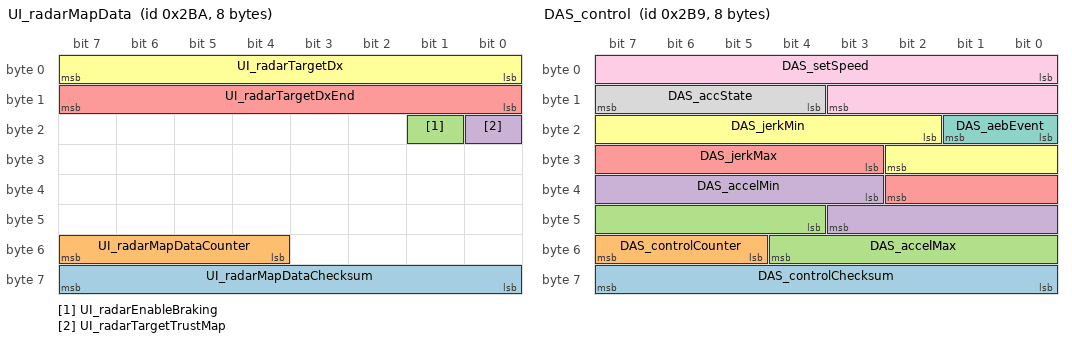
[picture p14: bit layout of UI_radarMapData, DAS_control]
BO_ 698 UI_radarMapData: 8 CH
 SG_ UI_radarMapDataChecksum : 56|8@1+ (1,0) [0|255] ""  das
 SG_ UI_radarMapDataCounter : 52|4@1+ (1,0) [0|15] ""  das
 SG_ UI_radarEnableBraking : 17|1@1+ (1,0) [0|1] ""  das
 SG_ UI_radarTargetTrustMap : 16|1@1+ (1,0) [0|1] ""  das
 SG_ UI_radarTargetDxEnd : 8|8@1+ (1,0) [0|255] "m"  das
 SG_ UI_radarTargetDx : 0|8@1+ (1,-95) [-95|160] "m"  das

BO_ 697 DAS_control: 8 CH
 SG_ DAS_controlChecksum : 56|8@1+ (1,0) [0|255] ""  aps
 SG_ DAS_controlCounter : 53|3@1+ (1,0) [0|7] ""  aps
 SG_ DAS_accelMax : 44|9@1+ (0.04,-15) [-15|5.44] "m/s^2"  aps
 SG_ DAS_accelMin : 35|9@1+ (0.04,-15) [-15|5.44] "m/s^2"  aps
 SG_ DAS_jerkMax : 27|8@1+ (0.034,0) [0|8.67] "m/s^3"  aps
 SG_ DAS_jerkMin : 18|9@1+ (0.018,-9.1) [-9.1|0.097999999999999] "m/s^3"  aps
 SG_ DAS_aebEvent : 16|2@1+ (1,0) [0|3] ""  aps
 SG_ DAS_accState : 12|4@1+ (1,0) [0|15] ""  aps
 SG_ DAS_setSpeed : 0|12@1+ (0.1,0) [0|409.4] "kph"  aps

BO_ 1615 UDS_tpmsRequest: 8 CH
 SG_ UDS_tpmsRequestData : 7|64@0+ (1,0) [0|18446744073709551615] ""  tpms

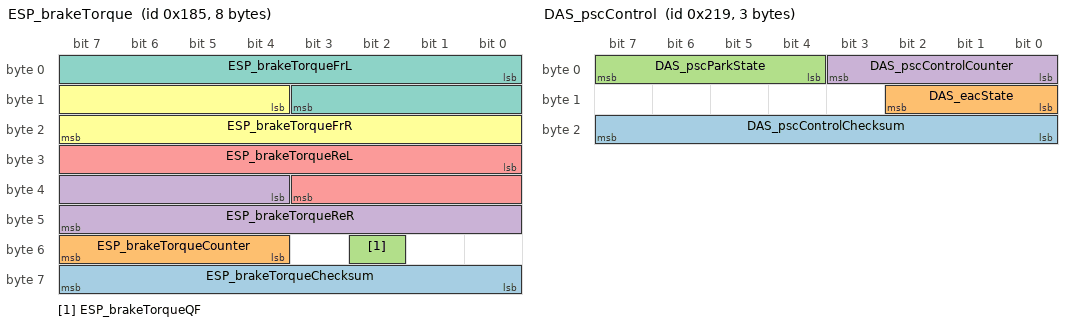
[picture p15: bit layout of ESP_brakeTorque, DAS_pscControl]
BO_ 389 ESP_brakeTorque: 8 CH
 SG_ ESP_brakeTorqueChecksum : 56|8@1+ (1,0) [0|255] ""  X
 SG_ ESP_brakeTorqueCounter : 52|4@1+ (1,0) [0|15] ""  X
 SG_ ESP_brakeTorqueQF : 50|1@1+ (1,0) [0|1] ""  gtw
 SG_ ESP_brakeTorqueReR : 36|12@1+ (2,0) [0|8190] "Nm"  gtw
 SG_ ESP_brakeTorqueReL : 24|12@1+ (2,0) [0|8190] "Nm"  gtw
 SG_ ESP_brakeTorqueFrR : 12|12@1+ (2,0) [0|8190] "Nm"  gtw
 SG_ ESP_brakeTorqueFrL : 0|12@1+ (2,0) [0|8190] "Nm"  gtw

BO_ 537 DAS_pscControl: 3 CH
 SG_ DAS_pscControlChecksum : 16|8@1+ (1,0) [0|255] ""  aps
 SG_ DAS_eacState : 8|3@1+ (1,0) [0|7] ""  aps
 SG_ DAS_pscParkState : 4|4@1+ (1,0) [0|15] ""  aps
 SG_ DAS_pscControlCounter : 0|4@1+ (1,0) [0|15] ""  aps

BO_ 861 IBST_alertMatrix: 8 CH
 SG_ IBST_a120_RPSVectorRangeHigh m1 : 63|1@1+ (1,0) [0|1] ""  gtw
 SG_ IBST_a060_NvMMigrationFault m0 : 63|1@1+ (1,0) [0|1] ""  gtw
 SG_ IBST_a119_RPSWrongCalibData m1 : 62|1@1+ (1,0) [0|1] ""  gtw
 SG_ IBST_a059_NvMEepromSize m0 : 62|1@1+ (1,0) [0|1] ""  gtw
 SG_ IBST_a118_RPSNvMReadFault m1 : 61|1@1+ (1,0) [0|1] ""  gtw
 SG_ IBST_a058_NvMWriteCycleExceed m0 : 61|1@1+ (1,0) [0|1] ""  gtw
 SG_ IBST_a117_supplyOvervoltageLvl2 m1 : 60|1@1+ (1,0) [0|1] ""  gtw
 SG_ IBST_a057_microRegisterFault m0 : 60|1@1+ (1,0) [0|1] ""  gtw
 SG_ IBST_a116_supplyUndervoltageLvl2 m1 : 59|1@1+ (1,0) [0|1] ""  gtw
 SG_ IBST_a056_UB6PlausiMonFault m0 : 59|1@1+ (1,0) [0|1] ""  gtw
 SG_ IBST_a176_blockedPedalDetected m2 : 59|1@1+ (1,0) [0|1] ""  gtw
 SG_ IBST_a115_chassisBusOff m1 : 58|1@1+ (1,0) [0|1] ""  gtw
 SG_ IBST_a055_UB6SupplyPathFault m0 : 58|1@1+ (1,0) [0|1] ""  gtw
 SG_ IBST_a175_LVGoingDownInvalid m2 : 58|1@1+ (1,0) [0|1] ""  gtw
 SG_ IBST_a114_partyBusOff m1 : 57|1@1+ (1,0) [0|1] ""  gtw
 SG_ IBST_a054_AdcPeripheralFault m0 : 57|1@1+ (1,0) [0|1] ""  gtw
 SG_ IBST_a174_LVOffStateInvalid m2 : 57|1@1+ (1,0) [0|1] ""  gtw
 SG_ IBST_a053_AdcSelftestC5P m0 : 56|1@1+ (1,0) [0|1] ""  gtw
 SG_ IBST_a113_LiPS1SentSensor m1 : 56|1@1+ (1,0) [0|1] ""  gtw
 SG_ IBST_a173_LVPowerStateCounter m2 : 56|1@1+ (1,0) [0|1] ""  gtw
 SG_ IBST_a052_AdcPinTest m0 : 55|1@1+ (1,0) [0|1] ""  gtw
 SG_ IBST_a172_LVPowerStateDLC m2 : 55|1@1+ (1,0) [0|1] ""  gtw
 SG_ IBST_a112_LiPS1SentTransmission m1 : 55|1@1+ (1,0) [0|1] ""  gtw
 SG_ IBST_a171_LVPowerStateChecksum m2 : 54|1@1+ (1,0) [0|1] ""  gtw
 SG_ IBST_a051_ecuBandgap m0 : 54|1@1+ (1,0) [0|1] ""  gtw
 SG_ IBST_a111_LiPS1SentLineLow m1 : 54|1@1+ (1,0) [0|1] ""  gtw
 SG_ IBST_a050_VPreExternalFeeding m0 : 53|1@1+ (1,0) [0|1] ""  gtw
 SG_ IBST_a110_LiPS1SentLineHigh m1 : 53|1@1+ (1,0) [0|1] ""  gtw
 SG_ IBST_a170_LVPowerStateTimeout m2 : 53|1@1+ (1,0) [0|1] ""  gtw
 SG_ IBST_a049_WdhTaskMonConCnt m0 : 52|1@1+ (1,0) [0|1] ""  gtw
 SG_ IBST_a169_CANUndervoltage m2 : 52|1@1+ (1,0) [0|1] ""  gtw
 SG_ IBST_a109_LiPS2PwmTransmission m1 : 52|1@1+ (1,0) [0|1] ""  gtw
 SG_ IBST_a048_WdhSwBistConCnt m0 : 51|1@1+ (1,0) [0|1] ""  gtw
 SG_ IBST_a108_LiPS2PwmLineLow m1 : 51|1@1+ (1,0) [0|1] ""  gtw
 SG_ IBST_a168_CANOvervoltage m2 : 51|1@1+ (1,0) [0|1] ""  gtw
 SG_ IBST_a167_ESPqTargetExterInvalid m2 : 50|1@1+ (1,0) [0|1] ""  gtw
 SG_ IBST_a047_WdhAsicWdCmdMissing m0 : 50|1@1+ (1,0) [0|1] ""  gtw
 SG_ IBST_a107_LiPS2PwmLineHigh m1 : 50|1@1+ (1,0) [0|1] ""  gtw
 SG_ IBST_a046_WdhAsicWdErrorCntLimit m0 : 49|1@1+ (1,0) [0|1] ""  gtw
 SG_ IBST_a166_ESPpMcVirtualInvalid m2 : 49|1@1+ (1,0) [0|1] ""  gtw
 SG_ IBST_a106_LiPS5VSupply m1 : 49|1@1+ (1,0) [0|1] ""  gtw
 SG_ IBST_a105_LiPSUndervoltage m1 : 48|1@1+ (1,0) [0|1] ""  gtw
 SG_ IBST_a165_ESPpForceBlendInvalid m2 : 48|1@1+ (1,0) [0|1] ""  gtw
 SG_ IBST_a045_WdhAsicWdErrorCntStuck m0 : 48|1@1+ (1,0) [0|1] ""  gtw
 SG_ IBST_a104_bridgeDriverShort m1 : 47|1@1+ (1,0) [0|1] ""  gtw
 SG_ IBST_a164_ESPVehicleSpeedInvalid m2 : 47|1@1+ (1,0) [0|1] ""  gtw
 SG_ IBST_a044_NvMEepromWIP m0 : 47|1@1+ (1,0) [0|1] ""  gtw
 SG_ IBST_a043_micSpiTransferError m0 : 46|1@1+ (1,0) [0|1] ""  gtw
 SG_ IBST_a103_current1OffsetLow m1 : 46|1@1+ (1,0) [0|1] ""  gtw
 SG_ IBST_a163_ESPpEstMaxInvalid m2 : 46|1@1+ (1,0) [0|1] ""  gtw
 SG_ IBST_a042_micAsicInitTestError m0 : 45|1@1+ (1,0) [0|1] ""  gtw
 SG_ IBST_a162_idlePosNotDetected m2 : 45|1@1+ (1,0) [0|1] ""  gtw
 SG_ IBST_a102_current1OffsetHigh m1 : 45|1@1+ (1,0) [0|1] ""  gtw
 SG_ IBST_a161_powerPackMismatch m2 : 44|1@1+ (1,0) [0|1] ""  gtw
 SG_ IBST_a101_current2OffsetLow m1 : 44|1@1+ (1,0) [0|1] ""  gtw
 SG_ IBST_a041_micAsicClkInError m0 : 44|1@1+ (1,0) [0|1] ""  gtw
 SG_ IBST_a040_GTMTbuMonError m0 : 43|1@1+ (1,0) [0|1] ""  gtw
 SG_ IBST_a160_DTSIDTimeOut m2 : 43|1@1+ (1,0) [0|1] ""  gtw
 SG_ IBST_a100_current2OffsetHigh m1 : 43|1@1+ (1,0) [0|1] ""  gtw
 SG_ IBST_a159_FindIdleNvMReadError m2 : 42|1@1+ (1,0) [0|1] ""  gtw
 SG_ IBST_a099_bridgeSwitchInitError m1 : 42|1@1+ (1,0) [0|1] ""  gtw
 SG_ IBST_a039_GTMRefFrequencyError m0 : 42|1@1+ (1,0) [0|1] ""  gtw
 SG_ IBST_a038_ecuEnContinuousError m0 : 41|1@1+ (1,0) [0|1] ""  gtw
 SG_ IBST_a098_bridgeShortedPhase m1 : 41|1@1+ (1,0) [0|1] ""  gtw
 SG_ IBST_a158_DTSOffsHighSuspicious m2 : 41|1@1+ (1,0) [0|1] ""  gtw
 SG_ IBST_a097_bridgeDriverError m1 : 40|1@1+ (1,0) [0|1] ""  gtw
 SG_ IBST_a037_ecuWdSContinuousError m0 : 40|1@1+ (1,0) [0|1] ""  gtw
 SG_ IBST_a157_masterCylPressInvalid m2 : 40|1@1+ (1,0) [0|1] ""  gtw
 SG_ IBST_a156_supplyOvervoltageLvl1 m2 : 39|1@1+ (1,0) [0|1] ""  gtw
 SG_ IBST_a096_bridgeDriverMonError m1 : 39|1@1+ (1,0) [0|1] ""  gtw
 SG_ IBST_a036_MRGPathTestFault m0 : 39|1@1+ (1,0) [0|1] ""  gtw
 SG_ IBST_a035_ecuEnableHyLowFault m0 : 38|1@1+ (1,0) [0|1] ""  gtw
 SG_ IBST_a095_XPASSTimeOut m1 : 38|1@1+ (1,0) [0|1] ""  gtw
 SG_ IBST_a155_supplyUndervoltageLvl1 m2 : 38|1@1+ (1,0) [0|1] ""  gtw
 SG_ IBST_a154_PSCImpedanceTooLow m2 : 37|1@1+ (1,0) [0|1] ""  gtw
 SG_ IBST_a034_ecuEnableHyHighFault m0 : 37|1@1+ (1,0) [0|1] ""  gtw
 SG_ IBST_a094_XPASSEchoTimeDeviation m1 : 37|1@1+ (1,0) [0|1] ""  gtw
 SG_ IBST_a093_UEXSOvertemperature m1 : 36|1@1+ (1,0) [0|1] ""  gtw
 SG_ IBST_a153_PSCImpedanceTooHigh m2 : 36|1@1+ (1,0) [0|1] ""  gtw
 SG_ IBST_a033_ecuWdStartuptestFault m0 : 36|1@1+ (1,0) [0|1] ""  gtw
 SG_ IBST_a032_ecuEnableElHighFault m0 : 35|1@1+ (1,0) [0|1] ""  gtw
 SG_ IBST_a092_systemStartTimeOut m1 : 35|1@1+ (1,0) [0|1] ""  gtw
 SG_ IBST_a152_PSCVoltageImplausible m2 : 35|1@1+ (1,0) [0|1] ""  gtw
 SG_ IBST_a151_PSCGearRatioReadFault m2 : 34|1@1+ (1,0) [0|1] ""  gtw
 SG_ IBST_a031_decoupleBitTestFault m0 : 34|1@1+ (1,0) [0|1] ""  gtw
 SG_ IBST_a091_SMMOneRequestsInit m1 : 34|1@1+ (1,0) [0|1] ""  gtw
 SG_ IBST_a090_rotorCosOutOfRangeHigh m1 : 33|1@1+ (1,0) [0|1] ""  gtw
 SG_ IBST_a150_motorTestFault m2 : 33|1@1+ (1,0) [0|1] ""  gtw
 SG_ IBST_a030_ecuEnableElLowFault m0 : 33|1@1+ (1,0) [0|1] ""  gtw
 SG_ IBST_a029_ecuErrpinCounterFault m0 : 32|1@1+ (1,0) [0|1] ""  gtw
 SG_ IBST_a089_rotorSinOutOfRangeHigh m1 : 32|1@1+ (1,0) [0|1] ""  gtw
 SG_ IBST_a149_MLITMCAreaReadFault m2 : 32|1@1+ (1,0) [0|1] ""  gtw
 SG_ IBST_a028_ecuBistFaultCtrFault m0 : 31|1@1+ (1,0) [0|1] ""  gtw
 SG_ IBST_a148_MLIGainMechReadFault m2 : 31|1@1+ (1,0) [0|1] ""  gtw
 SG_ IBST_a088_rotorCosOutOfRangeLow m1 : 31|1@1+ (1,0) [0|1] ""  gtw
 SG_ IBST_a147_PSCMotorSizeReadFault m2 : 30|1@1+ (1,0) [0|1] ""  gtw
 SG_ IBST_a087_rotorSinOutOfRangeLow m1 : 30|1@1+ (1,0) [0|1] ""  gtw
 SG_ IBST_a027_ecuFastWdTestFault m0 : 30|1@1+ (1,0) [0|1] ""  gtw
 SG_ IBST_a146_ESPparty3Counter m2 : 29|1@1+ (1,0) [0|1] ""  gtw
 SG_ IBST_a086_supplyOvervoltageLvl3 m1 : 29|1@1+ (1,0) [0|1] ""  gtw
 SG_ IBST_a026_ecuBistCmdTestFault m0 : 29|1@1+ (1,0) [0|1] ""  gtw
 SG_ IBST_a145_ESPparty3Checksum m2 : 28|1@1+ (1,0) [0|1] ""  gtw
 SG_ IBST_a025_ecuClockTestFault m0 : 28|1@1+ (1,0) [0|1] ""  gtw
 SG_ IBST_a085_supplyUndervoltageLvl3 m1 : 28|1@1+ (1,0) [0|1] ""  gtw
 SG_ IBST_a024_chargePumpFault m0 : 27|1@1+ (1,0) [0|1] ""  gtw
 SG_ IBST_a084_CANTransceiverHWFault m1 : 27|1@1+ (1,0) [0|1] ""  gtw
 SG_ IBST_a144_ESPparty3Timeout m2 : 27|1@1+ (1,0) [0|1] ""  gtw
 SG_ IBST_a023_U5VOutOfRange m0 : 26|1@1+ (1,0) [0|1] ""  gtw
 SG_ IBST_a143_ESPparty3DLC m2 : 26|1@1+ (1,0) [0|1] ""  gtw
 SG_ IBST_a083_spindlePositionTooHigh m1 : 26|1@1+ (1,0) [0|1] ""  gtw
 SG_ IBST_a142_ESPparty2Counter m2 : 25|1@1+ (1,0) [0|1] ""  gtw
 SG_ IBST_a082_motorSpeedDeviation m1 : 25|1@1+ (1,0) [0|1] ""  gtw
 SG_ IBST_a022_U5VTestFault m0 : 25|1@1+ (1,0) [0|1] ""  gtw
 SG_ IBST_a021_IREFOutOfRange m0 : 24|1@1+ (1,0) [0|1] ""  gtw
 SG_ IBST_a141_ESPparty2Checksum m2 : 24|1@1+ (1,0) [0|1] ""  gtw
 SG_ IBST_a081_travelDeviation m1 : 24|1@1+ (1,0) [0|1] ""  gtw
 SG_ IBST_a080_motorTempHighLevel2 m1 : 23|1@1+ (1,0) [0|1] ""  gtw
 SG_ IBST_a020_VPREU5VOutOfRange m0 : 23|1@1+ (1,0) [0|1] ""  gtw
 SG_ IBST_a140_ESPparty2Timeout m2 : 23|1@1+ (1,0) [0|1] ""  gtw
 SG_ IBST_a079_motorTempHighLevel1 m1 : 22|1@1+ (1,0) [0|1] ""  gtw
 SG_ IBST_a139_ESPparty2DLC m2 : 22|1@1+ (1,0) [0|1] ""  gtw
 SG_ IBST_a019_supplyASICInitFault m0 : 22|1@1+ (1,0) [0|1] ""  gtw
 SG_ IBST_a018_unsupportedHW m0 : 21|1@1+ (1,0) [0|1] ""  gtw
 SG_ IBST_a138_ESPparty1Counter m2 : 21|1@1+ (1,0) [0|1] ""  gtw
 SG_ IBST_a078_wearOffsetCompNVMRead m1 : 21|1@1+ (1,0) [0|1] ""  gtw
 SG_ IBST_a077_runOutMotorSaturated m1 : 20|1@1+ (1,0) [0|1] ""  gtw
 SG_ IBST_a137_ESPparty1Checksum m2 : 20|1@1+ (1,0) [0|1] ""  gtw
 SG_ IBST_a017_assertionFault m0 : 20|1@1+ (1,0) [0|1] ""  gtw
 SG_ IBST_a076_masterCylLengthRead m1 : 19|1@1+ (1,0) [0|1] ""  gtw
 SG_ IBST_a016_RBBLMShaftShiftError m0 : 19|1@1+ (1,0) [0|1] ""  gtw
 SG_ IBST_a136_ESPparty1Timeout m2 : 19|1@1+ (1,0) [0|1] ""  gtw
 SG_ IBST_a135_ESPparty1DLC m2 : 18|1@1+ (1,0) [0|1] ""  gtw
 SG_ IBST_a075_FindIdleRoutineFault m1 : 18|1@1+ (1,0) [0|1] ""  gtw
 SG_ IBST_a015_asicOscillatorError m0 : 18|1@1+ (1,0) [0|1] ""  gtw
 SG_ IBST_a134_DTSOffsetTooHigh m2 : 17|1@1+ (1,0) [0|1] ""  gtw
 SG_ IBST_a074_FindIdleDataNvMWrite m1 : 17|1@1+ (1,0) [0|1] ""  gtw
 SG_ IBST_a014_DMATransferError m0 : 17|1@1+ (1,0) [0|1] ""  gtw
 SG_ IBST_a073_jumpInAdjustNvMRead m1 : 16|1@1+ (1,0) [0|1] ""  gtw
 SG_ IBST_a013_systemTaskJitter m0 : 16|1@1+ (1,0) [0|1] ""  gtw
 SG_ IBST_a133_DTSOffsetTooLow m2 : 16|1@1+ (1,0) [0|1] ""  gtw
 SG_ IBST_a012_OSTaskSchemeError m0 : 15|1@1+ (1,0) [0|1] ""  gtw
 SG_ IBST_a072_notShutDownRight m1 : 15|1@1+ (1,0) [0|1] ""  gtw
 SG_ IBST_a132_DTSPlausiCheck1vs2 m2 : 15|1@1+ (1,0) [0|1] ""  gtw
 SG_ IBST_a131_DTSFunctionalRangeHigh m2 : 14|1@1+ (1,0) [0|1] ""  gtw
 SG_ IBST_a011_systemTaskOverRun m0 : 14|1@1+ (1,0) [0|1] ""  gtw
 SG_ IBST_a071_notShutDownNvMRead m1 : 14|1@1+ (1,0) [0|1] ""  gtw
 SG_ IBST_a070_notShutDownNvMWrite m1 : 13|1@1+ (1,0) [0|1] ""  gtw
 SG_ IBST_a010_OSErrorHook m0 : 13|1@1+ (1,0) [0|1] ""  gtw
 SG_ IBST_a130_DTSFunctionalRangeLow m2 : 13|1@1+ (1,0) [0|1] ""  gtw
 SG_ IBST_a129_loadDumpOnFSLTest m2 : 12|1@1+ (1,0) [0|1] ""  gtw
 SG_ IBST_a009_systemErrorHook m0 : 12|1@1+ (1,0) [0|1] ""  gtw
 SG_ IBST_a069_greasingRoutineFault m1 : 12|1@1+ (1,0) [0|1] ""  gtw
 SG_ IBST_a008_stackOverUnderFlow m0 : 11|1@1+ (1,0) [0|1] ""  gtw
 SG_ IBST_a128_BLMMuxerTimeoutError m2 : 11|1@1+ (1,0) [0|1] ""  gtw
 SG_ IBST_a068_chargePumpUndervoltage m1 : 11|1@1+ (1,0) [0|1] ""  gtw
 SG_ IBST_a067_tempSensImplausVoltage m1 : 10|1@1+ (1,0) [0|1] ""  gtw
 SG_ IBST_a007_RBCPUException m0 : 10|1@1+ (1,0) [0|1] ""  gtw
 SG_ IBST_a127_OBDCurrent2OORLow m2 : 10|1@1+ (1,0) [0|1] ""  gtw
 SG_ IBST_a066_tempSens1ShortToSupply m1 : 9|1@1+ (1,0) [0|1] ""  gtw
 SG_ IBST_a126_OBDCurrent1OORLow m2 : 9|1@1+ (1,0) [0|1] ""  gtw
 SG_ IBST_a006_microSafetyLogicFault m0 : 9|1@1+ (1,0) [0|1] ""  gtw
 SG_ IBST_a125_OBDCurrent2OORHigh m2 : 8|1@1+ (1,0) [0|1] ""  gtw
 SG_ IBST_a065_tempSens2ShortToGround m1 : 8|1@1+ (1,0) [0|1] ""  gtw
 SG_ IBST_a005_microSafetyFault m0 : 8|1@1+ (1,0) [0|1] ""  gtw
 SG_ IBST_a064_tempSens1ShortToGround m1 : 7|1@1+ (1,0) [0|1] ""  gtw
 SG_ IBST_a124_OBDCurrent1OORHigh m2 : 7|1@1+ (1,0) [0|1] ""  gtw
 SG_ IBST_a004_flashFault m0 : 7|1@1+ (1,0) [0|1] ""  gtw
 SG_ IBST_a063_tempSens2ShortToSupply m1 : 6|1@1+ (1,0) [0|1] ""  gtw
 SG_ IBST_a123_bridgeDriverUnavail m2 : 6|1@1+ (1,0) [0|1] ""  gtw
 SG_ IBST_a003_RAMFault m0 : 6|1@1+ (1,0) [0|1] ""  gtw
 SG_ IBST_a062_MICB6TransferError m1 : 5|1@1+ (1,0) [0|1] ""  gtw
 SG_ IBST_a122_RPSVectorOscillating m2 : 5|1@1+ (1,0) [0|1] ""  gtw
 SG_ IBST_a002_HWBISTError m0 : 5|1@1+ (1,0) [0|1] ""  gtw
 SG_ IBST_a061_AswSystemTimeOut m1 : 4|1@1+ (1,0) [0|1] ""  gtw
 SG_ IBST_a001_microSupplyError m0 : 4|1@1+ (1,0) [0|1] ""  gtw
 SG_ IBST_a121_RPSVectorRangeLow m2 : 4|1@1+ (1,0) [0|1] ""  gtw
 SG_ IBST_matrixIndex M : 0|4@1+ (1,0) [0|15] ""  gtw

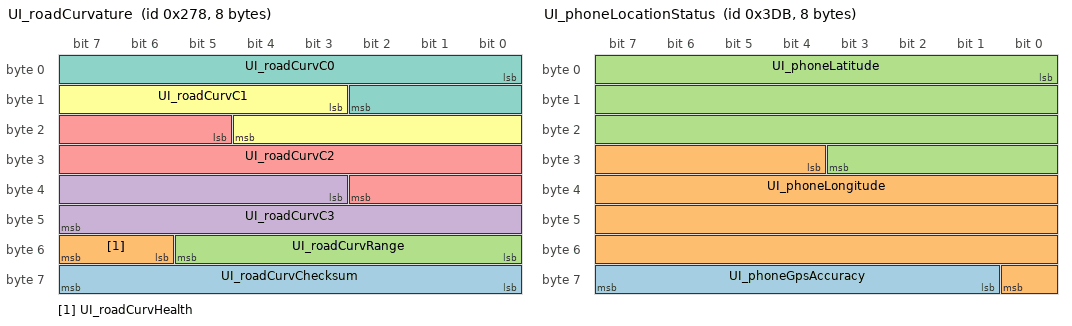
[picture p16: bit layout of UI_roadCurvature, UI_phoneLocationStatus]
BO_ 632 UI_roadCurvature: 8 CH
 SG_ UI_roadCurvChecksum : 56|8@1+ (1,0) [0|255] ""  X
 SG_ UI_roadCurvHealth : 54|2@1+ (1,0) [0|3] ""  das
 SG_ UI_roadCurvRange : 48|6@1+ (4,0) [0|252] "m"  das
 SG_ UI_roadCurvC3 : 35|13@1- (3e-08,0.0) [-0.00012288|0.00012285] "1/m2"  das
 SG_ UI_roadCurvC2 : 21|14@1- (7.5e-06,0.0) [-0.03072|0.03071625] "1/m"  das
 SG_ UI_roadCurvC1 : 11|10@1- (0.00075,0.0) [-0.384|0.38325] "1"  das
 SG_ UI_roadCurvC0 : 0|11@1- (0.02,0.0) [-20.48|20.46] "m"  das

BO_ 987 UI_phoneLocationStatus: 8 CH
 SG_ UI_phoneGpsAccuracy : 57|7@1+ (0.2,0) [0|25.2] "m"  das
 SG_ UI_phoneLongitude : 28|29@1- (1e-06,0) [-268.43546|268.43546] "deg"  das
 SG_ UI_phoneLatitude : 0|28@1- (1e-06,0) [-134.21773|134.21773] "deg"  das

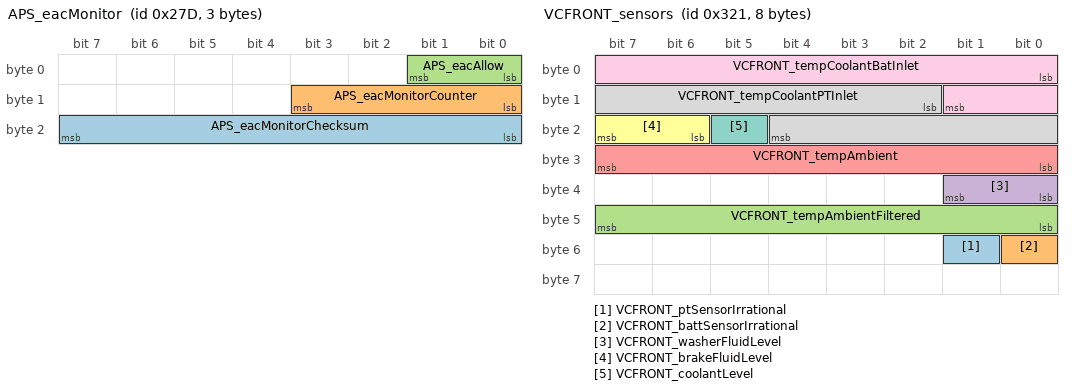
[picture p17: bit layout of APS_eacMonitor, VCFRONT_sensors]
BO_ 637 APS_eacMonitor: 3 CH
 SG_ APS_eacMonitorChecksum : 16|8@1+ (1,0) [0|255] ""  epas3s
 SG_ APS_eacMonitorCounter : 8|4@1+ (1,0) [0|15] ""  epas3s
 SG_ APS_eacAllow : 0|2@1+ (1,0) [0|3] ""  epas3s

BO_ 937 DAS_telemetry: 8 CH
 SG_ DAS_stopSignIndex m2 : 59|4@1+ (1,0) [0|15] ""  gtw
 SG_ DAS_stopSignCrossingWarning m2 : 58|1@1+ (1,0) [0|1] ""  gtw
 SG_ DAS_soRad5powerdB m8 : 57|7@1+ (2,0) [0|254] "dB"  gtw
 SG_ DAS_egoSpeedAtIntervention m1 : 57|6@1+ (0.5,0) [0|32] "m/s"  gtw
 SG_ DAS_csaMeasLatAccel m7 : 56|8@1+ (0.08,-10.24) [-10.24|10] "m/s^2"  gtw
 SG_ DAS_soRad5Dz m8 : 51|6@1+ (0.25,-5) [-5|10.75] "m"  gtw
 SG_ DAS_targetDistAtIntervention m1 : 51|6@1+ (0.5,0) [0|32] "m"  gtw
 SG_ DAS_stopSignHostAccel m2 : 48|10@1+ (0.01,-5) [-5|5.23] "m/s^2"  gtw
 SG_ DAS_soRad5ObstProb m8 : 47|4@1+ (0.0625,0) [0|0.9375] "probability"  gtw
 SG_ DAS_targetRelvelAtIntervention m1 : 45|6@1+ (0.25,-2) [-2|13.5] "m/s"  gtw
 SG_ DAS_stopSignCIPVDistance m2 : 42|6@1+ (0.5,0) [0|31.5] "m"  gtw
 SG_ DAS_soCamCipvVx m8 : 42|5@1+ (1,0) [0|31] "m/s"  gtw
 SG_ DAS_csaFiltCurv m7 : 40|16@1- (1e-06,0.0) [-0.032768|0.032767] "1/m"  gtw
 SG_ DAS_maxAbsSteeringWheelAngle m1 : 38|7@1+ (2,0) [0|256] "degrees"  gtw
 SG_ DAS_soRad5Dy m8 : 37|5@1+ (0.4,-6.4) [-6.4|6] "m"  gtw
 SG_ DAS_soCamCipvDy m8 : 32|5@1+ (0.4,-6.4) [-6.4|6] "m"  gtw
 SG_ DAS_stopSignStopLineDistance m2 : 32|10@1+ (0.1,-20) [-20|82.2] "m"  gtw
 SG_ DAS_durationOfPrevACCStandstill m1 : 32|6@1+ (0.5,0) [0|30] "s"  gtw
 SG_ DAS_assSmartSpeedActive m9 : 31|1@1+ (1,0) [0|1] ""  gtw
 SG_ DAS_assAutosteerActive m9 : 30|1@1+ (1,0) [0|1] ""  gtw
 SG_ DAS_timeOfACCReengaging m1 : 26|6@1+ (0.25,0) [0|16] "s"  gtw
 SG_ DAS_soRad5Dx m8 : 26|6@1+ (2,0) [0|126] "m"  gtw
 SG_ DAS_csaDisableSpeed m7 : 26|12@1+ (0.05,-25) [-25|179.75] "MPH"  gtw
 SG_ DAS_stopSignHeight m2 : 26|6@1+ (0.1,0) [0|6.2] "m"  gtw
 SG_ DAS_assFusedSpeedLimit m9 : 24|6@1+ (1,0) [0|63] "m/s"  gtw
 SG_ DAS_telRightLaneCrossing m0 : 23|1@1+ (1,0) [0|1] ""  gtw
 SG_ DAS_telLeftLaneCrossing m0 : 22|1@1+ (1,0) [0|1] ""  gtw
 SG_ DAS_timeOfFirstPedestrian m1 : 20|6@1+ (0.25,0) [0|16] "s"  gtw
 SG_ DAS_soRad1Dx m8 : 20|6@1+ (2,0) [0|126] "m"  gtw
 SG_ DAS_telRightMarkerColor m0 : 20|2@1+ (1,0) [0|3] ""  gtw
 SG_ DAS_stopSignLateralDist m2 : 18|8@1+ (0.25,-32) [-32|31.5] "m"  gtw
 SG_ DAS_telLeftMarkerColor m0 : 18|2@1+ (1,0) [0|3] ""  gtw
 SG_ DAS_telRightMarkerQuality m0 : 16|2@1+ (1,0) [0|3] ""  gtw
 SG_ DAS_assNewSetSpeed m9 : 16|8@1+ (0.25,0) [0|63.75] "m/s"  gtw
 SG_ DAS_csaEnableSpeed m7 : 14|12@1+ (0.05,-25) [-25|179.75] "MPH"  gtw
 SG_ DAS_telLeftMarkerQuality m0 : 14|2@1+ (1,0) [0|3] ""  gtw
 SG_ DAS_soCamCipvDx m8 : 14|6@1+ (2,0) [0|126] "m"  gtw
 SG_ DAS_timeOfIntervention m1 : 14|6@1+ (0.25,0) [0|16] "s"  gtw
 SG_ DAS_camFreeSpaceAfterIntr m1 : 13|1@1+ (1,0) [0|1] ""  gtw
 SG_ DAS_soRad1Status m8 : 12|2@1+ (1,0) [0|3] ""  gtw
 SG_ DAS_camFreeSpaceBeforeIntr m1 : 12|1@1+ (1,0) [0|1] ""  gtw
 SG_ DAS_pedestrianInFOVAfterIntr m1 : 11|1@1+ (1,0) [0|1] ""  gtw
 SG_ DAS_telRightLaneType m0 : 11|3@1+ (1,0) [0|6] ""  gtw
 SG_ DAS_csaIntState m7 : 11|3@1+ (1,0) [0|7] ""  gtw
 SG_ DAS_pedestrianInFOVBeforeIntr m1 : 10|1@1+ (1,0) [0|1] ""  gtw
 SG_ DAS_csaOverride m7 : 10|1@1+ (1,0) [0|1] ""  gtw
 SG_ DAS_soRad5Status m8 : 10|2@1+ (1,0) [0|3] ""  gtw
 SG_ DAS_accReengaged m1 : 9|1@1+ (1,0) [0|1] ""  gtw
 SG_ DAS_telLeftLaneType m0 : 8|3@1+ (1,0) [0|6] ""  gtw
 SG_ DAS_MCPObserved m1 : 8|1@1+ (1,0) [0|1] ""  gtw
 SG_ DAS_soCamCipvStatus m8 : 8|2@1+ (1,0) [0|3] ""  gtw
 SG_ DAS_stopSignLongitudinalDist m2 : 8|10@1+ (0.1,0) [0|102.2] "m"  gtw
 SG_ DAS_assPrevSetSpeed m9 : 8|8@1+ (0.25,0) [0|63.75] "m/s"  gtw
 SG_ DAS_telemetryMultiplexer M : 0|8@1+ (1,0) [0|9] ""  gtw

BO_ 971 APS_summonStatus: 1 CH
 SG_ APS_smartSummonActive : 0|1@1+ (1,0) [0|1] ""  app

BO_ 801 VCFRONT_sensors: 8 CH
 SG_ VCFRONT_ptSensorIrrational : 49|1@1+ (1,0) [0|1] ""  X
 SG_ VCFRONT_battSensorIrrational : 48|1@1+ (1,0) [0|1] ""  X
 SG_ VCFRONT_tempAmbientFiltered : 40|8@1+ (0.5,-40) [-40|80] "degC"  park
 SG_ VCFRONT_washerFluidLevel : 32|2@1+ (1,0) [0|2] ""  X
 SG_ VCFRONT_tempAmbient : 24|8@1+ (0.5,-40) [-40|80] "degC"  epas3s
 SG_ VCFRONT_brakeFluidLevel : 22|2@1+ (1,0) [0|2] ""  X
 SG_ VCFRONT_coolantLevel : 21|1@1+ (1,0) [0|1] ""  X
 SG_ VCFRONT_tempCoolantPTInlet : 10|11@1+ (0.125,-40) [-40|200] "degC"  X
 SG_ VCFRONT_tempCoolantBatInlet : 0|10@1+ (0.125,-40) [-40|85] "degC"  X

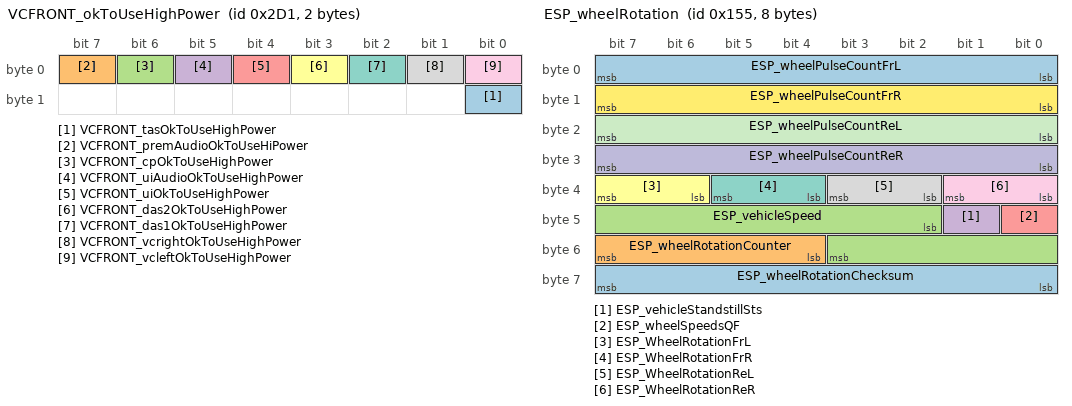
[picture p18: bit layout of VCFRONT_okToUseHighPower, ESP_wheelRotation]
BO_ 721 VCFRONT_okToUseHighPower: 2 CH
 SG_ VCFRONT_tasOkToUseHighPower : 8|1@1+ (1,0) [0|1] ""  tas
 SG_ VCFRONT_premAudioOkToUseHiPower : 7|1@1+ (1,0) [0|1] ""  X
 SG_ VCFRONT_cpOkToUseHighPower : 6|1@1+ (1,0) [0|1] ""  X
 SG_ VCFRONT_uiAudioOkToUseHighPower : 5|1@1+ (1,0) [0|1] ""  X
 SG_ VCFRONT_uiOkToUseHighPower : 4|1@1+ (1,0) [0|1] ""  X
 SG_ VCFRONT_das2OkToUseHighPower : 3|1@1+ (1,0) [0|1] ""  X
 SG_ VCFRONT_das1OkToUseHighPower : 2|1@1+ (1,0) [0|1] ""  X
 SG_ VCFRONT_vcrightOkToUseHighPower : 1|1@1+ (1,0) [0|1] ""  X
 SG_ VCFRONT_vcleftOkToUseHighPower : 0|1@1+ (1,0) [0|1] ""  X

BO_ 341 ESP_wheelRotation: 8 CH
 SG_ ESP_wheelRotationChecksum : 56|8@1+ (1,0) [0|255] ""  app
 SG_ ESP_wheelRotationCounter : 52|4@1+ (1,0) [0|15] ""  app
 SG_ ESP_vehicleSpeed : 42|10@1+ (0.5,0) [0|511] "kph"  app
 SG_ ESP_vehicleStandstillSts : 41|1@1+ (1,0) [0|1] ""  park
 SG_ ESP_wheelSpeedsQF : 40|1@1+ (1,0) [0|1] ""  epas3s
 SG_ ESP_WheelRotationFrL : 38|2@1+ (1,0) [0|3] ""  aps
 SG_ ESP_WheelRotationFrR : 36|2@1+ (1,0) [0|3] ""  aps
 SG_ ESP_WheelRotationReL : 34|2@1+ (1,0) [0|3] ""  aps
 SG_ ESP_WheelRotationReR : 32|2@1+ (1,0) [0|3] ""  aps
 SG_ ESP_wheelPulseCountReR : 24|8@1+ (1,0) [0|254] "1"  das
 SG_ ESP_wheelPulseCountReL : 16|8@1+ (1,0) [0|254] "1"  das
 SG_ ESP_wheelPulseCountFrR : 8|8@1+ (1,0) [0|254] "1"  app
 SG_ ESP_wheelPulseCountFrL : 0|8@1+ (1,0) [0|254] "1"  app

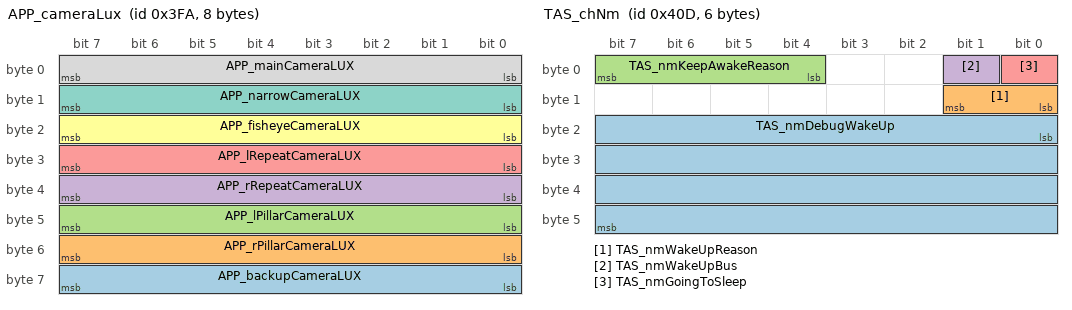
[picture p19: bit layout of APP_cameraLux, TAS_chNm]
BO_ 1018 APP_cameraLux: 8 CH
 SG_ APP_backupCameraLUX : 56|8@1+ (50,0) [0|12750] "lux"  gtw
 SG_ APP_rPillarCameraLUX : 48|8@1+ (50,0) [0|12750] "lux"  gtw
 SG_ APP_lPillarCameraLUX : 40|8@1+ (50,0) [0|12750] "lux"  gtw
 SG_ APP_rRepeatCameraLUX : 32|8@1+ (50,0) [0|12750] "lux"  gtw
 SG_ APP_lRepeatCameraLUX : 24|8@1+ (50,0) [0|12750] "lux"  gtw
 SG_ APP_fisheyeCameraLUX : 16|8@1+ (50,0) [0|12750] "lux"  gtw
 SG_ APP_narrowCameraLUX : 8|8@1+ (50,0) [0|12750] "lux"  gtw
 SG_ APP_mainCameraLUX : 0|8@1+ (50,0) [0|12750] "lux"  gtw

BO_ 1113 APS_warningMatrix2: 8 CH
 SG_ APS_w161_gpsAntennaDisconnected : 32|1@1+ (1,0) [0|1] ""  gtw
 SG_ APS_w160_apbVersionMismatch : 31|1@1+ (1,0) [0|1] ""  gtw
 SG_ APS_w159_apbCritical : 30|1@1+ (1,0) [0|1] ""  gtw
 SG_ APS_w158_apbMia : 29|1@1+ (1,0) [0|1] ""  gtw
 SG_ APS_w157_autopilotReboot : 28|1@1+ (1,0) [0|1] ""  gtw
 SG_ APS_w156_lwipAssert : 27|1@1+ (1,0) [0|1] ""  gtw
 SG_ APS_w155_ethLwipError : 26|1@1+ (1,0) [0|1] ""  gtw
 SG_ APS_w153_eacInhibit : 24|1@1+ (1,0) [0|1] ""  gtw
 SG_ APS_w152_gpsFusionStatus : 23|1@1+ (1,0) [0|1] ""  gtw
 SG_ APS_w151_apRecovered : 22|1@1+ (1,0) [0|1] ""  gtw
 SG_ APS_w150_sccmMiaVehBus : 21|1@1+ (1,0) [0|1] ""  gtw
 SG_ APS_w149_epblMiaVehBus : 20|1@1+ (1,0) [0|1] ""  gtw
 SG_ APS_w148_vcrightMiaVehBus : 19|1@1+ (1,0) [0|1] ""  gtw
 SG_ APS_w147_vcleftMiaVehBus : 18|1@1+ (1,0) [0|1] ""  gtw
 SG_ APS_w146_epas3pMiaPartyBus : 17|1@1+ (1,0) [0|1] ""  gtw
 SG_ APS_w145_vcrightMiaPartyBus : 16|1@1+ (1,0) [0|1] ""  gtw
 SG_ APS_w144_vcleftMiaPartyBus : 15|1@1+ (1,0) [0|1] ""  gtw
 SG_ APS_w143_espMiaPartyBus : 14|1@1+ (1,0) [0|1] ""  gtw
 SG_ APS_w142_diMiaPartyBus : 13|1@1+ (1,0) [0|1] ""  gtw
 SG_ APS_w141_rcmMiaPartyBus : 12|1@1+ (1,0) [0|1] ""  gtw
 SG_ APS_w140_vcfrontMiaVehicleBus : 11|1@1+ (1,0) [0|1] ""  gtw
 SG_ APS_w139_udpBufferOverflow : 10|1@1+ (1,0) [0|1] ""  gtw
 SG_ APS_w138_gpsComIssue : 9|1@1+ (1,0) [0|1] ""  gtw
 SG_ APS_w137_gpsFaultReset : 8|1@1+ (1,0) [0|1] ""  gtw
 SG_ APS_w136_gpsDisabled : 7|1@1+ (1,0) [0|1] ""  gtw
 SG_ APS_w135_appCritical : 6|1@1+ (1,0) [0|1] ""  gtw
 SG_ APS_w134_appMia : 5|1@1+ (1,0) [0|1] ""  gtw
 SG_ APS_w133_ETHSwitchError : 4|1@1+ (1,0) [0|1] ""  gtw
 SG_ APS_w132_appVersionMismatch : 3|1@1+ (1,0) [0|1] ""  gtw
 SG_ APS_w131_trap_exception : 2|1@1+ (1,0) [0|1] ""  gtw
 SG_ APS_w130_ECU_Thermal_Issue : 1|1@1+ (1,0) [0|1] ""  gtw
 SG_ APS_w129_ECU_Power_Issue : 0|1@1+ (1,0) [0|1] ""  gtw

BO_ 564 OCS1P_debugADC: 6 CH
 SG_ OCS1P_sandwichComparator : 32|16@1+ (1,0) [0|65535] ""  X
 SG_ OCS1P_selfComparatorTemp : 16|16@1+ (1,0) [0|65535] ""  X
 SG_ OCS1P_sandwichTemp : 0|16@1+ (1,0) [0|65535] ""  X

BO_ 785 EPAS3S_info: 8 CH
 SG_ EPAS3S_infoComponentID m10 : 48|16@1+ (1,0) [0|65535] ""  gtw
 SG_ EPAS3S_infoApplicationCRC m13 : 32|32@1+ (1,0) [0|4294967295] ""  gtw
 SG_ EPAS3S_infoUsageID m11 : 32|16@1+ (1,0) [0|65535] ""  gtw
 SG_ EPAS3S_infoBootloaderCRC m20 : 32|32@1+ (1,0) [0|4294967295] ""  gtw
 SG_ EPAS3S_infoAssemblyID m11 : 24|8@1+ (1,0) [0|255] ""  gtw
 SG_ EPAS3S_infoPcbaID m11 : 16|8@1+ (1,0) [0|255] ""  gtw
 SG_ EPAS3S_infoBootUdsProtoVersion m20 : 8|8@1+ (1,0) [0|255] ""  gtw
 SG_ EPAS3S_infoBuildType m10 : 8|8@1+ (1,0) [0|4] ""  gtw
 SG_ EPAS3S_infoIndex M : 0|8@1+ (1,0) [0|255] ""  gtw

BO_ 890 DAS_telemetryPeriodic: 8 CH
 SG_ DAS_TP_bdlFuse m6 : 63|1@1+ (1,0) [0|1] ""  gtw
 SG_ DAS_TP_vlFuse m5 : 63|1@1+ (1,0) [0|1] ""  gtw
 SG_ DAS_TP_llFuse m1 : 63|1@1+ (1,0) [0|1] ""  gtw
 SG_ DAS_TP_rlFuse m2 : 63|1@1+ (1,0) [0|1] ""  gtw
 SG_ DAS_TP_navFuse m4 : 63|1@1+ (1,0) [0|1] ""  gtw
 SG_ DAS_TP_bdrFuse m7 : 63|1@1+ (1,0) [0|1] ""  gtw
 SG_ DAS_TP_hppFuse m3 : 63|1@1+ (1,0) [0|1] ""  gtw
 SG_ DAS_TP_bdrQltyME m8 : 62|2@1+ (1,0) [0|3] ""  gtw
 SG_ DAS_TP_lcState m0 : 60|4@1+ (1,0) [0|15] ""  gtw
 SG_ DAS_TP_bdlQltyME m8 : 60|2@1+ (1,0) [0|3] ""  gtw
 SG_ DAS_TP_egoLane m9 : 59|3@1+ (1,0) [0|7] ""  gtw
 SG_ DAS_TP_rlQltyME m8 : 58|2@1+ (1,0) [0|3] ""  gtw
 SG_ DAS_TP_bdrRange m7 : 56|7@1+ (1,0) [0|127] "m"  gtw
 SG_ DAS_TP_rlRange m2 : 56|7@1+ (1,0) [0|127] "m"  gtw
 SG_ DAS_TP_hppRange m3 : 56|7@1+ (1,0) [0|127] "m"  gtw
 SG_ DAS_TP_navRange m4 : 56|7@1+ (1,0) [0|127] "m"  gtw
 SG_ DAS_TP_llRange m1 : 56|7@1+ (1,0) [0|127] "m"  gtw
 SG_ DAS_TP_llQltyME m8 : 56|2@1+ (1,0) [0|3] ""  gtw
 SG_ DAS_TP_plannerState m0 : 56|4@1+ (1,0) [0|15] ""  gtw
 SG_ DAS_TP_bdlRange m6 : 56|7@1+ (1,0) [0|127] "m"  gtw
 SG_ DAS_TP_vlRange m5 : 56|7@1+ (1,0) [0|127] "m"  gtw
 SG_ DAS_TP_hppQlty m3 : 55|1@1+ (1,0) [0|1] ""  gtw
 SG_ DAS_TP_rlQlty m2 : 55|1@1+ (1,0) [0|1] ""  gtw
 SG_ DAS_TP_bdrQlty m7 : 55|1@1+ (1,0) [0|1] ""  gtw
 SG_ DAS_TP_navQlty m4 : 55|1@1+ (1,0) [0|1] ""  gtw
 SG_ DAS_TP_vlQlty m5 : 55|1@1+ (1,0) [0|1] ""  gtw
 SG_ DAS_TP_bdlQlty m6 : 55|1@1+ (1,0) [0|1] ""  gtw
 SG_ DAS_TP_llQlty m1 : 55|1@1+ (1,0) [0|1] ""  gtw
 SG_ DAS_TP_rlType m0 : 53|3@1+ (1,0) [0|7] ""  gtw
 SG_ DAS_TP_lane8LLR m9 : 53|6@1+ (0.3125,-10) [-10|9.6875] "1"  gtw
 SG_ DAS_TP_nrlProb m8 : 52|4@1+ (0.1,0) [0|1.5] "1"  gtw
 SG_ DAS_TP_llType m0 : 50|3@1+ (1,0) [0|7] ""  gtw
 SG_ DAS_TP_nllProb m8 : 48|4@1+ (0.1,0) [0|1.5] "1"  gtw
 SG_ DAS_TP_laneChange m0 : 48|2@1+ (1,0) [0|3] ""  gtw
 SG_ DAS_TP_lane7LLR m9 : 47|6@1+ (0.3125,-10) [-10|9.6875] "1"  gtw
 SG_ DAS_TP_accRestricted m0 : 46|1@1+ (1,0) [0|1] ""  gtw
 SG_ DAS_TP_rlExist m8 : 44|4@1+ (10,0) [0|150] "%"  gtw
 SG_ DAS_TP_vehFuse m0 : 44|1@1+ (1,0) [0|1] ""  gtw
 SG_ DAS_TP_restrictedAccess m0 : 43|1@1+ (1,0) [0|1] ""  gtw
 SG_ DAS_TP_hppValid m0 : 42|1@1+ (1,0) [0|1] ""  gtw
 SG_ DAS_TP_hppC3 m3 : 41|14@1- (1.6e-08,0.0) [-0.000131072|0.000131056] "1/m2"  gtw
 SG_ DAS_TP_rlC3 m2 : 41|14@1- (1.6e-08,0.0) [-0.000131072|0.000131056] "1/m2"  gtw
 SG_ DAS_TP_bdrC3 m7 : 41|14@1- (1.6e-08,0.0) [-0.000131072|0.000131056] "1/m2"  gtw
 SG_ DAS_TP_navC3 m4 : 41|14@1- (1.6e-08,0.0) [-0.000131072|0.000131056] "1/m2"  gtw
 SG_ DAS_TP_vlC3 m5 : 41|14@1- (1.6e-08,0.0) [-0.000131072|0.000131056] "1/m2"  gtw
 SG_ DAS_TP_lane6LLR m9 : 41|6@1+ (0.3125,-10) [-10|9.6875] "1"  gtw
 SG_ DAS_TP_bdlC3 m6 : 41|14@1- (1.6e-08,0.0) [-0.000131072|0.000131056] "1/m2"  gtw
 SG_ DAS_TP_llC3 m1 : 41|14@1- (1.6e-08,0.0) [-0.000131072|0.000131056] "1/m2"  gtw
 SG_ DAS_TP_llExist m8 : 40|4@1+ (10,0) [0|150] "%"  gtw
 SG_ DAS_TP_rlSegQ4 m8 : 36|4@1+ (10,0) [0|150] "%"  gtw
 SG_ DAS_TP_lane5LLR m9 : 35|6@1+ (0.3125,-10) [-10|9.6875] "1"  gtw
 SG_ DAS_TP_sonicDistR m0 : 33|9@1+ (0.01,0) [0|5.11] "m"  gtw
 SG_ DAS_TP_rlSegQ3 m8 : 32|4@1+ (10,0) [0|150] "%"  gtw
 SG_ DAS_TP_lane4LLR m9 : 29|6@1+ (0.3125,-10) [-10|9.6875] "1"  gtw
 SG_ DAS_TP_rlSegQ2 m8 : 28|4@1+ (10,0) [0|150] "%"  gtw
 SG_ DAS_TP_hppC2 m3 : 27|14@1- (4e-06,0.0) [-0.032768|0.032764] "1/m"  gtw
 SG_ DAS_TP_rlC2 m2 : 27|14@1- (4e-06,0.0) [-0.032768|0.032764] "1/m"  gtw
 SG_ DAS_TP_bdrC2 m7 : 27|14@1- (4e-06,0.0) [-0.032768|0.032764] "1/m"  gtw
 SG_ DAS_TP_bdlC2 m6 : 27|14@1- (4e-06,0.0) [-0.032768|0.032764] "1/m"  gtw
 SG_ DAS_TP_vlC2 m5 : 27|14@1- (4e-06,0.0) [-0.032768|0.032764] "1/m"  gtw
 SG_ DAS_TP_llC2 m1 : 27|14@1- (4e-06,0.0) [-0.032768|0.032764] "1/m"  gtw
 SG_ DAS_TP_navC2 m4 : 27|14@1- (4e-06,0.0) [-0.032768|0.032764] "1/m"  gtw
 SG_ DAS_TP_sonicDistL m0 : 24|9@1+ (0.01,0) [0|5.11] "m"  gtw
 SG_ DAS_TP_rlSegQ1 m8 : 24|4@1+ (10,0) [0|150] "%"  gtw
 SG_ DAS_TP_handsOn m0 : 23|1@1+ (1,0) [0|1] ""  gtw
 SG_ DAS_TP_lane3LLR m9 : 23|6@1+ (0.3125,-10) [-10|9.6875] "1"  gtw
 SG_ DAS_TP_wipersActive m0 : 22|1@1+ (1,0) [0|1] ""  gtw
 SG_ DAS_TP_llSegQ4 m8 : 20|4@1+ (10,0) [0|150] "%"  gtw
 SG_ DAS_TP_navC1 m4 : 18|9@1- (0.001953125,0.0) [-0.5|0.498046875] "rad"  gtw
 SG_ DAS_TP_rlC1 m2 : 18|9@1- (0.001953125,0.0) [-0.5|0.498046875] "rad"  gtw
 SG_ DAS_TP_llC1 m1 : 18|9@1- (0.001953125,0.0) [-0.5|0.498046875] "rad"  gtw
 SG_ DAS_TP_vlC1 m5 : 18|9@1- (0.001953125,0.0) [-0.5|0.498046875] "rad"  gtw
 SG_ DAS_TP_bdlC1 m6 : 18|9@1- (0.001953125,0.0) [-0.5|0.498046875] "rad"  gtw
 SG_ DAS_TP_hppC1 m3 : 18|9@1- (0.001953125,0.0) [-0.5|0.498046875] "rad"  gtw
 SG_ DAS_TP_bdrC1 m7 : 18|9@1- (0.001953125,0.0) [-0.5|0.498046875] "rad"  gtw
 SG_ DAS_TP_lane2LLR m9 : 17|6@1+ (0.3125,-10) [-10|9.6875] "1"  gtw
 SG_ DAS_TP_llSegQ3 m8 : 16|4@1+ (10,0) [0|150] "%"  gtw
 SG_ DAS_TP_hppError m0 : 16|6@1+ (0.05,0) [0|3.15] "m"  gtw
 SG_ DAS_TP_llSegQ2 m8 : 12|4@1+ (10,0) [0|150] "%"  gtw
 SG_ DAS_TP_lane1LLR m9 : 11|6@1+ (0.3125,-10) [-10|9.6875] "1"  gtw
 SG_ DAS_TP_llC0 m1 : 8|10@1- (0.02,0.0) [-10.24|10.22] "m"  gtw
 SG_ DAS_TP_numLanes m9 : 8|3@1+ (1,0) [0|7] ""  gtw
 SG_ DAS_TP_vlWidth m0 : 8|8@1+ (0.05,0) [0|12.75] "m"  gtw
 SG_ DAS_TP_bdlC0 m6 : 8|10@1- (0.02,0.0) [-10.24|10.22] "m"  gtw
 SG_ DAS_TP_llSegQ1 m8 : 8|4@1+ (10,0) [0|150] "%"  gtw
 SG_ DAS_TP_vlC0 m5 : 8|10@1- (0.02,0.0) [-10.24|10.22] "m"  gtw
 SG_ DAS_TP_navC0 m4 : 8|10@1- (0.02,0.0) [-10.24|10.22] "m"  gtw
 SG_ DAS_TP_hppC0 m3 : 8|10@1- (0.02,0.0) [-10.24|10.22] "m"  gtw
 SG_ DAS_TP_bdrC0 m7 : 8|10@1- (0.02,0.0) [-10.24|10.22] "m"  gtw
 SG_ DAS_TP_rlC0 m2 : 8|10@1- (0.02,0.0) [-10.24|10.22] "m"  gtw
 SG_ DAS_TP_counter m0 : 5|3@1+ (1,0) [0|7] ""  gtw
 SG_ DAS_TP_llCounter m1 : 5|3@1+ (1,0) [0|7] ""  gtw
 SG_ DAS_TP_rlCounter m2 : 5|3@1+ (1,0) [0|7] ""  gtw
 SG_ DAS_TP_bdrCounter m7 : 5|3@1+ (1,0) [0|7] ""  gtw
 SG_ DAS_TP_navCounter m4 : 5|3@1+ (1,0) [0|7] ""  gtw
 SG_ DAS_TP_llrCounter m9 : 5|3@1+ (1,0) [0|7] ""  gtw
 SG_ DAS_TP_hppCounter m3 : 5|3@1+ (1,0) [0|7] ""  gtw
 SG_ DAS_TP_laneCounter m8 : 5|3@1+ (1,0) [0|7] ""  gtw
 SG_ DAS_TP_bdlCounter m6 : 5|3@1+ (1,0) [0|7] ""  gtw
 SG_ DAS_TP_vlCounter m5 : 5|3@1+ (1,0) [0|7] ""  gtw
 SG_ DAS_TP_multiplexer M : 0|5@1+ (1,0) [0|9] ""  gtw

BO_ 1037 TAS_chNm: 6 CH
 SG_ TAS_nmDebugWakeUp : 16|32@1+ (1,0) [0|4294967295] ""  gtw
 SG_ TAS_nmWakeUpReason : 8|2@1+ (1,0) [0|3] ""  gtw
 SG_ TAS_nmKeepAwakeReason : 4|4@1+ (1,0) [0|15] ""  gtw
 SG_ TAS_nmWakeUpBus : 1|1@1+ (1,0) [0|1] ""  X
 SG_ TAS_nmGoingToSleep : 0|1@1+ (1,0) [0|1] ""  X

BO_ 1851 TAS_xcpResponse: 8 CH
 SG_ TAS_xcpResponse : 7|64@0+ (1,0) [0|18446744073709551615] ""  X

BA_DEF_ SG_  "SystemSignalLongSymbol" STRING ;
BA_DEF_DEF_  "SystemSignalLongSymbol" "";
VAL_ 1815 RCM_imuOffsetsIndex 1 "SECOND_FRAME" 0 "FIRST_FRAME" ;
VAL_ 981 ESP_matrixIndex 0 "ESP_AlertMatrix0" 1 "ESP_AlertMatrix1" 2 "ESP_AlertMatrix2" 3 "ESP_AlertMatrix3" 4 "ESP_AlertMatrix4" ;
VAL_ 659 UI_selfParkTune 15 "SNA" ;
VAL_ 659 UI_redLightStopSignEnable 3 "SNA" 1 "RLSSW_ON" 0 "RLSSW_OFF" ;
VAL_ 659 UI_pedalSafetyEnable 3 "SNA" 0 "PEDAL_SAFETY_OFF" 1 "PEDAL_SAFETY_ON" ;
VAL_ 659 UI_ldwEnable 3 "SNA" 1 "LDW_TRIGGERS_HAPTIC" 0 "NO_HAPTIC" ;
VAL_ 659 UI_latControlEnable 3 "LATERAL_CONTROL_SNA" 2 "LATERAL_CONTROL_UNAVAILABLE" 1 "LATERAL_CONTROL_ON" 0 "LATERAL_CONTROL_OFF" ;
VAL_ 659 UI_fcwSensitivity 3 "SNA" 2 "AEB_SENSITIVITY_LATE" 1 "AEB_SENSITIVITY_AVERAGE" 0 "AEB_SENSITIVITY_EARLY" ;
VAL_ 659 UI_fcwEnable 3 "SNA" 1 "FCW_ON" 0 "FCW_OFF" ;
VAL_ 659 UI_bsdEnable 3 "SNA" 0 "BSD_OFF" 1 "BSD_ON" ;
VAL_ 659 UI_autoLaneChangeEnable 3 "SNA" 0 "OFF" 1 "ON" ;
VAL_ 659 UI_autoParkRequest 15 "SNA" 7 "ABORT" 0 "NONE" 2 "PARK_LEFT_CROSS" 1 "PARK_LEFT_PARALLEL" 5 "PARALLEL_PULL_OUT_TO_LEFT" 6 "PARALLEL_PULL_OUT_TO_RIGHT" 10 "PAUSE" 3 "PARK_RIGHT_PARALLEL" 9 "SEARCH" 4 "PARK_RIGHT_CROSS" 8 "COMPLETE" 11 "RESUME" ;
VAL_ 659 UI_ahlbEnable 3 "SNA" 0 "AHLB_OFF" 1 "AHLB_ON" ;
VAL_ 659 UI_aesEnable 3 "SNA" 0 "AES_OFF" 1 "AES_ON" ;
VAL_ 659 UI_aebEnable 3 "SNA" 1 "AEB_ON" 0 "AEB_OFF" ;
VAL_ 659 UI_accOvertakeEnable 3 "SNA" 1 "ACC_OVERTAKE_ON" 0 "ACC_OVERTAKE_OFF" ;
VAL_ 659 UI_distanceUnits 0 "DISTANCEUNITS_KM" 1 "DISTANCEUNITS_MILES" ;
VAL_ 659 UI_suspensionLevelRequest 7 "REQUEST_VERY_LOW_LEVEL" 5 "TOGGLE_JACK_MODE" 4 "REQUEST_VERY_HIGH_LEVEL" 2 "REQUEST_NORMAL_LEVEL" 6 "SWITCH_DEFECT" 0 "NO_CHANGE_SNA" 1 "REQUEST_LOW_LEVEL" 3 "REQUEST_HIGH_LEVEL" ;
VAL_ 659 UI_trailerMode 1 "TRAILER_MODE_ON" 0 "TRAILER_MODE_OFF" ;
VAL_ 659 UI_zeroSpeedConfirmed 0 "ZERO_SPEED_CANCELED" 1 "ZERO_SPEED_CONFIRMED" 3 "ZERO_SPEED_SNA" 2 "ZERO_SPEED_UNUSED" ;
VAL_ 659 UI_winchModeRequest 0 "WINCH_MODE_IDLE" 2 "WINCH_MODE_EXIT" 1 "WINCH_MODE_ENTER" ;
VAL_ 659 UI_parkBrakeRequest 1 "PARK_BRAKE_REQUEST_PRESSED" 3 "PARK_BRAKE_REQUEST_SNA" 0 "PARK_BRAKE_REQUEST_IDLE" ;
VAL_ 659 UI_tractionControlMode 4 "TC_ROLLS_MODE_SELECTED" 1 "TC_SLIP_START_SELECTED" 0 "TC_NORMAL_SELECTED" 3 "TC_DEV_MODE_2_SELECTED" 2 "TC_DEV_MODE_1_SELECTED" 5 "TC_DYNO_MODE_SELECTED" ;
VAL_ 659 UI_steeringTuneRequest 1 "STEERING_TUNE_STANDARD" 2 "STEERING_TUNE_SPORT" 0 "STEERING_TUNE_COMFORT" ;
VAL_ 862 PARK_rearRightMiddleRawDistData 255 "SNA" ;
VAL_ 862 PARK_rearMiddleRawDistData 255 "SNA" ;
VAL_ 862 PARK_rearLeftMiddleRawDistData 255 "SNA" ;
VAL_ 917 OCS1P_matrixIndex 2 "OCS1P_AlertMatrix2" ;
VAL_ 552 GTW_warningIndicatorStatus 3 "SNA" 0 "WARNING_LAMP_OFF" 1 "WARNING_LAMP_ON" ;
VAL_ 552 GTW_airbagCutoffSwState 2 "SNA" 0 "PASSENGER_AIRBAG_ON" 1 "PASSENGER_AIRBAG_OFF" ;
VAL_ 569 DAS_rightFork 0 "RIGHT_FORK_NONE" 2 "RIGHT_FORK_SELECTED" 3 "RIGHT_FORK_UNAVAILABLE" 1 "RIGHT_FORK_AVAILABLE" ;
VAL_ 569 DAS_leftFork 1 "LEFT_FORK_AVAILABLE" 2 "LEFT_FORK_SELECTED" 0 "LEFT_FORK_NONE" 3 "LEFT_FORK_UNAVAILABLE" ;
VAL_ 569 DAS_rightLineUsage 3 "BLACKLISTED" 0 "REJECTED_UNAVAILABLE" 2 "FUSED" 1 "AVAILABLE" ;
VAL_ 569 DAS_leftLineUsage 3 "BLACKLISTED" 0 "REJECTED_UNAVAILABLE" 2 "FUSED" 1 "AVAILABLE" ;
VAL_ 586 DAS_rearVehDetectedThisCycle 0 "VEHICLE_NOT_DETECTED" 1 "VEHICLE_DETECTED" ;
VAL_ 586 DAS_ulcType 0 "ULC_TYPE_NONE" 1 "ULC_TYPE_NAV" 2 "ULC_TYPE_SPEED" ;
VAL_ 586 DAS_behaviorType 1 "DAS_BEHAVIOR_IN_LANE" 3 "DAS_BEHAVIOR_LANE_CHANGE_RIGHT" 0 "DAS_BEHAVIOR_INVALID" 2 "DAS_BEHAVIOR_LANE_CHANGE_LEFT" ;
VAL_ 586 DAS_ulcInProgress 0 "ULC_INACTIVE" 1 "ULC_ACTIVE" ;
VAL_ 586 DAS_accSmartSpeedState 7 "SNA" 1 "ACTIVE_OFFRAMP" 2 "ACTIVE_INTEGRATING" 5 "OFFRAMP_DELAY" 0 "NOT_ACTIVE" 3 "ACTIVE_ONRAMP" 4 "SET_SPEED_SET_REQUESTED" ;
VAL_ 586 DAS_navAvailable 0 "DAS_NAV_UNAVAILABLE" 1 "DAS_NAV_AVAILABLE" ;
VAL_ 586 DAS_lastAutosteerAbortReason 18 "UI_ABORT_REASON_TRAILER_MODE" 28 "UI_ABORT_REASON_EPAS_ERROR_CODE" 14 "UI_ABORT_REASON_APP_ME_STATE_NOT_VISION" 20 "UI_ABORT_REASON_EPAS_EAC_DENIED" 24 "UI_ABORT_REASON_DRIVING_OFF_NAV" 29 "UI_ABORT_REASON_ACC_CANCEL" 26 "UI_ABORT_REASON_FOLLOWER_OUTPUT_INVALID" 2 "UI_ABORT_REASON_HM_STEERING_ERROR" 17 "UI_ABORT_REASON_CAM_WATCHDOG" 21 "UI_ABORT_REASON_COMPONENT_MIA" 15 "UI_ABORT_REASON_ME_MAIN_STATE_NOT_VISION" 25 "UI_ABORT_REASON_VEHICLE_SPEED_ABOVE_MAX" 19 "UI_ABORT_REASON_SIDE_COLLISION_IMMINENT" 27 "UI_ABORT_REASON_PLANNER_OUTPUT_INVALID" 32 "UI_ABORT_REASON_AEB" 1 "UI_ABORT_REASON_HM_VIRTUAL_LANE_NO_INPUTS" 22 "UI_ABORT_REASON_CRUISE_FAULT" 0 "UI_ABORT_REASON_HM_LANE_VIEW_RANGE" 30 "UI_ABORT_REASON_CAMERA_FAILSAFES" 16 "UI_ABORT_REASON_CAM_MSG_MIA" 31 "UI_ABORT_REASON_NO_ABORT" 23 "UI_ABORT_REASON_CID_SWITCH_DISABLED" ;
VAL_ 586 DAS_plannerState 0 "TP_EXTSTATE_DISABLED" 1 "TP_EXTSTATE_VL" 4 "TP_EXTSTATE_LANECHANGE_IN_PROGRESS" 6 "TP_EXTSTATE_LANECHANGE_WAIT_FOR_FWD_OBSTACLE" 7 "TP_EXTSTATE_LANECHANGE_ABORT" 3 "TP_EXTSTATE_LANECHANGE_REQUESTED" 5 "TP_EXTSTATE_LANECHANGE_WAIT_FOR_SIDE_OBSTACLE" 2 "TP_EXTSTATE_FOLLOW" ;
VAL_ 586 DAS_lastLinePreferenceReason 1 "AGREEMENT_WITH_NEIGHBOR_LANES" 15 "NONE" 4 "AVOID_ONCOMING_LANES" 3 "NAVIGATION_BRANCH" 5 "COUNTRY_DRIVING_SIDE" 2 "NEIGHBOR_LANE_PROBABILIY" 0 "OTHER_LANE_DISAGREES_WITH_MODEL" ;
VAL_ 586 DAS_autosteerHealthState 1 "HEALTH_NOMINAL" 5 "HEALTH_FAULT" 4 "HEALTH_ABORTING" 0 "HEALTH_UNAVAILABLE" 3 "HEALTH_SEVERELY_DEGRADED" 2 "HEALTH_DEGRADED" ;
VAL_ 586 DAS_roadSurfaceType 2 "ROAD_SURFACE_ENHANCED" 1 "ROAD_SURFACE_NORMAL" 0 "ROAD_SURFACE_SNA" ;
VAL_ 586 DAS_offsetSide 0 "NO_OFFSET" 3 "OFFSET_BOTH_OBJECTS" 1 "OFFSET_RIGHT_OBJECT" 2 "OFFSET_LEFT_OBJECT" ;
VAL_ 586 DAS_autosteerBottsDotsUsage 3 "BLACKLISTED" 0 "REJECTED_UNAVAILABLE" 2 "FUSED" 1 "AVAILABLE" ;
VAL_ 586 DAS_autosteerModelUsage 3 "BLACKLISTED" 0 "REJECTED_UNAVAILABLE" 2 "FUSED" 1 "AVAILABLE" ;
VAL_ 586 DAS_autosteerNavigationUsage 3 "BLACKLISTED" 0 "REJECTED_UNAVAILABLE" 2 "FUSED" 1 "AVAILABLE" ;
VAL_ 586 DAS_autosteerHPPUsage 3 "BLACKLISTED" 0 "REJECTED_UNAVAILABLE" 2 "FUSED" 1 "AVAILABLE" ;
VAL_ 586 DAS_autosteerVehiclesUsage 3 "BLACKLISTED" 0 "REJECTED_UNAVAILABLE" 2 "FUSED" 1 "AVAILABLE" ;
VAL_ 12 UI_cellSignalBars 5 "FIVE" 7 "SNA" 1 "ONE" 2 "TWO" 0 "ZERO" 4 "FOUR" 3 "THREE" ;
VAL_ 12 UI_cellNetworkTechnology 15 "CELL_NETWORK_SNA" 5 "CELL_NETWORK_HSUPA" 3 "CELL_NETWORK_UMTS" 0 "CELL_NETWORK_NONE" 6 "CELL_NETWORK_HSPA" 7 "CELL_NETWORK_LTE" 1 "CELL_NETWORK_GPRS" 2 "CELL_NETWORK_EDGE" 4 "CELL_NETWORK_HSDPA" ;
VAL_ 12 UI_factoryReset 0 "NONE_SNA" 3 "CUSTOMER" 2 "DIAGNOSTIC" 1 "DEVELOPER" ;
VAL_ 12 UI_autopilotTrial 0 "NONE" 1 "START" 3 "ACTIVE" 2 "STOP" ;
VAL_ 1451 OCS1P_alertClearedID 128 "OCS1P_a128_seatbackSelfLow" 124 "OCS1P_a124_cushionSelfOpen" 123 "OCS1P_a123_sandwichShort" 134 "OCS1P_a134_uninitializedCalib" 141 "OCS1P_a141_humidityInvalidCalib" 131 "OCS1P_a131_cushionSelfNoCalib" 126 "OCS1P_a126_cushionSelfShort" 133 "OCS1P_a133_sandwichBadCalib" 130 "OCS1P_a130_sandwichNoCalib" 142 "OCS1P_a142_tempHumidityInvalid" 125 "OCS1P_a125_cushionSelfLow" 121 "OCS1P_a121_sandwichOpen" 122 "OCS1P_a122_sandwichLow" 132 "OCS1P_a132_seatbackSelfNoCalib" 140 "OCS1P_a140_tempInvalidCalib" 136 "OCS1P_a136_cushionSelfDutyLow" 139 "OCS1P_a139_seatbackSelfDutyHigh" 135 "OCS1P_a135_tempNoCalib" 0 "OCS1P_ALERT_DO_NOT_USE_ZERO" 129 "OCS1P_a129_seatbackSelfShort" 127 "OCS1P_a127_seatbackSelfOpen" 138 "OCS1P_a138_seatbackSelfDutyLow" 137 "OCS1P_a137_cushionSelfDutyHigh" ;
VAL_ 789 OCS1P_infoBuildType 1 "INFO_PLATFORM_BUILD" 3 "INFO_TRACEABLE_CI_BUILD" 4 "INFO_MFG_BUILD" 2 "INFO_LOCAL_BUILD" 0 "INFO_UNKNOWN_BUILD" ;
VAL_ 789 OCS1P_infoIndex 20 "Mux20" 11 "Mux11" 10 "Mux10" 13 "Mux13" 14 "Mux14" 19 "Mux19" 17 "Mux17" 18 "Mux18" ;
VAL_ 1011 UI_odometer 16777215 "SNA" ;
VAL_ 962 VCLEFT_rearRightOccupancySwitch 2 "SWITCH_ON" 0 "SWITCH_SNA" 3 "SWITCH_FAULT" 1 "SWITCH_OFF" ;
VAL_ 962 VCLEFT_rearLeftOccupancySwitch 2 "SWITCH_ON" 0 "SWITCH_SNA" 3 "SWITCH_FAULT" 1 "SWITCH_OFF" ;
VAL_ 962 VCLEFT_rearCenterOccupancySwitch 2 "SWITCH_ON" 0 "SWITCH_SNA" 3 "SWITCH_FAULT" 1 "SWITCH_OFF" ;
VAL_ 962 VCLEFT_rearLeftBuckleSwitch 2 "SWITCH_ON" 0 "SWITCH_SNA" 3 "SWITCH_FAULT" 1 "SWITCH_OFF" ;
VAL_ 962 VCLEFT_frontOccupancySwitch 2 "SWITCH_ON" 0 "SWITCH_SNA" 3 "SWITCH_FAULT" 1 "SWITCH_OFF" ;
VAL_ 962 VCLEFT_frontBuckleSwitch 2 "SWITCH_ON" 0 "SWITCH_SNA" 3 "SWITCH_FAULT" 1 "SWITCH_OFF" ;
VAL_ 962 VCLEFT_frontSeatLumbarOut 2 "SWITCH_ON" 0 "SWITCH_SNA" 3 "SWITCH_FAULT" 1 "SWITCH_OFF" ;
VAL_ 962 VCLEFT_frontSeatLumbarIn 2 "SWITCH_ON" 0 "SWITCH_SNA" 3 "SWITCH_FAULT" 1 "SWITCH_OFF" ;
VAL_ 962 VCLEFT_frontSeatLumbarUp 2 "SWITCH_ON" 0 "SWITCH_SNA" 3 "SWITCH_FAULT" 1 "SWITCH_OFF" ;
VAL_ 962 VCLEFT_frontSeatLumbarDown 2 "SWITCH_ON" 0 "SWITCH_SNA" 3 "SWITCH_FAULT" 1 "SWITCH_OFF" ;
VAL_ 962 VCLEFT_frontSeatBackrestForward 2 "SWITCH_ON" 0 "SWITCH_SNA" 3 "SWITCH_FAULT" 1 "SWITCH_OFF" ;
VAL_ 962 VCLEFT_frontSeatBackrestBack 2 "SWITCH_ON" 0 "SWITCH_SNA" 3 "SWITCH_FAULT" 1 "SWITCH_OFF" ;
VAL_ 962 VCLEFT_frontSeatLiftUp 2 "SWITCH_ON" 0 "SWITCH_SNA" 3 "SWITCH_FAULT" 1 "SWITCH_OFF" ;
VAL_ 962 VCLEFT_frontSeatLiftDown 2 "SWITCH_ON" 0 "SWITCH_SNA" 3 "SWITCH_FAULT" 1 "SWITCH_OFF" ;
VAL_ 962 VCLEFT_frontSeatTiltUp 2 "SWITCH_ON" 0 "SWITCH_SNA" 3 "SWITCH_FAULT" 1 "SWITCH_OFF" ;
VAL_ 962 VCLEFT_swcLeftTiltLeft 2 "SWITCH_ON" 0 "SWITCH_SNA" 3 "SWITCH_FAULT" 1 "SWITCH_OFF" ;
VAL_ 962 VCLEFT_swcRightPressed 2 "SWITCH_ON" 0 "SWITCH_SNA" 3 "SWITCH_FAULT" 1 "SWITCH_OFF" ;
VAL_ 962 VCLEFT_frontSeatTiltDown 2 "SWITCH_ON" 0 "SWITCH_SNA" 3 "SWITCH_FAULT" 1 "SWITCH_OFF" ;
VAL_ 962 VCLEFT_frontSeatTrackForward 2 "SWITCH_ON" 0 "SWITCH_SNA" 3 "SWITCH_FAULT" 1 "SWITCH_OFF" ;
VAL_ 962 VCLEFT_swcRightTiltRight 2 "SWITCH_ON" 0 "SWITCH_SNA" 3 "SWITCH_FAULT" 1 "SWITCH_OFF" ;
VAL_ 962 VCLEFT_swcRightTiltLeft 2 "SWITCH_ON" 0 "SWITCH_SNA" 3 "SWITCH_FAULT" 1 "SWITCH_OFF" ;
VAL_ 962 VCLEFT_frontSeatTrackBack 2 "SWITCH_ON" 0 "SWITCH_SNA" 3 "SWITCH_FAULT" 1 "SWITCH_OFF" ;
VAL_ 962 VCLEFT_swcLeftPressed 2 "SWITCH_ON" 0 "SWITCH_SNA" 3 "SWITCH_FAULT" 1 "SWITCH_OFF" ;
VAL_ 962 VCLEFT_rightMirrorTilt 4 "MIRROR_TILT_LEFT" 2 "MIRROR_TILT_UP" 3 "MIRROR_TILT_RIGHT" 0 "MIRROR_TILT_STOP" 1 "MIRROR_TILT_DOWN" ;
VAL_ 962 VCLEFT_swcLeftTiltRight 2 "SWITCH_ON" 0 "SWITCH_SNA" 3 "SWITCH_FAULT" 1 "SWITCH_OFF" ;
VAL_ 962 VCLEFT_switchStatusIndex 1 "VCLEFT_SWITCH_STATUS_INDEX_1" 2 "VCLEFT_SWITCH_STATUS_INDEX_INVALID" 0 "VCLEFT_SWITCH_STATUS_INDEX_0" ;
VAL_ 1357 TAS_infoHardwareRevision 254 "VERSION_LOCAL_BUILD" 255 "VERSION_SNA" ;
VAL_ 1357 TAS_infoMaturity 254 "VERSION_LOCAL_BUILD" 255 "VERSION_SNA" ;
VAL_ 1357 TAS_infoBranchOrigin 254 "VERSION_LOCAL_BUILD" 255 "VERSION_SNA" ;
VAL_ 1357 TAS_infoAssemblyId 1 "ASSEMBLY1" 255 "ASSEMBLY_SNA" ;
VAL_ 1357 TAS_infoMajorVersion 254 "VERSION_LOCAL_BUILD" 255 "VERSION_SNA" ;
VAL_ 1357 TAS_infoBuildType 1 "INFO_PLATFORM_BUILD" 3 "INFO_TRACEABLE_CI_BUILD" 4 "INFO_MFG_BUILD" 2 "INFO_LOCAL_BUILD" 0 "INFO_UNKNOWN_BUILD" ;
VAL_ 1357 TAS_infoIndex 14 "BC_INFO_BOOTLOADER_SVN" 6 "BC_INFO_DEPRECATED_6" 20 "BC_INFO_UDS_PROTOCOL_BOOTCRC" 24 "BC_INFO_SUBCOMPONENT3" 1 "BC_INFO_DEPRECATED_1" 31 "BC_INFO_SUBCOMPONENT4" 19 "BC_INFO_VERSION_DEPRECATED" 10 "BC_INFO_BUILD_HWID_COMPONENTID" 0 "BC_INFO_DEPRECATED_0" 5 "BC_INFO_DEPRECATED_5" 11 "BC_INFO_PCBAID_ASSYID_USAGEID" 18 "BC_INFO_BOOTLOADER_GITHASH" 3 "BC_INFO_DEPRECATED_3" 15 "BC_INFO_BOOTLOADER_CRC" 4 "BC_INFO_DEPRECATED_4" 16 "BC_INFO_SUBCOMPONENT1" 255 "BC_INFO_END" 9 "BC_INFO_DEPRECATED_9" 13 "BC_INFO_APP_CRC" 2 "BC_INFO_DEPRECATED_2" 23 "BC_INFO_SUBCOMPONENT2" 7 "BC_INFO_DEPRECATED_7" 8 "BC_INFO_DEPRECATED_8" 17 "BC_INFO_APP_GITHASH" ;
VAL_ 1337 DAS_infoHardwareRevision 252 "CONFIGURABLE_HWID_PLACEHOLDER" ;
VAL_ 1337 DAS_infoBuildType 1 "INFO_PLATFORM_BUILD" 3 "INFO_TRACEABLE_CI_BUILD" 4 "INFO_MFG_BUILD" 2 "INFO_LOCAL_BUILD" 0 "INFO_UNKNOWN_BUILD" ;
VAL_ 1337 DAS_infoIndex 2 "DAS_INFO_DEPRECATED_2" 24 "DAS_INFO_EYEQ_FFS" 9 "DAS_INFO_DEPRECATED_9" 15 "DAS_INFO_BOOTLOADER_CRC" 4 "DAS_INFO_DEPRECATED_4" 3 "DAS_INFO_DEPRECATED_3" 18 "DAS_INFO_BOOTLOADER_GITHASH" 5 "DAS_INFO_DEPRECATED_5" 23 "DAS_INFO_EYEQ_APP" 10 "DAS_INFO_BUILD_HWID_COMPONENTID" 17 "DAS_INFO_APP_GITHASH" 0 "DAS_INFO_DEPRECATED_0" 13 "DAS_INFO_APP_CRC" 19 "DAS_INFO_VERSION_DEPRECATED" 255 "DAS_INFO_END" 1 "DAS_INFO_DEPRECATED_1" 20 "DAS_INFO_UDS_PROTOCOL_BOOTCRC" 11 "DAS_INFO_PCBAID_ASSYID_USAGEID" 6 "DAS_INFO_DEPRECATED_6" 14 "DAS_INFO_BOOTLOADER_SVN" 8 "DAS_INFO_DEPRECATED_8" 7 "DAS_INFO_DEPRECATED_7" 16 "DAS_INFO_EYEQ_BOOT" ;
VAL_ 1012 APP_narrowCalibProgress 127 "SNA" ;
VAL_ 1012 APP_lRepeatCalibProgress 127 "SNA" ;
VAL_ 1012 APP_rPillarCalibProgress 127 "SNA" ;
VAL_ 1012 APP_fisheyeCalibProgress 127 "SNA" ;
VAL_ 1012 APP_rRepeatCalibProgress 127 "SNA" ;
VAL_ 1012 APP_backupCalibProgress 127 "SNA" ;
VAL_ 1012 APP_lPillarCalibProgress 127 "SNA" ;
VAL_ 1012 APP_mainCalibProgress 127 "SNA" ;
VAL_ 1012 APP_narrowCalibTime 127 "SNA" ;
VAL_ 1012 APP_lRepeatCalibTime 127 "SNA" ;
VAL_ 1012 APP_rPillarCalibTime 127 "SNA" ;
VAL_ 1012 APP_fisheyeCalibTime 127 "SNA" ;
VAL_ 1012 APP_rRepeatCalibTime 127 "SNA" ;
VAL_ 1012 APP_backupCalibTime 127 "SNA" ;
VAL_ 1012 APP_lPillarCalibTime 127 "SNA" ;
VAL_ 1012 APP_mainCalibTime 127 "SNA" ;
VAL_ 1012 APP_rPillarCamExtYawCal 511 "SNA" ;
VAL_ 1012 APP_narrowCamExtYawCal 511 "SNA" ;
VAL_ 1012 APP_mainCamExtYawCal 511 "SNA" ;
VAL_ 1012 APP_rRepeatCamExtYawCal 511 "SNA" ;
VAL_ 1012 APP_fisheyeCamExtYawCal 511 "SNA" ;
VAL_ 1012 APP_lRepeatCamExtYawCal 511 "SNA" ;
VAL_ 1012 APP_lPillarCamExtYawCal 511 "SNA" ;
VAL_ 1012 APP_backupCamExtYawCal 511 "SNA" ;
VAL_ 1012 APP_lRepeatCamExtPitchCal 511 "SNA" ;
VAL_ 1012 APP_narrowCamExtPitchCal 511 "SNA" ;
VAL_ 1012 APP_backupCamExtPitchCal 511 "SNA" ;
VAL_ 1012 APP_lPillarCamExtPitchCal 511 "SNA" ;
VAL_ 1012 APP_mainCamExtPitchCal 511 "SNA" ;
VAL_ 1012 APP_rPillarCamExtPitchCal 511 "SNA" ;
VAL_ 1012 APP_fisheyeCamExtPitchCal 511 "SNA" ;
VAL_ 1012 APP_rRepeatCamExtPitchCal 511 "SNA" ;
VAL_ 1012 APP_cameraPosition 3 "CAM_FISHEYE" 7 "CAM_R_REPEATER" 1 "CAM_MAIN" 8 "CAM_BACKUP" 0 "CAM_INVALID" 4 "CAM_L_PILLAR" 5 "CAM_R_PILLAR" 2 "CAM_NARROW" 6 "CAM_L_REPEATER" ;
VAL_ 529 RCM_driverOrientationInitStatus 7 "SNA" 4 "RCM_DRIVER_ORIENTATION_MISMATCH_DEFAULT_RHD" 2 "RCM_DRIVER_ORIENTATION_MATCHED_RHD" 1 "RCM_DRIVER_ORIENTATION_MATCHED_LHD" 3 "RCM_DRIVER_ORIENTATION_MISMATCH_DEFAULT_LHD" 0 "RCM_DRIVER_ORIENTATION_INIT_NOT_COMPLETE" ;
VAL_ 529 RCM_imuOffsetLearnState 0 "IMU_OFFSET_LEARNING_OFF" 2 "IMU_FAST_LEARNING_TIME" 1 "IMU_SLOW_LEARNING_DISTANCE" 3 "IMU_OFFSETS_UNABLE_TO_LEARN" ;
VAL_ 529 RCM_keepPowerReason 7 "RCM_INVALID_POWER_OFF_REQUEST" 4 "RCM_EDR_UPLOADING" 6 "RCM_INITIALIZATION_PHASE" 1 "RCM_IN_IDLE_MODE" 2 "RCM_CRASH_ALGO_ACTIVE" 5 "RCM_CANNOT_POWER_DOWN" 0 "RCM_NO_KEEP_POWER_REQUEST" 3 "RCM_EDR_STORING_TO_EEPROM" ;
VAL_ 529 RCM_edr2State 1 "RCM_EDR_STORED" 0 "RCM_EDR_EMPTY" 3 "RCM_EDR_UNAVAILABLE" 2 "RCM_EDR_LOCKED" ;
VAL_ 529 RCM_edr1State 1 "RCM_EDR_STORED" 0 "RCM_EDR_EMPTY" 3 "RCM_EDR_UNAVAILABLE" 2 "RCM_EDR_LOCKED" ;
VAL_ 529 RCM_seatTrackPositionPass 3 "SNA" 0 "RCM_SEAT_POSITION_NEAR" 1 "RCM_SEAT_POSITION_FAR" 2 "RCM_SEAT_POSITION_FAULTED" ;
VAL_ 529 RCM_seatTrackPositionDrvr 3 "SNA" 0 "RCM_SEAT_POSITION_NEAR" 1 "RCM_SEAT_POSITION_FAR" 2 "RCM_SEAT_POSITION_FAULTED" ;
VAL_ 529 RCM_vinLearnFlag 0 "RCM_VIN_NOT_STORED" 3 "SNA" 2 "RCM_VIN_STORED_MISMATCH" 1 "RCM_VIN_STORED" ;
VAL_ 529 RCM_alrSwitchStatus 3 "SNA" 0 "RCM_ALR_NOT_ENGAGED" 1 "RCM_ALR_ENGAGED" 2 "RCM_ALR_FAULTED" ;
VAL_ 529 RCM_airbagCutoffStatus 3 "SNA" 1 "RCM_PASSENGER_AIRBAG_DISABLED" 0 "RCM_PASSENGER_AIRBAG_ENABLED" ;
VAL_ 529 RCM_passAirbagIndicatorRequest 3 "SNA" 0 "RCM_PASSENGER_AIRBAG_INDICATOR_ON" 1 "RCM_PASSENGER_AIRBAG_INDICATOR_OFF" ;
VAL_ 529 RCM_warningIndicatorState 3 "SNA" 0 "RCM_WARNING_INDICATOR_OFF" 1 "RCM_WARNING_INDICATOR_ON" ;
VAL_ 529 RCM_armStatus 3 "SNA" 2 "ARMED_WITH_NOFIRE_CAL" 1 "RCM_ARMED" 0 "RCM_UNARMED" ;
VAL_ 905 DAS_longCollisionWarning 7 "FCM_LONG_COLLISION_WARNING_VEHICLE_CUTIN" 0 "FCM_LONG_COLLISION_WARNING_NONE" 4 "FCM_LONG_COLLISION_WARNING_STOPSIGN_STOPLINE" 9 "FCM_LONG_COLLISION_WARNING_VEHICLE_MCVL2" 15 "FCM_LONG_COLLISION_WARNING_SNA" 8 "FCM_LONG_COLLISION_WARNING_VEHICLE_MCVL" 5 "FCM_LONG_COLLISION_WARNING_TFL_STOPLINE" 2 "FCM_LONG_COLLISION_WARNING_PEDESTRIAN" 12 "FCM_LONG_COLLISION_WARNING_VEHICLE_CIPV2" 6 "FCM_LONG_COLLISION_WARNING_VEHICLE_CIPV" 10 "FCM_LONG_COLLISION_WARNING_VEHICLE_MCVR" 3 "FCM_LONG_COLLISION_WARNING_IPSO" 1 "FCM_LONG_COLLISION_WARNING_VEHICLE_UNKNOWN" 11 "FCM_LONG_COLLISION_WARNING_VEHICLE_MCVR2" ;
VAL_ 905 DAS_ppOffsetDesiredRamp 128 "PP_NO_OFFSET" ;
VAL_ 905 DAS_driverInteractionLevel 0 "DRIVER_INTERACTING" 1 "DRIVER_NOT_INTERACTING" 2 "CONTINUED_DRIVER_NOT_INTERACTING" ;
VAL_ 905 DAS_robState 0 "ROB_STATE_INHIBITED" 2 "ROB_STATE_ACTIVE" 3 "ROB_STATE_MAPLESS" 1 "ROB_STATE_MEASURE" ;
VAL_ 905 DAS_radarTelemetry 0 "RADAR_TELEMETRY_IDLE" 1 "RADAR_TELEMETRY_NORMAL" 2 "RADAR_TELEMETRY_URGENT" ;
VAL_ 905 DAS_lssState 7 "LSS_STATE_OFF" 1 "LSS_STATE_LDW" 4 "LSS_STATE_MONITOR" 2 "LSS_STATE_LKA" 3 "LSS_STATE_ELK" 0 "LSS_STATE_FAULT" 5 "LSS_STATE_BLINDSPOT" 6 "LSS_STATE_ABORT" ;
VAL_ 905 DAS_ACC_report 12 "ACC_REPORT_LC_EXTERNAL_STATE_ABORTING" 17 "ACC_REPORT_TARGET_MCP" 11 "ACC_REPORT_LC_HANDS_ON_REQD_STRUCK_OUT" 19 "ACC_REPORT_MCVLR_DPP" 1 "ACC_REPORT_TARGET_CIPV" 15 "ACC_REPORT_RADAR_OBJ_ONE" 16 "ACC_REPORT_RADAR_OBJ_TWO" 14 "ACC_REPORT_LC_EXTERNAL_STATE_ACTIVE_RESTRICTED" 4 "ACC_REPORT_TARGET_MCVR" 20 "ACC_REPORT_MCVLR_IN_PATH" 10 "ACC_REPORT_CSA" 5 "ACC_REPORT_TARGET_CUTIN" 9 "ACC_REPORT_TARGET_TYPE_FAULT" 7 "ACC_REPORT_TARGET_TYPE_TRAFFIC_LIGHT" 6 "ACC_REPORT_TARGET_TYPE_STOP_SIGN" 24 "ACC_REPORT_BEHAVIOR_REPORT" 18 "ACC_REPORT_FLEET_SPEEDS" 2 "ACC_REPORT_TARGET_IN_FRONT_OF_CIPV" 23 "ACC_REPORT_CAMERA_ONLY" 3 "ACC_REPORT_TARGET_MCVL" 22 "ACC_REPORT_RADAR_OBJ_FIVE" 0 "ACC_REPORT_TARGET_NONE" 8 "ACC_REPORT_TARGET_TYPE_IPSO" 21 "ACC_REPORT_CIPV_CUTTING_OUT" 13 "ACC_REPORT_LC_EXTERNAL_STATE_ABORTED" ;
VAL_ 905 DAS_pmmCameraFaultReason 1 "PMM_CAMERA_BLOCKED_FRONT" 2 "PMM_CAMERA_INVALID_MIA" 0 "PMM_CAMERA_NO_FAULT" ;
VAL_ 905 DAS_pmmSysFaultReason 4 "PMM_FAULT_STEERING_ANGLE_RATE" 6 "PMM_FAULT_ROAD_TYPE" 5 "PMM_FAULT_DISABLED_BY_USER" 0 "PMM_FAULT_NONE" 1 "PMM_FAULT_DAS_DISABLED" 3 "PMM_FAULT_DI_FAULT" 2 "PMM_FAULT_SPEED" 7 "PMM_FAULT_BRAKE_PEDAL_INHIBIT" ;
VAL_ 905 DAS_pmmRadarFaultReason 2 "PMM_RADAR_INVALID_MIA" 1 "PMM_RADAR_BLOCKED_FRONT" 0 "PMM_RADAR_NO_FAULT" ;
VAL_ 905 DAS_pmmUltrasonicsFaultReason 2 "PMM_ULTRASONICS_BLOCKED_REAR" 0 "PMM_ULTRASONICS_NO_FAULT" 1 "PMM_ULTRASONICS_BLOCKED_FRONT" 3 "PMM_ULTRASONICS_BLOCKED_BOTH" 4 "PMM_ULTRASONICS_INVALID_MIA" ;
VAL_ 905 DAS_activationFailureStatus 0 "LC_ACTIVATION_IDLE" 2 "LC_ACTIVATION_FAILED_2" 1 "LC_ACTIVATION_FAILED_1" ;
VAL_ 905 DAS_pmmLoggingRequest 0 "FALSE" 1 "TRUE" ;
VAL_ 905 DAS_pmmObstacleSeverity 5 "PMM_CRASH_FRONT" 0 "PMM_NONE" 2 "PMM_IMMINENT_FRONT" 4 "PMM_CRASH_REAR" 1 "PMM_IMMINENT_REAR" 6 "PMM_ACCEL_LIMIT" 7 "PMM_SNA" 3 "PMM_BRAKE_REQUEST" ;
VAL_ 905 DAS_accSpeedLimit 1023 "SNA" 0 "NONE" ;
VAL_ 805 ESP_infoVehicleVariant 6 "MODEL_3_VARIANT_06" 1 "MODEL_3_VARIANT_01" 7 "MODEL_3_VARIANT_07" 2 "MODEL_3_VARIANT_02" 8 "MODEL_3_VARIANT_08" 3 "MODEL_3_VARIANT_03" 9 "MODEL_3_VARIANT_09" 4 "MODEL_3_VARIANT_04" 5 "MODEL_3_VARIANT_05" ;
VAL_ 805 ESP_infoBuildType 1 "INFO_PLATFORM_BUILD" 3 "INFO_TRACEABLE_CI_BUILD" 4 "INFO_MFG_BUILD" 2 "INFO_LOCAL_BUILD" 0 "INFO_UNKNOWN_BUILD" ;
VAL_ 805 ESP_infoIndex 25 "INFO_PACKAGE_PN_1_7" 30 "INFO_PACKAGE_SN_8_14" 27 "INFO_PACKAGE_PN_15_20" 0 "INFO_DEPRECATED_0" 29 "INFO_PACKAGE_SN_1_7" 10 "INFO_BUILD_HWID_COMPONENTID" 14 "INFO_BOOTLOADER_SVN" 31 "INFO_SUBCOMPONENT_GITHASH" 19 "INFO_VERSION_DEPRECATED" 7 "INFO_DEPRECATED_7" 255 "INFO_END" 9 "INFO_DEPRECATED_9" 6 "INFO_DEPRECATED_6" 20 "INFO_UDS_PROTOCOL_BOOTCRC" 3 "INFO_DEPRECATED_3" 22 "INFO_VARIANTCRC" 17 "INFO_APP_GITHASH" 8 "INFO_DEPRECATED_8" 26 "INFO_PACKAGE_PN_8_14" 5 "INFO_DEPRECATED_5" 16 "INFO_SUBCOMPONENT" 13 "INFO_APP_CRC" 2 "INFO_DEPRECATED_2" 4 "INFO_DEPRECATED_4" 15 "INFO_BOOTLOADER_CRC" 1 "INFO_DEPRECATED_1" 11 "INFO_PCBAID_ASSYID_USAGEID" 18 "INFO_BOOTLOADER_GITHASH" ;
VAL_ 879 TPMS_localisationStatus 3 "PASSED" 1 "ONGOING" 2 "STOPPED" 0 "FAILED" ;
VAL_ 879 TPMS_learningStatus 3 "PASSED" 1 "ONGOING" 2 "STOPPED" 0 "FAILED" ;
VAL_ 264 DI_axleSpeed -32768 "SNA" ;
VAL_ 264 DI_torqueActual -4096 "SNA" ;
VAL_ 264 DI_torqueCommand -4096 "SNA" ;
VAL_ 1029 GTW_vinIndex 16 "Mux16" 17 "Mux17" 18 "Mux18" ;
VAL_ 79 UI_gpsAccuracy 127 "SNA" ;
VAL_ 601 APP_watchdogState 1 "AP_WDOG_STATE_DEGRADED" 7 "AP_WDOG_STATE_SNA" 3 "AP_WDOG_STATE_HEALTHY" 0 "AP_WDOG_STATE_UNKNOWN" 2 "AP_WDOG_STATE_CRITICAL" ;
VAL_ 1548 DAS_TR_Obj00_MovingState 3 "RADAR_MOVESTATE_STANDING" 1 "RADAR_MOVESTATE_MOVING" 0 "RADAR_MOVESTATE_INDETERMINATE" 2 "RADAR_MOVESTATE_STOPPED" ;
VAL_ 1548 DAS_TR_Obj00_Class 2 "RADAR_CLASS_MOVING_TWO_WHEEL_VEHICLE" 1 "RADAR_CLASS_MOVING_FOUR_WHEEL_VEHICLE" 0 "RADAR_CLASS_UNKNOWN" 4 "RADAR_CLASS_CONSTRUCTION_ELEMENT" 3 "RADAR_CLASS_MOVING_PEDESTRIAN" ;
VAL_ 1548 DAS_TR_ObjIndex 26 "Mux26" 4 "Mux4" 16 "Mux16" 2 "Mux2" 20 "Mux20" 5 "Mux5" 27 "Mux27" 11 "Mux11" 8 "Mux8" 21 "Mux21" 3 "Mux3" 24 "Mux24" 6 "Mux6" 9 "Mux9" 10 "Mux10" 15 "Mux15" 7 "Mux7" 25 "Mux25" 31 "Mux31" 28 "Mux28" 13 "Mux13" 14 "Mux14" 22 "Mux22" 19 "Mux19" 0 "Mux0" 12 "Mux12" 30 "Mux30" 29 "Mux29" 17 "Mux17" 23 "Mux23" 18 "Mux18" 1 "Mux1" ;
VAL_ 257 RCM_pitchRateQF 0 "INIT" 3 "FAULTED" 2 "TEMP_INVALID" 1 "VALID" ;
VAL_ 257 RCM_yawRateQF 0 "FAULTED" 1 "NOT_FAULTED" ;
VAL_ 257 RCM_rollRateQF 0 "INIT" 3 "FAULTED" 2 "TEMP_INVALID" 1 "VALID" ;
VAL_ 257 RCM_rollRate -16384 "SNA" ;
VAL_ 257 RCM_pitchRate -16384 "SNA" ;
VAL_ 257 RCM_yawRate -32768 "SNA" ;
VAL_ 1425 EPAS3S_alertState 0 "ALERT_CLEARED" 1 "ALERT_SET" ;
VAL_ 1425 EPAS3S_alertID 31 "EPAS3S_a031_abnormalShutdown" 85 "EPAS3S_a085_canBusOff" 11 "EPAS3S_a011_currentSensError" 95 "EPAS3S_a095_espWsStatus" 123 "EPAS3S_a123_combEcu2StatFail" 77 "EPAS3S_a077_highSideFetError" 91 "EPAS3S_a091_espWsCsError" 106 "EPAS3S_a106_vcFrontTempMia" 41 "EPAS3S_a041_motPos1tempError" 59 "EPAS3S_a059_battOvReduced" 14 "EPAS3S_a014_gateDriveTxError" 99 "EPAS3S_a099_yawRateStatus" 120 "EPAS3S_a120_pvtEcuStatCntError" 51 "EPAS3S_a051_mcuSupError" 34 "EPAS3S_a034_vRegError" 40 "EPAS3S_a040_motPos1LogicError" 63 "EPAS3S_a063_dampCorrError" 125 "EPAS3S_a125_trqSensTrimOutRange" 36 "EPAS3S_a036_vbbSupplyOv" 42 "EPAS3S_a042_motPos2ParityError" 111 "EPAS3S_a111_sasCntError" 52 "EPAS3S_a052_intWatchdogError" 4 "EPAS3S_a004_trqSens1Eeprom" 81 "EPAS3S_a081_coggCompError" 72 "EPAS3S_a072_motFeedFwdError" 101 "EPAS3S_a101_diCntError" 21 "EPAS3S_a021_phaseWlowUv" 107 "EPAS3S_a107_uiTuneReqMia" 32 "EPAS3S_a032_vRegOutputUv" 56 "EPAS3S_a056_battUv" 121 "EPAS3S_a121_pvtEcuStatCrcError" 10 "EPAS3S_a010_trqSensCalError" 54 "EPAS3S_a054_memoryProtectError" 61 "EPAS3S_a061_bridgeUv" 25 "EPAS3S_a025_phaseVlowOv" 26 "EPAS3S_a026_phaseWhighOv" 74 "EPAS3S_a074_overHeatProtect" 96 "EPAS3S_a096_rcmMia" 23 "EPAS3S_a023_phaseUlowOv" 122 "EPAS3S_a122_olpActive" 19 "EPAS3S_a019_phaseVlowUv" 5 "EPAS3S_a005_sent2Mia" 116 "EPAS3S_a116_ecuStatCntError" 89 "EPAS3S_a089_espWsMia" 76 "EPAS3S_a076_tempSensOutofRange" 88 "EPAS3S_a088_dasCsError" 71 "EPAS3S_a071_vehSpdCorrError" 22 "EPAS3S_a022_phaseUhighOv" 18 "EPAS3S_a018_phaseVhighUv" 98 "EPAS3S_a098_rcmCsError" 92 "EPAS3S_a092_espWrMia" 47 "EPAS3S_a047_motPosCorrError" 130 "EPAS3S_a130_sasOffsetNotCal" 131 "EPAS3S_a131_phaseFeedbackError" 86 "EPAS3S_a086_dasMia" 83 "EPAS3S_a083_crcMismatch" 33 "EPAS3S_a033_vRegOutputOv" 9 "EPAS3S_a009_sentDiff" 104 "EPAS3S_a104_vcFrontCntError" 75 "EPAS3S_a075_fspPwrCut" 108 "EPAS3S_a108_uiTuneReqCntError" 84 "EPAS3S_a084_eacCancelled" 78 "EPAS3S_a078_phaseDisconnectError" 24 "EPAS3S_a024_phaseVhighOv" 35 "EPAS3S_a035_vbbSupplyUv" 82 "EPAS3S_a082_polarityCalError" 65 "EPAS3S_a065_trqTarCorrError" 45 "EPAS3S_a045_motPos2LogicError" 20 "EPAS3S_a020_phaseWhighUv" 60 "EPAS3S_a060_battBridgeDiff" 127 "EPAS3S_a127_apsCntError" 15 "EPAS3S_a015_gateDriveEeprom" 7 "EPAS3S_a007_trqSens2Supply" 79 "EPAS3S_a079_backupCurrentPlaus" 126 "EPAS3S_a126_apsMia" 124 "EPAS3S_a124_tempSensStuckInRange" 53 "EPAS3S_a053_extWatchdogError" 90 "EPAS3S_a090_espWsCntError" 67 "EPAS3S_a067_yawDampCorrError" 44 "EPAS3S_a044_motPos2MagnetMia" 115 "EPAS3S_a115_ecuStatMia" 100 "EPAS3S_a100_diMia" 1 "EPAS3S_a001_sent1Mia" 13 "EPAS3S_a013_gateDriveError" 128 "EPAS3S_a128_apsCsError" 43 "EPAS3S_a043_motPos2Uv" 55 "EPAS3S_a055_floatPointError" 68 "EPAS3S_a068_hystCorrError" 117 "EPAS3S_a117_ecuStatCrcError" 110 "EPAS3S_a110_sasMia" 69 "EPAS3S_a069_eacCorrError" 103 "EPAS3S_a103_vcFrontMia" 73 "EPAS3S_a073_motParEstError" 97 "EPAS3S_a097_rcmCntError" 129 "EPAS3S_a129_combEcu1StatFail" 17 "EPAS3S_a017_phaseUlowUv" 38 "EPAS3S_a038_motPos1Uv" 112 "EPAS3S_a112_sasCsError" 94 "EPAS3S_a094_espWrCsError" 66 "EPAS3S_a066_returnCorrError" 118 "EPAS3S_a118_privateBusOff" 30 "EPAS3S_a030_phaseWbootUv" 57 "EPAS3S_a057_battUvReduced" 102 "EPAS3S_a102_diCsError" 8 "EPAS3S_a008_trqSens2Eeprom" 113 "EPAS3S_a113_sasStatusError" 46 "EPAS3S_a046_motPos2tempError" 49 "EPAS3S_a049_piCtrlError" 3 "EPAS3S_a003_trqSens1Supply" 50 "EPAS3S_a050_mcuSmuError" 28 "EPAS3S_a028_phaseUbootUv" 93 "EPAS3S_a093_espWrCntError" 48 "EPAS3S_a048_motPosCalError" 64 "EPAS3S_a064_phaseCompCorrError" 6 "EPAS3S_a006_sent2Error" 27 "EPAS3S_a027_phaseWlowOv" 37 "EPAS3S_a037_motPos1ParityError" 80 "EPAS3S_a080_ecuInitArbError" 39 "EPAS3S_a039_motPos1MagnetMia" 109 "EPAS3S_a109_uiTuneReqCsError" 16 "EPAS3S_a016_phaseUhighUv" 70 "EPAS3S_a070_hodCorrError" 105 "EPAS3S_a105_vcFrontCsError" 87 "EPAS3S_a087_dasCntError" 62 "EPAS3S_a062_assistCorrError" 2 "EPAS3S_a002_sent1Error" 58 "EPAS3S_a058_battOv" 119 "EPAS3S_a119_pvtEcuStatMia" 29 "EPAS3S_a029_phaseVbootUv" 114 "EPAS3S_a114_gtwConfigMia" 12 "EPAS3S_a012_currentSensCalError" 0 "EPAS3S_ALERT_DO_NOT_USE_ZERO" ;
VAL_ 1313 TAS_firmwareType 0 "APPLICATION" 2 "BOOTLOADER_UPDATER" 1 "BOOTLOADER" ;
VAL_ 849 RCM_infoBuildType 1 "INFO_PLATFORM_BUILD" 3 "INFO_TRACEABLE_CI_BUILD" 4 "INFO_MFG_BUILD" 2 "INFO_LOCAL_BUILD" 0 "INFO_UNKNOWN_BUILD" ;
VAL_ 849 RCM_infoIndex 25 "INFO_PACKAGE_PN_1_7" 30 "INFO_PACKAGE_SN_8_14" 27 "INFO_PACKAGE_PN_15_20" 0 "INFO_DEPRECATED_0" 29 "INFO_PACKAGE_SN_1_7" 10 "INFO_BUILD_HWID_COMPONENTID" 14 "INFO_BOOTLOADER_SVN" 31 "INFO_SUBCOMPONENT_GITHASH" 19 "INFO_VERSION_DEPRECATED" 7 "INFO_DEPRECATED_7" 255 "INFO_END" 9 "INFO_DEPRECATED_9" 6 "INFO_DEPRECATED_6" 20 "INFO_UDS_PROTOCOL_BOOTCRC" 3 "INFO_DEPRECATED_3" 22 "INFO_VARIANTCRC" 17 "INFO_APP_GITHASH" 8 "INFO_DEPRECATED_8" 26 "INFO_PACKAGE_PN_8_14" 5 "INFO_DEPRECATED_5" 16 "INFO_SUBCOMPONENT" 13 "INFO_APP_CRC" 2 "INFO_DEPRECATED_2" 4 "INFO_DEPRECATED_4" 15 "INFO_BOOTLOADER_CRC" 1 "INFO_DEPRECATED_1" 11 "INFO_PCBAID_ASSYID_USAGEID" 18 "INFO_BOOTLOADER_GITHASH" ;
VAL_ 799 TPMS_temperatureRR 255 "SNA" ;
VAL_ 799 TPMS_pressureRR 255 "SNA" ;
VAL_ 799 TPMS_temperatureRL 255 "SNA" ;
VAL_ 799 TPMS_pressureRL 255 "SNA" ;
VAL_ 799 TPMS_temperatureFR 255 "SNA" ;
VAL_ 799 TPMS_pressureFR 255 "SNA" ;
VAL_ 799 TPMS_temperatureFL 255 "SNA" ;
VAL_ 799 TPMS_pressureFL 255 "SNA" ;
VAL_ 525 TAS_limpHomeMode 4 "LIMP_HOME_MODE_40" 1 "LIMP_HOME_MODE_10" 0 "LIMP_HOME_MODE_0" 2 "LIMP_HOME_MODE_20" 3 "LIMP_HOME_MODE_30" ;
VAL_ 525 TAS_targetLevel 3 "LOW" 2 "STANDARD" 0 "VERY_HIGH" 4 "VERY_LOW" 1 "HIGH" ;
VAL_ 525 TAS_currentLevel 3 "LOW" 2 "STANDARD" 0 "VERY_HIGH" 4 "VERY_LOW" 1 "HIGH" ;
VAL_ 525 TAS_filterMode 6 "MODE_DRIVE" 2 "MODE_CALIBRATE" 7 "MODE_STOPPING" 4 "MODE_READY" 5 "MODE_LOADING" 3 "MODE_TEST" 0 "MODE_NONE" 1 "MODE_INIT" ;
VAL_ 525 TAS_runMode 3 "RUN_MODE_ASSEMBLY" 2 "RUN_MODE_SERVICE" 0 "RUN_MODE_INIT" 1 "RUN_MODE_SYSTEM_CHECK" 6 "RUN_MODE_LOW_POWER" 5 "RUN_MODE_NORMAL" 4 "RUN_MODE_DAN" ;
VAL_ 525 TAS_pressureReservoir 255 "SNA" ;
VAL_ 525 TAS_pressureGallery 255 "SNA" ;
VAL_ 525 TAS_levelingState 5 "LEVELING_STATE_COMPRESSOR_PREFILL_GALLERY" 1 "LEVELING_STATE_READ_P_RESERVOIR" 2 "LEVELING_STATE_MANUAL_SPRING_CONTROL" 7 "LEVELING_STATE_FILL_SPRING_FROM_COMPRESSOR" 3 "LEVELING_STATE_EXHAUST_GALLERY" 11 "LEVELING_STATE_LOWER_SPRING" 9 "LEVELING_STATE_FILL_SPRING_FROM_RESERVOIR" 12 "LEVELING_STATE_EMPTY_RESERVOIR" 0 "LEVELING_STATE_IDLE" 6 "LEVELING_STATE_FILL_RESERVOIR_FROM_COMPRESSOR" 10 "LEVELING_STATE_FILL_SPRING_RESERVOIR_FROM_COMPRESSOR" 8 "LEVELING_STATE_FILL_SPRING_FROM_BOOST" 4 "LEVELING_STATE_COMPRESSOR_RAMPUP" ;
VAL_ 921 DAS_autoLaneChangeState 5 "ALC_UNAVAILABLE_VEHICLE_SPEED" 17 "ALC_ABORT_POOR_VIEW_RANGE" 23 "ALC_BLOCKED_VEH_TTC_AND_USS_L" 0 "ALC_UNAVAILABLE_DISABLED" 26 "ALC_BLOCKED_LANE_TYPE_L" 29 "ALC_ABORT_TIMEOUT" 9 "ALC_IN_PROGRESS_L" 4 "ALC_UNAVAILABLE_EXITING_HIGHWAY" 22 "ALC_BLOCKED_VEH_TTC_L" 12 "ALC_WAITING_FOR_SIDE_OBST_TO_PASS_R" 18 "ALC_ABORT_LC_HEALTH_BAD" 28 "ALC_WAITING_HANDS_ON" 8 "ALC_AVAILABLE_BOTH" 11 "ALC_WAITING_FOR_SIDE_OBST_TO_PASS_L" 3 "ALC_UNAVAILABLE_TP_FOLLOW" 2 "ALC_UNAVAILABLE_SONICS_INVALID" 21 "ALC_UNAVAILABLE_SOLID_LANE_LINE" 24 "ALC_BLOCKED_VEH_TTC_R" 1 "ALC_UNAVAILABLE_NO_LANES" 25 "ALC_BLOCKED_VEH_TTC_AND_USS_R" 30 "ALC_ABORT_MISSION_PLAN_INVALID" 27 "ALC_BLOCKED_LANE_TYPE_R" 19 "ALC_ABORT_BLINKER_TURNED_OFF" 31 "ALC_SNA" 13 "ALC_WAITING_FOR_FWD_OBST_TO_PASS_L" 16 "ALC_ABORT_SIDE_OBSTACLE_PRESENT_R" 6 "ALC_AVAILABLE_ONLY_L" 20 "ALC_ABORT_OTHER_REASON" 15 "ALC_ABORT_SIDE_OBSTACLE_PRESENT_L" 7 "ALC_AVAILABLE_ONLY_R" 14 "ALC_WAITING_FOR_FWD_OBST_TO_PASS_R" 10 "ALC_IN_PROGRESS_R" ;
VAL_ 921 DAS_autopilotHandsOnState 8 "LC_HANDS_ON_SUSPENDED" 15 "LC_HANDS_ON_SNA" 7 "LC_HANDS_ON_REQD_STRUCK_OUT" 3 "LC_HANDS_ON_REQD_VISUAL" 4 "LC_HANDS_ON_REQD_CHIME_1" 6 "LC_HANDS_ON_REQD_SLOWING" 1 "LC_HANDS_ON_REQD_DETECTED" 2 "LC_HANDS_ON_REQD_NOT_DETECTED" 5 "LC_HANDS_ON_REQD_CHIME_2" 0 "LC_HANDS_ON_NOT_REQD" ;
VAL_ 921 DAS_fleetSpeedState 0 "FLEETSPEED_UNAVAILABLE" 1 "FLEETSPEED_AVAILABLE" 2 "FLEETSPEED_ACTIVE" 3 "FLEETSPEED_HOLD" ;
VAL_ 921 DAS_laneDepartureWarning 5 "SNA" 0 "NONE" 2 "RIGHT_WARNING" 4 "RIGHT_WARNING_SEVERE" 3 "LEFT_WARNING_SEVERE" 1 "LEFT_WARNING" ;
VAL_ 921 DAS_csaState 1 "CSA_EXTERNAL_STATE_AVAILABLE" 3 "CSA_EXTERNAL_STATE_HOLD" 2 "CSA_EXTERNAL_STATE_ENABLE" 0 "CSA_EXTERNAL_STATE_UNAVAILABLE" ;
VAL_ 921 DAS_sideCollisionInhibit 0 "NO_INHIBIT" 1 "INHIBIT" ;
VAL_ 921 DAS_sideCollisionWarning 0 "NONE" 2 "WARN_RIGHT" 1 "WARN_LEFT" 3 "WARN_LEFT_RIGHT" ;
VAL_ 921 DAS_sideCollisionAvoid 3 "SNA" 0 "NONE" 1 "AVOID_LEFT" 2 "AVOID_RIGHT" ;
VAL_ 921 DAS_autoparkReady 0 "AUTOPARK_UNAVAILABLE" 1 "AUTOPARK_READY" ;
VAL_ 921 DAS_forwardCollisionWarning 3 "SNA" 0 "NONE" 1 "FORWARD_COLLISION_WARNING" ;
VAL_ 921 DAS_heaterState 0 "HEATER_OFF_SNA" 1 "HEATER_ON" ;
VAL_ 921 DAS_visionOnlySpeedLimit 31 "NONE" 0 "UNKNOWN_SNA" ;
VAL_ 921 DAS_suppressSpeedWarning 1 "Suppress_Speed_Warning" 0 "Do_Not_Suppress" ;
VAL_ 921 DAS_fusedSpeedLimit 31 "NONE" 0 "UNKNOWN_SNA" ;
VAL_ 921 DAS_blindSpotRearRight 3 "SNA" 0 "NO_WARNING" 1 "WARNING_LEVEL_1" 2 "WARNING_LEVEL_2" ;
VAL_ 921 DAS_blindSpotRearLeft 3 "SNA" 0 "NO_WARNING" 1 "WARNING_LEVEL_1" 2 "WARNING_LEVEL_2" ;
VAL_ 921 DAS_autopilotState 15 "SNA" 8 "ABORTING" 3 "ACTIVE_NOMINAL" 0 "DISABLED" 4 "ACTIVE_RESTRICTED" 5 "ACTIVE_NAV" 14 "FAULT" 1 "UNAVAILABLE" 9 "ABORTED" 2 "AVAILABLE" ;
VAL_ 558 PARK_sdiSensor12RawDistData 511 "SNA" 1 "NEAR_DETECTION" 500 "NO_OBJECT_DETECTED" 0 "BLOCKED" ;
VAL_ 558 PARK_sdiSensor11RawDistData 511 "SNA" 1 "NEAR_DETECTION" 500 "NO_OBJECT_DETECTED" 0 "BLOCKED" ;
VAL_ 558 PARK_sdiSensor10RawDistData 511 "SNA" 1 "NEAR_DETECTION" 500 "NO_OBJECT_DETECTED" 0 "BLOCKED" ;
VAL_ 558 PARK_sdiSensor9RawDistData 511 "SNA" 1 "NEAR_DETECTION" 500 "NO_OBJECT_DETECTED" 0 "BLOCKED" ;
VAL_ 558 PARK_sdiSensor8RawDistData 511 "SNA" 1 "NEAR_DETECTION" 500 "NO_OBJECT_DETECTED" 0 "BLOCKED" ;
VAL_ 558 PARK_sdiSensor7RawDistData 511 "SNA" 1 "NEAR_DETECTION" 500 "NO_OBJECT_DETECTED" 0 "BLOCKED" ;
VAL_ 913 EPAS3S_matrixIndex 2 "EPAS3S_AlertMatrix2" 1 "EPAS3S_AlertMatrix1" 0 "EPAS3S_AlertMatrix0" ;
VAL_ 1856 TPMS_sensorIDIndex 2 "Mux2" 3 "Mux3" 0 "Mux0" 1 "Mux1" ;
VAL_ 771 OCS1P_classificationHoldState 1 "OCCUPANCY_HOLD_BASIC" 2 "OCCUPANCY_HOLD_EXTERNAL" 0 "OCCUPANCY_HOLD_OFF" 3 "OCCUPANCY_HOLD_FAULT" ;
VAL_ 771 OCS1P_occupantClassificationSelf 4 "OCCUPANT_CLASSIFICATION_INIT" 2 "OCCUPANT_CLASSIFICATION_OCCUPIED_ALLOW_SMALL" 3 "OCCUPANT_CLASSIFICATION_OCCUPIED_ALLOW_LARGE" 0 "OCCUPANT_CLASSIFICATION_EMPTY" 255 "OCCUPANT_CLASSIFICATION_SNA" 1 "OCCUPANT_CLASSIFICATION_OCCUPIED_INHIBIT" ;
VAL_ 771 OCS1P_occupantClassificationRaw 4 "OCCUPANT_CLASSIFICATION_INIT" 2 "OCCUPANT_CLASSIFICATION_OCCUPIED_ALLOW_SMALL" 3 "OCCUPANT_CLASSIFICATION_OCCUPIED_ALLOW_LARGE" 0 "OCCUPANT_CLASSIFICATION_EMPTY" 255 "OCCUPANT_CLASSIFICATION_SNA" 1 "OCCUPANT_CLASSIFICATION_OCCUPIED_INHIBIT" ;
VAL_ 771 OCS1P_occupiedState 0 "OCCUPIED_STATE_UNOCCUPIED" 3 "OCCUPIED_STATE_SNA" 1 "OCCUPIED_STATE_OCCUPIED" ;
VAL_ 771 OCS1P_occupantClassificationQF 1 "OCCUPANT_CLASSIFICATION_NOT_FAULTED" 0 "OCCUPANT_CLASSIFICATION_FAULTED" ;
VAL_ 771 OCS1P_occupantClassification 4 "OCCUPANT_CLASSIFICATION_INIT" 2 "OCCUPANT_CLASSIFICATION_OCCUPIED_ALLOW_SMALL" 3 "OCCUPANT_CLASSIFICATION_OCCUPIED_ALLOW_LARGE" 0 "OCCUPANT_CLASSIFICATION_EMPTY" 255 "OCCUPANT_CLASSIFICATION_SNA" 1 "OCCUPANT_CLASSIFICATION_OCCUPIED_INHIBIT" ;
VAL_ 970 APS_gpsWheelsOffMotionDetected 1 "APS_GPS_MOTION_DETECTED_ON" 0 "APS_GPS_MOTION_DETECTED_OFF" ;
VAL_ 970 APS_gpsTransportModeState 1 "APS_GPS_TRANSPORT_MODE_ON" 0 "APS_GPS_TRANSPORT_MODE_OFF" ;
VAL_ 325 ESP_brakeTorqueTarget 8191 "SNA" ;
VAL_ 325 ESP_ebrStatus 1 "EBR_IS_AVAILABLE" 0 "EBR_IS_NOT_AVAILABLE" 3 "EBR_COMMAND_INVALID" 2 "ACTUATING_DI_EBR" ;
VAL_ 325 ESP_ebrStandstillSkid 0 "NO_STANDSTILL_SKID" 1 "STANDSTILL_SKID_DETECTED" ;
VAL_ 325 ESP_btcTargetState 3 "SNA" 1 "BACKUP" 0 "OFF" 2 "ON" ;
VAL_ 325 ESP_ptcTargetState 3 "SNA" 1 "BACKUP" 0 "FAULT" 2 "ON" ;
VAL_ 325 ESP_cdpStatus 1 "CDP_IS_AVAILABLE" 3 "CDP_COMMAND_INVALID" 2 "ACTUATING_EPB_CDP" 0 "CDP_IS_NOT_AVAILABLE" ;
VAL_ 325 ESP_brakeApply 1 "BLS_ACTIVE" 0 "BLS_INACTIVE" ;
VAL_ 325 ESP_driverBrakeApply 1 "Not_Applied" 3 "Faulty_SNA" 2 "Driver_applying_brakes" 0 "NotInit_orOff" ;
VAL_ 325 ESP_brakeDiscWipingActive 0 "BDW_INACTIVE" 1 "BDW_ACTIVE" ;
VAL_ 325 ESP_steeringAngleQF 1 "IN_SPEC" 0 "UNDEFINABLE_ACCURACY" ;
VAL_ 325 ESP_yawRateQF 1 "IN_SPEC" 0 "UNDEFINABLE_ACCURACY" ;
VAL_ 325 ESP_lateralAccelQF 1 "IN_SPEC" 0 "UNDEFINABLE_ACCURACY" ;
VAL_ 325 ESP_longitudinalAccelQF 1 "IN_SPEC" 0 "UNDEFINABLE_ACCURACY" ;
VAL_ 325 ESP_absBrakeEvent2 1 "ABS_EVENT_ACTIVE_FRONT_REAR" 3 "ABS_EVENT_ACTIVE_REAR" 2 "ABS_EVENT_ACTIVE_FRONT" 0 "ABS_EVENT_NOT_ACTIVE" ;
VAL_ 325 ESP_brakeLamp 0 "LAMP_OFF" 1 "LAMP_ON" ;
VAL_ 325 ESP_espLampFlash 0 "ESP_LAMP_OFF" 1 "ESP_LAMP_FLASH" ;
VAL_ 325 ESP_espFaultLamp 0 "ESP_FAULT_LAMP_OFF" 1 "ESP_FAULT_LAMP_ON" ;
VAL_ 325 ESP_absFaultLamp 1 "ABS_FAULT_LAMP_ON" 0 "ABS_FAULT_LAMP_OFF" ;
VAL_ 325 ESP_ebdFaultLamp 1 "EBD_FAULT_LAMP_ON" 0 "EBD_FAULT_LAMP_OFF" ;
VAL_ 325 ESP_stabilityControlSts2 0 "INIT" 2 "ENGAGED" 3 "FAULTED" 1 "ON" ;
VAL_ 325 ESP_espModeActive 2 "ESP_MODE_02" 1 "ESP_MODE_01" 3 "ESP_MODE_03" 0 "ESP_MODE_00_NORMAL" ;
VAL_ 1329 RADC_infoBuildType 1 "INFO_PLATFORM_BUILD" 3 "INFO_TRACEABLE_CI_BUILD" 4 "INFO_MFG_BUILD" 2 "INFO_LOCAL_BUILD" 0 "INFO_UNKNOWN_BUILD" ;
VAL_ 1329 RADC_infoIndex 20 "Mux20" 11 "Mux11" 10 "Mux10" 13 "Mux13" 19 "Mux19" ;
VAL_ 723 UI_solarElevationAngle 127 "SNA" ;
VAL_ 723 UI_isSunUp 3 "SUN_SNA" 1 "SUN_UP" 0 "SUN_DOWN" ;
VAL_ 723 UI_solarAzimuthAngleCarRef 255 "SNA" ;
VAL_ 723 UI_solarAzimuthAngle -32768 "SNA" ;
VAL_ 1353 APP_buildType 0 "AP_BUILDTYPE_SIGNED" 3 "AP_BUILDTYPE_REPO" 1 "AP_BUILDTYPE_LOCAL" ;
VAL_ 1353 APP_infoIndex 0 "AP_BUILD_TYPE" 1 "FW_GITHASH" 2 "AP_GITHASH" ;
VAL_ 760 UI_userSpeedOffsetUnits 0 "MPH" 1 "KPH" ;
VAL_ 760 UI_mapSpeedLimitUnits 0 "MPH" 1 "KPH" ;
VAL_ 259 VCRIGHT_mirrorRecallState 5 "MIRROR_RECALL_STATE_RECALLING_STOPPED" 2 "MIRROR_RECALL_STATE_RECALLING_AXIS_2" 0 "MIRROR_RECALL_STATE_INIT" 3 "MIRROR_RECALL_STATE_RECALLING_COMPLETE" 4 "MIRROR_RECALL_STATE_RECALLING_FAILED" 1 "MIRROR_RECALL_STATE_RECALLING_AXIS_1" ;
VAL_ 259 VCRIGHT_trunkLatchStatus 8 "LATCH_FAULT" 2 "LATCH_CLOSED" 1 "LATCH_OPENED" 3 "LATCH_CLOSING" 7 "LATCH_DEFAULT" 4 "LATCH_OPENING" 5 "LATCH_AJAR" 6 "LATCH_TIMEOUT" 0 "LATCH_SNA" ;
VAL_ 259 VCRIGHT_mirrorFoldState 4 "MIRROR_FOLD_STATE_UNFOLDING" 1 "MIRROR_FOLD_STATE_FOLDED" 3 "MIRROR_FOLD_STATE_FOLDING" 0 "MIRROR_FOLD_STATE_UNKNOWN" 2 "MIRROR_FOLD_STATE_UNFOLDED" ;
VAL_ 259 VCRIGHT_mirrorState 3 "MIRROR_STATE_FOLD_UNFOLD" 1 "MIRROR_STATE_TILT_X" 0 "MIRROR_STATE_IDLE" 2 "MIRROR_STATE_TILT_Y" 4 "MIRROR_STATE_RECALL" ;
VAL_ 259 VCRIGHT_rearLatchStatus 8 "LATCH_FAULT" 2 "LATCH_CLOSED" 1 "LATCH_OPENED" 3 "LATCH_CLOSING" 7 "LATCH_DEFAULT" 4 "LATCH_OPENING" 5 "LATCH_AJAR" 6 "LATCH_TIMEOUT" 0 "LATCH_SNA" ;
VAL_ 259 VCRIGHT_frontLatchStatus 8 "LATCH_FAULT" 2 "LATCH_CLOSED" 1 "LATCH_OPENED" 3 "LATCH_CLOSING" 7 "LATCH_DEFAULT" 4 "LATCH_OPENING" 5 "LATCH_AJAR" 6 "LATCH_TIMEOUT" 0 "LATCH_SNA" ;
VAL_ 1519 TPMS_infoIndex 25 "INFO_PACKAGE_PN_1_7" 30 "INFO_PACKAGE_SN_8_14" 27 "INFO_PACKAGE_PN_15_20" 0 "INFO_DEPRECATED_0" 29 "INFO_PACKAGE_SN_1_7" 10 "INFO_BUILD_HWID_COMPONENTID" 14 "INFO_BOOTLOADER_SVN" 31 "INFO_SUBCOMPONENT_GITHASH" 19 "INFO_VERSION_DEPRECATED" 7 "INFO_DEPRECATED_7" 255 "INFO_END" 9 "INFO_DEPRECATED_9" 6 "INFO_DEPRECATED_6" 20 "INFO_UDS_PROTOCOL_BOOTCRC" 3 "INFO_DEPRECATED_3" 22 "INFO_VARIANTCRC" 17 "INFO_APP_GITHASH" 8 "INFO_DEPRECATED_8" 26 "INFO_PACKAGE_PN_8_14" 5 "INFO_DEPRECATED_5" 16 "INFO_SUBCOMPONENT" 13 "INFO_APP_CRC" 2 "INFO_DEPRECATED_2" 4 "INFO_DEPRECATED_4" 15 "INFO_BOOTLOADER_CRC" 1 "INFO_DEPRECATED_1" 11 "INFO_PCBAID_ASSYID_USAGEID" 18 "INFO_BOOTLOADER_GITHASH" ;
VAL_ 542 PARK_pscAngleActive 0 "INACTIVE" 1 "REQUEST_CONTROL" ;
VAL_ 542 PARK_pscManeuverDistance 2047 "SNA" ;
VAL_ 542 PARK_pscParkInstruction 7 "SNA" 2 "DRIVE_FORWARD" 0 "NO_MESSAGE" 1 "STOP" 3 "DRIVE_BACKWARD" 4 "ABORTED" 5 "EXPLORATION" ;
VAL_ 542 PARK_pscCrossLeftParkable 3 "SNA" 0 "NONE" 2 "PARKING_SLOT_OK_POSITION_OK" 1 "PARKING_SLOT_OK" ;
VAL_ 542 PARK_pscMaxVelocity 63 "SNA" ;
VAL_ 542 PARK_pscCrossRightParkable 3 "SNA" 0 "NONE" 2 "PARKING_SLOT_OK_POSITION_OK" 1 "PARKING_SLOT_OK" ;
VAL_ 542 PARK_pscParallelLeftParkable 3 "SNA" 0 "NONE" 2 "PARKING_SLOT_OK_POSITION_OK" 1 "PARKING_SLOT_OK" ;
VAL_ 542 PARK_pscParallelRightParkable 3 "SNA" 0 "NONE" 2 "PARKING_SLOT_OK_POSITION_OK" 1 "PARKING_SLOT_OK" ;
VAL_ 542 PARK_pscCrossSpace 0 "NONE_AVAILABLE" 3 "BOTH_AVAILABLE" 2 "LEFT_AVAILABLE" 1 "RIGHT_AVAILABLE" ;
VAL_ 542 PARK_pscParallelSpace 0 "NONE_AVAILABLE" 3 "BOTH_AVAILABLE" 2 "LEFT_AVAILABLE" 1 "RIGHT_AVAILABLE" ;
VAL_ 542 PARK_pscParkAbortReason 31 "SNA" 17 "SYSTEM_SERVICE" 11 "HANDS_ON_DETECTED" 6 "MAX_SWA_DEV_EXCEEDED" 0 "NONE" 8 "OBSTACLE_ON_PATH" 1 "VELOCITY_TOO_HIGH" 18 "ERROR" 12 "VEHICLE_DYNAMICS_INTERVENTION" 15 "ECU_INTERNAL_FAULT" 10 "FULL_WARNING_ON_BOTH_SIDES" 5 "OFF_TRACK" 13 "EPAS_FAULT" 3 "NO_VALID_PATH" 9 "PARK_SPACE_TOO_SMALL" 4 "UNCONTROLLED_TRAVEL_DIST_REACHED" 16 "SYSTEM_FAULT" 14 "DAS_ABORT" 2 "MAX_NUM_OF_MOVES" 7 "MAX_YAW_ANGLE_REACHED" ;
VAL_ 542 PARK_pscParkStatus 7 "SNA" 5 "GUIDANCE_FINISHED" 6 "FAULT" 2 "GUIDANCE_LEFT" 0 "NOT_AVAILABLE" 4 "PRE_GUIDANCE" 1 "SEARCHING" 3 "GUIDANCE_RIGHT" ;
VAL_ 585 SCCM_turnIndicatorStalkStatus 3 "DOWN_1" 5 "SNA" 0 "IDLE" 1 "UP_1" 4 "DOWN_2" 2 "UP_2" ;
VAL_ 585 SCCM_washWipeButtonStatus 3 "SNA" 0 "NOT_PRESSED" 2 "2ND_DETENT" 1 "1ST_DETENT" ;
VAL_ 585 SCCM_highBeamStalkStatus 3 "SNA" 0 "IDLE" 1 "PULL" 2 "PUSH" ;
VAL_ 798 PARK_subMinorVersion 255 "SNA" ;
VAL_ 798 PARK_minorVersion 255 "SNA" ;
VAL_ 798 PARK_majorVersion 255 "SNA" ;
VAL_ 798 PARK_systemDtcPresent 3 "SNA" 0 "FALSE" 1 "TRUE" 2 "UNUSED" ;
VAL_ 798 PARK_serviceRequest 3 "SNA" 0 "NO_FAILURE" 2 "UNUSED" 1 "FAILURE" ;
VAL_ 798 PARK_status 3 "SNA" 2 "TEMPORARY_FAILURE" 1 "ENABLED" 0 "DISABLED" ;
VAL_ 1048 GTW_chWakeUpReason 1 "GTW_WAKEUP_REASON_RESET" 8 "GTW_WAKEUP_REASON_UI_SCHEDULED" 6 "GTW_WAKEUP_REASON_VCFRONT" 2 "GTW_WAKEUP_REASON_GSM_RI" 5 "GTW_WAKEUP_REASON_VEH_CAN" 3 "GTW_WAKEUP_REASON_CH_CAN" 4 "GTW_WAKEUP_REASON_ETH_CAN" 0 "GTW_WAKEUP_REASON_NONE" 7 "GTW_WAKEUP_REASON_RTC_ALARM" ;
VAL_ 280 DI_trackModeState 0 "TRACK_MODE_UNAVAILABLE" 1 "TRACK_MODE_AVAILABLE" 2 "TRACK_MODE_ON" ;
VAL_ 280 DI_keepAliveRequest 1 "KEEP_ALIVE" 0 "NO_REQUEST" ;
VAL_ 280 DI_epbRequest 0 "DI_EPBREQUEST_NO_REQUEST" 1 "DI_EPBREQUEST_PARK" 2 "DI_EPBREQUEST_UNPARK" ;
VAL_ 280 DI_tractionControlMode 0 "TC_NORMAL" 1 "TC_SLIP_START" 4 "TC_ROLLS_MODE" 2 "TC_DEV_MODE_1" 5 "TC_DYNO_MODE" 3 "TC_DEV_MODE_2" ;
VAL_ 280 DI_accelPedalPos 255 "SNA" ;
VAL_ 280 DI_immobilizerState 2 "DI_IMM_STATE_AUTHENTICATING" 0 "DI_IMM_STATE_INIT_SNA" 3 "DI_IMM_STATE_DISARMED" 4 "DI_IMM_STATE_IDLE" 6 "DI_IMM_STATE_FAULT" 1 "DI_IMM_STATE_REQUEST" 5 "DI_IMM_STATE_RESET" ;
VAL_ 280 DI_gear 1 "DI_GEAR_P" 0 "DI_GEAR_INVALID" 7 "DI_GEAR_SNA" 2 "DI_GEAR_R" 3 "DI_GEAR_N" 4 "DI_GEAR_D" ;
VAL_ 280 DI_brakePedalState 2 "INVALID" 0 "OFF" 1 "ON" ;
VAL_ 280 DI_systemState 5 "DI_SYS_ENABLE" 1 "DI_SYS_IDLE" 2 "DI_SYS_STANDBY" 0 "DI_SYS_UNAVAILABLE" 3 "DI_SYS_FAULT" 4 "DI_SYS_ABORT" ;
VAL_ 698 UI_radarTargetDxEnd 255 "NO_OBJECT" ;
VAL_ 698 UI_radarTargetDx 255 "NO_OBJECT" ;
VAL_ 697 DAS_accelMax 511 "SNA" ;
VAL_ 697 DAS_accelMin 511 "SNA" ;
VAL_ 697 DAS_jerkMax 255 "SNA" ;
VAL_ 697 DAS_jerkMin 511 "SNA" ;
VAL_ 697 DAS_aebEvent 2 "AEB_FAULT" 0 "AEB_NOT_ACTIVE" 3 "AEB_SNA" 1 "AEB_ACTIVE" ;
VAL_ 697 DAS_accState 4 "ACC_ON" 9 "APC_PAUSE" 14 "ACC_CANCEL_OUT_OF_CALIBRATION" 10 "APC_UNPARK_COMPLETE" 6 "APC_FORWARD" 3 "ACC_HOLD" 2 "ACC_CANCEL_RADAR_BLIND" 7 "APC_COMPLETE" 1 "ACC_CANCEL_CAMERA_BLIND" 8 "APC_ABORT" 13 "ACC_CANCEL_GENERIC_SILENT" 5 "APC_BACKWARD" 11 "APC_SELFPARK_START" 0 "ACC_CANCEL_GENERIC" 12 "ACC_CANCEL_PATH_NOT_CLEAR" 15 "FAULT_SNA" ;
VAL_ 697 DAS_setSpeed 4095 "SNA" ;
VAL_ 389 ESP_brakeTorqueQF 1 "IN_SPEC" 0 "UNDEFINABLE_ACCURACY" ;
VAL_ 389 ESP_brakeTorqueReR 4095 "SNA" ;
VAL_ 389 ESP_brakeTorqueReL 4095 "SNA" ;
VAL_ 389 ESP_brakeTorqueFrR 4095 "SNA" ;
VAL_ 389 ESP_brakeTorqueFrL 4095 "SNA" ;
VAL_ 537 DAS_eacState 7 "SNA" 2 "EAC_ACTIVE" 4 "LANE_KEEP_ASSIST" 3 "EAC_FAULT" 1 "EAC_AVAILABLE" 5 "EMERGENCY_LANE_KEEP" 0 "EAC_INHIBITED" ;
VAL_ 537 DAS_pscParkState 15 "SNA" 7 "ABORT" 0 "NONE" 2 "PARK_LEFT_CROSS" 1 "PARK_LEFT_PARALLEL" 5 "PARALLEL_PULL_OUT_TO_LEFT" 6 "PARALLEL_PULL_OUT_TO_RIGHT" 14 "SUMMON" 10 "PAUSE" 3 "PARK_RIGHT_PARALLEL" 9 "SEARCH" 4 "PARK_RIGHT_CROSS" 8 "COMPLETE" ;
VAL_ 861 IBST_matrixIndex 2 "IBST_AlertMatrix2" 0 "IBST_AlertMatrix0" 1 "IBST_AlertMatrix1" ;
VAL_ 632 UI_roadCurvHealth 3 "DATABASE" 0 "UNAVAILABLE" 1 "DEGRADED" 2 "AVAILABLE" ;
VAL_ 987 UI_phoneGpsAccuracy 127 "SNA" ;
VAL_ 637 APS_eacAllow 1 "APS_EAC_ALLOW" 3 "APS_EAC_SNA" 2 "APS_EAC_RESERVED" 0 "APS_EAC_INHIBIT" ;
VAL_ 937 DAS_telRightLaneCrossing 0 "NOT_CROSSING" 1 "CROSSING" ;
VAL_ 937 DAS_telLeftLaneCrossing 0 "NOT_CROSSING" 1 "CROSSING" ;
VAL_ 937 DAS_telRightMarkerColor 1 "WHITE" 0 "UNKNOWN" 2 "YELLOW" 3 "BLUE" ;
VAL_ 937 DAS_telLeftMarkerColor 1 "WHITE" 0 "UNKNOWN" 2 "YELLOW" 3 "BLUE" ;
VAL_ 937 DAS_telRightMarkerQuality 1 "LOW" 2 "MEDIUM" 0 "LOWEST" 3 "HIGH" ;
VAL_ 937 DAS_telLeftMarkerQuality 1 "LOW" 2 "MEDIUM" 0 "LOWEST" 3 "HIGH" ;
VAL_ 937 DAS_soRad1Status 0 "RAD1_INVALID" 2 "RAD1_FUSED_W_CIPV" 1 "RAD1_UNFUSED" 3 "RAD1_FUSED_W_OTHER_CAMOBJ" ;
VAL_ 937 DAS_telRightLaneType 2 "ROAD_EDGE" 0 "UNDECIDED" 6 "BARRIER" 1 "SOLID" 4 "DOUBLE" 3 "DASHED" 5 "BOTTS_DOTS" ;
VAL_ 937 DAS_soRad5Status 3 "RAD5_FUSED_W_OTHER_CAMOBJ" 0 "RAD5_INVALID" 1 "RAD5_UNFUSED" 2 "RAD5_FUSED_W_CIPV" ;
VAL_ 937 DAS_telLeftLaneType 2 "ROAD_EDGE" 0 "UNDECIDED" 6 "BARRIER" 1 "SOLID" 4 "DOUBLE" 3 "DASHED" 5 "BOTTS_DOTS" ;
VAL_ 937 DAS_soCamCipvStatus 2 "CAM_CIPV_FUSED_W_OTHER_RAD_OBJ" 3 "CAM_CIPV_FUSED_W_RAD5" 0 "CAM_CIPV_INVALID" 1 "CAM_CIPV_UNFUSED" ;
VAL_ 937 DAS_telemetryMultiplexer 9 "DAS_TELEMETRY_CRUISE_STALK_INPUT" 7 "DAS_TELEMETRY_CSA_EVENT" 8 "DAS_TELEMETRY_STATIONARY_OBST" 0 "DAS_TELEMETRY_ROAD_INFORMATION" 1 "DAS_TELEMETRY_ACC_DRIVER_MONITOR" 2 "DAS_TELEMETRY_TRAFFIC_SIGNS" ;
VAL_ 801 VCFRONT_tempAmbientFiltered 0 "SNA" ;
VAL_ 801 VCFRONT_washerFluidLevel 1 "LOW" 0 "SNA" 2 "NORMAL" ;
VAL_ 801 VCFRONT_tempAmbient 0 "SNA" ;
VAL_ 801 VCFRONT_brakeFluidLevel 1 "LOW" 0 "SNA" 2 "NORMAL" ;
VAL_ 801 VCFRONT_coolantLevel 1 "FILLED" 0 "NOT_OK" ;
VAL_ 801 VCFRONT_tempCoolantPTInlet 2047 "SNA" ;
VAL_ 801 VCFRONT_tempCoolantBatInlet 1023 "SNA" ;
VAL_ 341 ESP_vehicleSpeed 1023 "ESP_VEHICLE_SPEED_SNA" ;
VAL_ 341 ESP_vehicleStandstillSts 1 "STANDSTILL" 0 "NOT_STANDSTILL" ;
VAL_ 341 ESP_wheelSpeedsQF 0 "ONE_OR_MORE_WSS_INVALID" 1 "ALL_WSS_VALID" ;
VAL_ 341 ESP_WheelRotationFrL 1 "WR_BACKWARD" 0 "WR_FORWARD" 3 "WR_NOT_DEFINABLE" 2 "WR_STANDSTILL" ;
VAL_ 341 ESP_WheelRotationFrR 1 "WR_BACKWARD" 0 "WR_FORWARD" 3 "WR_NOT_DEFINABLE" 2 "WR_STANDSTILL" ;
VAL_ 341 ESP_WheelRotationReL 1 "WR_BACKWARD" 0 "WR_FORWARD" 3 "WR_NOT_DEFINABLE" 2 "WR_STANDSTILL" ;
VAL_ 341 ESP_WheelRotationReR 1 "WR_BACKWARD" 0 "WR_FORWARD" 3 "WR_NOT_DEFINABLE" 2 "WR_STANDSTILL" ;
VAL_ 341 ESP_wheelPulseCountReR 255 "SNA" ;
VAL_ 341 ESP_wheelPulseCountReL 255 "SNA" ;
VAL_ 341 ESP_wheelPulseCountFrR 255 "SNA" ;
VAL_ 341 ESP_wheelPulseCountFrL 255 "SNA" ;
VAL_ 1018 APP_backupCameraLUX 255 "CAMERA_LUX_SNA" 254 "CAMERA_LUX_SATURATED" ;
VAL_ 1018 APP_rPillarCameraLUX 255 "CAMERA_LUX_SNA" 254 "CAMERA_LUX_SATURATED" ;
VAL_ 1018 APP_lPillarCameraLUX 255 "CAMERA_LUX_SNA" 254 "CAMERA_LUX_SATURATED" ;
VAL_ 1018 APP_rRepeatCameraLUX 255 "CAMERA_LUX_SNA" 254 "CAMERA_LUX_SATURATED" ;
VAL_ 1018 APP_lRepeatCameraLUX 255 "CAMERA_LUX_SNA" 254 "CAMERA_LUX_SATURATED" ;
VAL_ 1018 APP_fisheyeCameraLUX 255 "CAMERA_LUX_SNA" 254 "CAMERA_LUX_SATURATED" ;
VAL_ 1018 APP_narrowCameraLUX 255 "CAMERA_LUX_SNA" 254 "CAMERA_LUX_SATURATED" ;
VAL_ 1018 APP_mainCameraLUX 255 "CAMERA_LUX_SNA" 254 "CAMERA_LUX_SATURATED" ;
VAL_ 785 EPAS3S_infoBuildType 1 "INFO_PLATFORM_BUILD" 3 "INFO_TRACEABLE_CI_BUILD" 4 "INFO_MFG_BUILD" 2 "INFO_LOCAL_BUILD" 0 "INFO_UNKNOWN_BUILD" ;
VAL_ 785 EPAS3S_infoIndex 25 "INFO_PACKAGE_PN_1_7" 30 "INFO_PACKAGE_SN_8_14" 27 "INFO_PACKAGE_PN_15_20" 0 "INFO_DEPRECATED_0" 29 "INFO_PACKAGE_SN_1_7" 10 "INFO_BUILD_HWID_COMPONENTID" 14 "INFO_BOOTLOADER_SVN" 31 "INFO_SUBCOMPONENT_GITHASH" 19 "INFO_VERSION_DEPRECATED" 7 "INFO_DEPRECATED_7" 255 "INFO_END" 9 "INFO_DEPRECATED_9" 6 "INFO_DEPRECATED_6" 20 "INFO_UDS_PROTOCOL_BOOTCRC" 3 "INFO_DEPRECATED_3" 22 "INFO_VARIANTCRC" 17 "INFO_APP_GITHASH" 8 "INFO_DEPRECATED_8" 26 "INFO_PACKAGE_PN_8_14" 5 "INFO_DEPRECATED_5" 16 "INFO_SUBCOMPONENT" 13 "INFO_APP_CRC" 2 "INFO_DEPRECATED_2" 4 "INFO_DEPRECATED_4" 15 "INFO_BOOTLOADER_CRC" 1 "INFO_DEPRECATED_1" 11 "INFO_PCBAID_ASSYID_USAGEID" 18 "INFO_BOOTLOADER_GITHASH" ;
VAL_ 890 DAS_TP_rlType 4 "DOUBLE_LANE" 2 "ROAD_EDGE" 0 "UNDECIDED" 6 "BARRIER" 1 "SOLID" 7 "INVALID" 3 "DASHED" 5 "BOTTS_DOTS" ;
VAL_ 890 DAS_TP_llType 4 "DOUBLE_LANE" 2 "ROAD_EDGE" 0 "UNDECIDED" 6 "BARRIER" 1 "SOLID" 7 "INVALID" 3 "DASHED" 5 "BOTTS_DOTS" ;
VAL_ 890 DAS_TP_multiplexer 1 "LEFT_LANE" 5 "VIRTUAL_LANE" 0 "START" 2 "RIGHT_LANE" 4 "NAV" 9 "END" 8 "LANE_INFO" 7 "RIGHT_BOTTS_DOTS" 3 "HPP" 6 "LEFT_BOTTS_DOTS" ;
VAL_ 1037 TAS_nmWakeUpReason 0 "CH_WAKEUP_REASON_NONE" 3 "CH_WAKEUP_REASON_RESET" 2 "CH_WAKEUP_REASON_SWITCH_INPUT" 1 "CH_WAKEUP_REASON_ECU_SPECIFIC" ;
VAL_ 1037 TAS_nmKeepAwakeReason 1 "TAS_KEEPAWAKE_REASON_LEVELING_IN_PROGRESS" 0 "TAS_KEEPAWAKE_REASON_NONE_SNA" 15 "TAS_KEEPAWAKE_REASON_MULTIPLE" ;
